VERSION ""

NS_ :

BS_:

BU_: AAF AAF_Tester ABS ACU ADRV AEMC AFLS AHLS APRK AVM BCM CAMERA CGW CLU CUBIS DATC DI_BOX Dummy ECS EMS EPB ESC EVP FATC FPCM FRONT_RADAR HUD IAP IBOX LCA LDWS_LKAS LPI LVR MDPS MTS ODS OPI PGS PSB REA SAS SCC SMK SNV SPAS TCU TMU TPMS _4WD

BS_:

BU_: XXX CAMERA FRONT_RADAR ADRV APRK

BS_:

BU_: IAP ODS _4WD BCM HUD DATC MDPS AAF_Tester AEMC SMK _4WD EPB CUBIS MTS TMU EVP CGW TPMS LPI DI_BOX SPAS EMS LCA TCU IBOX FATC AFLS FPCM SCC AHLS AVM ABS SNV OPI PGS SAS AAF Dummy LDWS_LKAS LVR ESC PSB CLU ECS ACU REA

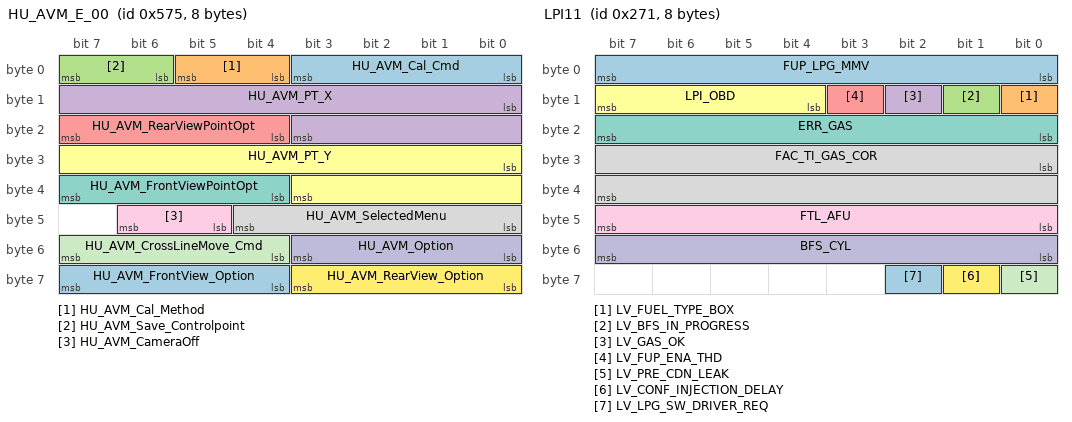
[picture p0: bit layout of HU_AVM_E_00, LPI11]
BO_ 1397 HU_AVM_E_00: 8 CLU
 SG_ HU_AVM_Cal_Cmd : 0|4@1+ (1.0,0.0) [0.0|15.0] ""  AVM,PGS
 SG_ HU_AVM_Cal_Method : 4|2@1+ (1.0,0.0) [0.0|3.0] ""  AVM,PGS
 SG_ HU_AVM_Save_Controlpoint : 6|2@1+ (1.0,0.0) [0.0|3.0] ""  AVM,PGS
 SG_ HU_AVM_PT_X : 8|12@1+ (1.0,0.0) [0.0|15.0] ""  AVM,PGS
 SG_ HU_AVM_RearViewPointOpt : 20|4@1+ (1.0,0.0) [0.0|15.0] ""  AVM,PGS
 SG_ HU_AVM_PT_Y : 24|12@1+ (1.0,0.0) [0.0|4095.0] ""  AVM,PGS
 SG_ HU_AVM_FrontViewPointOpt : 36|4@1+ (1.0,0.0) [0.0|15.0] ""  AVM,PGS
 SG_ HU_AVM_SelectedMenu : 40|5@1+ (1.0,0.0) [0.0|31.0] ""  AVM,PGS
 SG_ HU_AVM_CameraOff : 45|2@1+ (1.0,0.0) [0.0|3.0] ""  AVM,PGS
 SG_ HU_AVM_Option : 48|4@1+ (1.0,0.0) [0.0|15.0] ""  AVM,PGS
 SG_ HU_AVM_CrossLineMove_Cmd : 52|4@1+ (1.0,0.0) [0.0|15.0] ""  AVM,PGS
 SG_ HU_AVM_RearView_Option : 56|4@1+ (1.0,0.0) [0.0|15.0] ""  AVM,PGS
 SG_ HU_AVM_FrontView_Option : 60|4@1+ (1.0,0.0) [0.0|15.0] ""  AVM,PGS

BO_ 1395 HU_AVM_E_01: 8 CLU
 SG_ HU_PGSSelectedMenu : 0|4@1+ (1.0,0.0) [0.0|15.0] ""  AVM,PGS
 SG_ HU_PGSOption : 8|5@1+ (1.0,0.0) [0.0|31.0] ""  AVM,PGS
 SG_ HU_AVM_ParkingAssistMenu : 56|4@1+ (1.0,0.0) [0.0|15.0] ""  AVM,PGS
 SG_ HU_AVM_ParkingAssistSB : 60|4@1+ (1.0,0.0) [0.0|15.0] ""  AVM,PGS

BO_ 1393 OPI11: 5 OPI
 SG_ CR_Opi_Spd_Rpm : 0|8@1+ (20.0,0.0) [0.0|3500.0] "rpm"  TCU
 SG_ CF_Opi_Over_Temp : 8|1@1+ (1.0,0.0) [0.0|1.0] ""  TCU
 SG_ CF_Opi_Over_Cur : 9|1@1+ (1.0,0.0) [0.0|1.0] ""  EMS,TCU
 SG_ CF_Opi_Over_Vol : 10|1@1+ (1.0,0.0) [0.0|1.0] ""  TCU
 SG_ CF_Opi_Hall_Fail : 11|1@1+ (1.0,0.0) [0.0|1.0] ""  EMS,TCU
 SG_ CF_Opi_Flt : 12|1@1+ (1.0,0.0) [0.0|1.0] ""  EMS,TCU
 SG_ CF_Opi_Motor_Dir : 15|1@1+ (1.0,0.0) [0.0|1.0] ""  TCU
 SG_ CF_Opi_Romver : 16|8@1+ (1.0,0.0) [0.0|255.0] ""  TCU
 SG_ CF_Opi_PWM_Rate : 24|12@1+ (1.0,0.0) [0.0|100.0] "%"  TCU

BO_ 625 LPI11: 8 LPI
 SG_ FUP_LPG_MMV : 0|8@1+ (128.0,0.0) [0.0|32640.0] "hPa"  EMS
 SG_ LV_FUEL_TYPE_BOX : 8|1@1+ (1.0,0.0) [0.0|1.0] ""  EMS
 SG_ LV_BFS_IN_PROGRESS : 9|1@1+ (1.0,0.0) [0.0|1.0] ""  EMS
 SG_ LV_GAS_OK : 10|1@1+ (1.0,0.0) [0.0|1.0] ""  EMS
 SG_ LV_FUP_ENA_THD : 11|1@1+ (1.0,0.0) [0.0|1.0] ""  BCM,CLU,EMS,SMK
 SG_ LPI_OBD : 12|4@1+ (1.0,0.0) [0.0|15.0] ""  EMS
 SG_ ERR_GAS : 16|8@1+ (1.0,0.0) [0.0|255.0] ""  EMS
 SG_ FAC_TI_GAS_COR : 24|16@1+ (3.05E-5,0.0) [0.0|1.9988175] ""  EMS
 SG_ FTL_AFU : 40|8@1+ (0.392,0.0) [0.0|99.96] "%"  EMS
 SG_ BFS_CYL : 48|8@1+ (1.0,0.0) [0.0|6.0] "Cyl Nr."  EMS
 SG_ LV_PRE_CDN_LEAK : 56|1@1+ (1.0,0.0) [0.0|1.0] ""  EMS
 SG_ LV_CONF_INJECTION_DELAY : 57|1@1+ (1.0,0.0) [0.0|1.0] ""  EMS
 SG_ LV_LPG_SW_DRIVER_REQ : 58|1@1+ (1.0,0.0) [0.0|1.0] ""  EMS

BO_ 356 VSM11: 4 ESC
 SG_ CR_Esc_StrTqReq : 0|12@1+ (0.01,-20.48) [-20.48|20.47] "Nm"  MDPS
 SG_ CF_Esc_Act : 12|1@1+ (1.0,0.0) [0.0|1.0] ""  LDWS_LKAS,MDPS
 SG_ CF_Esc_CtrMode : 13|3@1+ (1.0,0.0) [0.0|7.0] ""  MDPS
 SG_ CF_Esc_Def : 16|1@1+ (1.0,0.0) [0.0|1.0] ""  MDPS
 SG_ CF_Esc_AliveCnt : 17|4@1+ (1.0,0.0) [0.0|15.0] ""  LDWS_LKAS,MDPS
 SG_ CF_Esc_Chksum : 24|8@1+ (1.0,0.0) [0.0|255.0] ""  LDWS_LKAS,MDPS

BO_ 1379 PGS_HU_PE_01: 8 PGS
 SG_ PGS_State : 0|4@1+ (1.0,0.0) [0.0|15.0] ""  CLU
 SG_ PGS_ParkGuideState : 8|5@1+ (1.0,0.0) [0.0|31.0] ""  CLU
 SG_ PGS_Option : 16|5@1+ (1.0,0.0) [0.0|31.0] ""  CLU
 SG_ PGS_Version : 32|16@1+ (1.0,0.0) [0.0|65535.0] ""  CLU

BO_ 1378 HUD11: 4 HUD
 SG_ CF_Hud_HeightStaus : 0|5@1+ (1.0,0.0) [0.0|31.0] ""  CLU
 SG_ CF_Hud_PBackStatus : 6|2@1+ (1.0,0.0) [0.0|0.0] ""  BCM,CLU
 SG_ CF_Hud_Brightness : 8|5@1+ (1.0,0.0) [0.0|31.0] ""  CLU

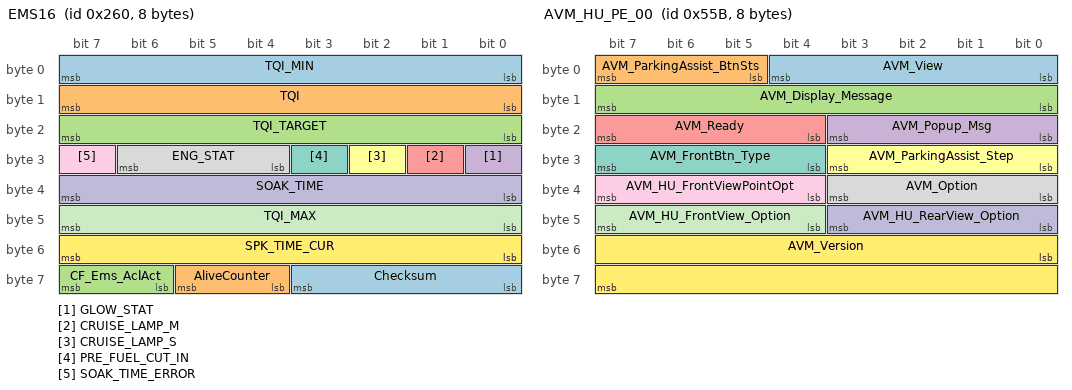
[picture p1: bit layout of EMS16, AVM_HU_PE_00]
BO_ 608 EMS16: 8 EMS
 SG_ TQI_MIN : 0|8@1+ (0.390625,0.0) [0.0|99.609375] "%"  ESC,IBOX,TCU
 SG_ TQI : 8|8@1+ (0.390625,0.0) [0.0|99.609375] "%"  ESC,IBOX,TCU
 SG_ TQI_TARGET : 16|8@1+ (0.390625,0.0) [0.0|99.609375] "%"  EPB,ESC,IBOX,TCU
 SG_ GLOW_STAT : 24|1@1+ (1.0,0.0) [0.0|1.0] ""  BCM,CLU,IBOX,SMK
 SG_ CRUISE_LAMP_M : 25|1@1+ (1.0,0.0) [0.0|1.0] ""  CLU,IBOX,TCU
 SG_ CRUISE_LAMP_S : 26|1@1+ (1.0,0.0) [0.0|1.0] ""  CLU,IBOX,TCU
 SG_ PRE_FUEL_CUT_IN : 27|1@1+ (1.0,0.0) [0.0|1.0] ""  IBOX,TCU
 SG_ ENG_STAT : 28|3@1+ (1.0,0.0) [0.0|7.0] ""  ABS,AHLS,AVM,BCM,CLU,EPB,ESC,EVP,FPCM,IBOX,LCA,LDWS_LKAS,MDPS,SCC,SMK,TCU
 SG_ SOAK_TIME_ERROR : 31|1@1+ (1.0,0.0) [0.0|1.0] ""  DATC,EPB,IBOX,TCU
 SG_ SOAK_TIME : 32|8@1+ (1.0,0.0) [0.0|255.0] "Min"  _4WD,DATC,EPB,IBOX,TCU
 SG_ TQI_MAX : 40|8@1+ (0.390625,0.0) [0.0|99.609375] "%"  ESC,IBOX,TCU
 SG_ SPK_TIME_CUR : 48|8@1+ (0.375,-35.625) [-35.625|60.0] ""  IBOX,TCU
 SG_ Checksum : 56|4@1+ (1.0,0.0) [0.0|15.0] ""  ECS,IBOX,LDWS_LKAS,MDPS,SCC
 SG_ AliveCounter : 60|2@1+ (1.0,0.0) [0.0|3.0] ""  IBOX,LDWS_LKAS,MDPS,SCC
 SG_ CF_Ems_AclAct : 62|2@1+ (1.0,0.0) [0.0|3.0] ""  IBOX,SCC

BO_ 1371 AVM_HU_PE_00: 8 AVM
 SG_ AVM_View : 0|5@1+ (1.0,0.0) [0.0|31.0] ""  CLU
 SG_ AVM_ParkingAssist_BtnSts : 5|3@1+ (1.0,0.0) [0.0|7.0] ""  CLU
 SG_ AVM_Display_Message : 8|8@1+ (1.0,0.0) [0.0|255.0] ""  CLU
 SG_ AVM_Popup_Msg : 16|4@1+ (1.0,0.0) [0.0|15.0] ""  CLU
 SG_ AVM_Ready : 20|4@1+ (1.0,0.0) [0.0|15.0] ""  CLU
 SG_ AVM_ParkingAssist_Step : 24|4@1+ (1.0,0.0) [0.0|15.0] ""  CLU
 SG_ AVM_FrontBtn_Type : 28|4@1+ (1.0,0.0) [0.0|15.0] ""  CLU
 SG_ AVM_Option : 32|4@1+ (1.0,0.0) [0.0|15.0] ""  CLU
 SG_ AVM_HU_FrontViewPointOpt : 36|4@1+ (1.0,0.0) [0.0|15.0] ""  CLU
 SG_ AVM_HU_RearView_Option : 40|4@1+ (1.0,0.0) [0.0|15.0] ""  CLU
 SG_ AVM_HU_FrontView_Option : 44|4@1+ (1.0,0.0) [0.0|15.0] ""  CLU
 SG_ AVM_Version : 48|16@1+ (1.0,0.0) [0.0|65535.0] ""  CLU

BO_ 1370 HU_AVM_PE_00: 8 CLU
 SG_ HU_AVM_Status : 0|2@1+ (1.0,0.0) [0.0|3.0] ""  AVM,PGS

BO_ 1369 CGW4: 8 BCM
 SG_ CF_Gway_MemoryP1Cmd : 0|1@1+ (1.0,0.0) [0.0|1.0] ""  CLU
 SG_ CF_Gway_MemoryP2Cmd : 1|1@1+ (1.0,0.0) [0.0|1.0] ""  CLU
 SG_ CF_Gway_PBackP1Cmd : 2|1@1+ (1.0,0.0) [0.0|1.0] ""  CLU
 SG_ CF_Gway_PBackP2Cmd : 3|1@1+ (1.0,0.0) [0.0|1.0] ""  CLU
 SG_ CF_Gway_StrgWhlHeatedState : 4|1@1+ (1.0,0.0) [0.0|1.0] ""  CLU
 SG_ CF_Gway_PBackStopCmd : 5|1@1+ (1.0,0.0) [0.0|1.0] ""  CLU,HUD
 SG_ CF_Gway_StaticBendLhAct : 6|1@1+ (1.0,0.0) [0.0|1.0] ""  CLU
 SG_ CF_Gway_StaticBendRhAct : 7|1@1+ (1.0,0.0) [0.0|1.0] ""  CLU
 SG_ CF_Gway_DrvWdwStat : 8|1@1+ (1.0,0.0) [0.0|1.0] ""  CLU
 SG_ CF_Gway_RLWdwState : 9|1@1+ (1.0,0.0) [0.0|1.0] ""  CLU
 SG_ CF_Gway_RRWdwState : 10|1@1+ (1.0,0.0) [0.0|1.0] ""  CLU
 SG_ CF_Gway_AstWdwStat : 11|1@1+ (1.0,0.0) [0.0|1.0] ""  CLU
 SG_ CF_Gway_MemoryEnable : 12|1@1+ (1.0,0.0) [0.0|1.0] ""  CLU
 SG_ CF_Gway_PBACKStopCmd : 13|1@1+ (1.0,0.0) [0.0|1.0] ""  CLU
 SG_ CF_Gway_PBACKStop : 14|1@1+ (1.0,0.0) [0.0|1.0] ""  CLU,HUD
 SG_ CF_Gway_IMSBuzzer : 15|1@1+ (1.0,0.0) [0.0|1.0] ""  CLU
 SG_ CF_Gway_DrvSeatBeltInd : 36|2@1+ (1.0,0.0) [0.0|3.0] ""  CLU,Dummy
 SG_ CF_Gway_AstSeatBeltInd : 38|2@1+ (1.0,0.0) [0.0|3.0] ""  CLU
 SG_ CF_Gway_RCSeatBeltInd : 40|2@1+ (1.0,0.0) [0.0|3.0] ""  CLU
 SG_ CF_Gway_RLSeatBeltInd : 42|2@1+ (1.0,0.0) [0.0|3.0] ""  CLU
 SG_ CF_Gway_RRSeatBeltInd : 44|2@1+ (1.0,0.0) [0.0|3.0] ""  CLU
 SG_ CF_Gway_RrWiperHighSw : 46|1@1+ (1.0,0.0) [0.0|1.0] ""  CLU
 SG_ CF_Gway_RrWiperLowSw : 47|1@1+ (1.0,0.0) [0.0|1.0] ""  CLU

BO_ 1367 EngFrzFrm12: 8 EMS
 SG_ PID_06h : 0|8@1+ (0.78125,-100.0) [-100.0|99.22] "%"  AAF,IBOX,TCU
 SG_ PID_07h : 8|8@1+ (0.78125,-100.0) [-100.0|99.22] "%"  AAF,IBOX,TCU
 SG_ PID_08h : 16|8@1+ (0.78125,-100.0) [-100.0|99.22] "%"  AAF,IBOX,TCU
 SG_ PID_09h : 24|8@1+ (0.78125,-100.0) [-100.0|99.22] "%"  AAF,IBOX,TCU
 SG_ PID_0Bh : 32|8@1+ (1.0,0.0) [0.0|255.0] "kPa"  AAF,IBOX,TCU
 SG_ PID_23h : 40|16@1+ (10.0,0.0) [0.0|655350.0] "kPa"  AAF,IBOX,TCU

BO_ 1366 EngFrzFrm11: 8 EMS
 SG_ PID_04h : 0|8@1+ (0.3921568627,0.0) [0.0|100.0] "%"  AAF,TCU
 SG_ PID_05h : 8|8@1+ (1.0,-40.0) [-40.0|215.0] "deg"  AAF,TCU
 SG_ PID_0Ch : 16|16@1+ (0.25,0.0) [0.0|16383.75] "rpm"  AAF,TCU
 SG_ PID_0Dh : 32|8@1+ (1.0,0.0) [0.0|255.0] "km/h"  AAF,TCU
 SG_ PID_11h : 40|8@1+ (0.3921568627,0.0) [0.0|100.0] "%"  AAF,TCU
 SG_ PID_03h : 48|16@1+ (1.0,0.0) [0.0|65535.0] ""  AAF,TCU

BO_ 1365 FPCM11: 8 FPCM
 SG_ CR_Fpcm_LPActPre : 0|8@1+ (3.137254902,0.0) [0.0|800.0] "kPa"  EMS
 SG_ CF_Fpcm_LPPumpOverCur : 8|1@1+ (1.0,0.0) [0.0|1.0] ""  EMS
 SG_ CF_Fpcm_PreSnrHi : 9|1@1+ (1.0,0.0) [0.0|1.0] ""  EMS
 SG_ CF_Fpcm_PreSnrDisc : 10|1@1+ (1.0,0.0) [0.0|1.0] ""  EMS
 SG_ CF_Fpcm_PreSnrShort : 11|1@1+ (1.0,0.0) [0.0|1.0] ""  EMS
 SG_ CF_Fpcm_LPPumpDiscShort : 12|1@1+ (1.0,0.0) [0.0|1.0] ""  EMS
 SG_ CF_Fpcm_LP_System_Error : 13|1@1+ (1.0,0.0) [0.0|1.0] ""  EMS
 SG_ CF_Fpcm_PreSnrSigErr : 14|1@1+ (1.0,0.0) [0.0|1.0] ""  EMS
 SG_ CF_Fpcm_LPCtrCirFlt : 15|1@1+ (1.0,0.0) [0.0|1.0] ""  EMS

BO_ 871 LVR12: 8 LVR
 SG_ CF_Lvr_CruiseSet : 0|8@1+ (1.0,0.0) [0.0|255.0] "" CLU,TCU
 SG_ CF_Lvr_IsgState : 8|2@1+ (1.0,0.0) [0.0|3.0] "" CLU,TCU
 SG_ CF_Lvr_Gear : 32|4@1+ (1.0,0.0) [0.0|15.0] ""  CLU,TCU

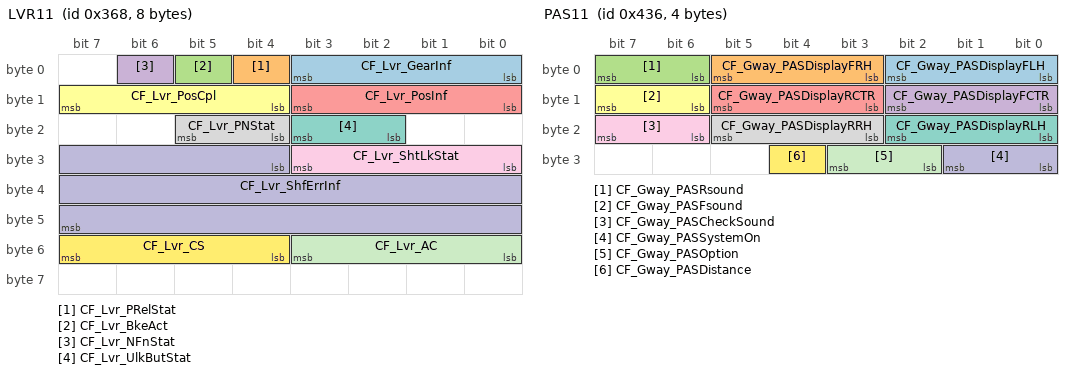
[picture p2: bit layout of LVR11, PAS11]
BO_ 872 LVR11: 8 LVR
 SG_ CF_Lvr_GearInf : 0|4@1+ (1.0,0.0) [0.0|15.0] ""  CLU,TCU
 SG_ CF_Lvr_PRelStat : 4|1@1+ (1.0,0.0) [0.0|1.0] ""  BCM,CLU,SMK,TCU
 SG_ CF_Lvr_BkeAct : 5|1@1+ (1.0,0.0) [0.0|1.0] ""  TCU
 SG_ CF_Lvr_NFnStat : 6|1@1+ (1.0,0.0) [0.0|1.0] ""  CLU
 SG_ CF_Lvr_PosInf : 8|4@1+ (1.0,0.0) [0.0|15.0] ""  TCU
 SG_ CF_Lvr_PosCpl : 12|4@1+ (1.0,0.0) [0.0|15.0] ""  TCU
 SG_ CF_Lvr_UlkButStat : 18|2@1+ (1.0,0.0) [0.0|3.0] ""  TCU
 SG_ CF_Lvr_PNStat : 20|2@1+ (1.0,0.0) [0.0|3.0] ""  CLU
 SG_ CF_Lvr_ShtLkStat : 24|4@1+ (1.0,0.0) [0.0|15.0] ""  TCU
 SG_ CF_Lvr_ShfErrInf : 28|20@1+ (1.0,0.0) [0.0|8191.0] ""  CLU,TCU
 SG_ CF_Lvr_AC : 48|4@1+ (1.0,0.0) [0.0|15.0] ""  TCU
 SG_ CF_Lvr_CS : 52|4@1+ (1.0,0.0) [0.0|15.0] ""  TCU

BO_ 1363 CGW2: 8 BCM
 SG_ CF_Gway_GwayDiagState : 0|1@1+ (1.0,0.0) [0.0|3.0] ""  CLU,Dummy
 SG_ CF_Gway_DDMDiagState : 1|1@1+ (1.0,0.0) [0.0|1.0] ""  CLU,Dummy
 SG_ CF_Gway_SCMDiagState : 2|1@1+ (1.0,0.0) [0.0|1.0] ""  CLU,Dummy
 SG_ CF_Gway_PSMDiagState : 3|1@1+ (1.0,0.0) [0.0|1.0] ""  CLU,Dummy
 SG_ CF_Gway_SJBDiagState : 4|1@1+ (1.0,0.0) [0.0|1.0] ""  CLU,Dummy
 SG_ CF_Gway_IPMDiagState : 5|1@1+ (1.0,0.0) [0.0|1.0] ""  CLU,Dummy
 SG_ CF_Gway_LDMFail : 6|2@1+ (1.0,0.0) [0.0|3.0] ""  CLU,LDWS_LKAS,LDWS_LKAS
 SG_ CF_Gway_CLUSwGuiCtrl : 10|3@1+ (1.0,0.0) [0.0|63.0] ""  CLU,Dummy
 SG_ CF_Gway_CLUSwGroup : 13|1@1+ (1.0,0.0) [0.0|1.0] ""  CLU,Dummy
 SG_ CF_Gway_CLUSwMode : 14|1@1+ (1.0,0.0) [0.0|1.0] ""  CLU,Dummy
 SG_ CF_Gway_CLUSwEnter : 15|1@1+ (1.0,0.0) [0.0|1.0] ""  CLU,Dummy
 SG_ CF_Gway_AutoLightValue : 16|1@1+ (1.0,0.0) [0.0|1.0] ""  LCA,LCA
 SG_ CF_Gway_BrakeFluidSw : 17|1@1+ (1.0,0.0) [0.0|1.0] ""  CLU,Dummy
 SG_ CF_Gway_DrvSeatBeltInd : 18|2@1+ (1.0,0.0) [0.0|3.0] ""  CLU
 SG_ CF_Gway_AvTail : 20|1@1+ (1.0,0.0) [0.0|3.0] ""  CLU,SNV,SNV
 SG_ CF_Gway_RearFogAct : 21|1@1+ (1.0,0.0) [0.0|1.0] ""  CLU,Dummy
 SG_ CF_Gway_ExtTailAct : 22|1@1+ (1.0,0.0) [0.0|1.0] ""  AVM,CLU,LCA,PGS,SPAS,AVM,LCA,PGS,SPAS
 SG_ CF_Gway_RRDrSw : 23|1@1+ (1.0,0.0) [0.0|1.0] ""  CLU,Dummy
 SG_ CF_Gway_RLDrSw : 24|1@1+ (1.0,0.0) [0.0|1.0] ""  CLU,Dummy
 SG_ CF_Gway_IntTailAct : 25|1@1+ (1.0,0.0) [0.0|1.0] ""  CLU,Dummy
 SG_ CF_Gway_CountryCfg : 26|3@1+ (1.0,0.0) [0.0|7.0] ""  AVM,CLU,PGS,Dummy
 SG_ CF_Gway_WiperParkPosition : 32|1@1+ (1.0,0.0) [0.0|1.0] ""  AFLS,EMS,LDWS_LKAS,AFLS,EMS,LDWS_LKAS
 SG_ CF_Gway_HLLowLHFail : 33|1@1+ (1.0,0.0) [0.0|1.0] ""  LDWS_LKAS,SNV,LDWS_LKAS,SNV
 SG_ CF_Gway_HLLowRHFail : 34|1@1+ (1.0,0.0) [0.0|1.0] ""  LDWS_LKAS,SNV,LDWS_LKAS,SNV
 SG_ CF_Gway_ESCLFailWarn : 35|1@1+ (1.0,0.0) [0.0|1.0] ""  CLU,Dummy
 SG_ CF_Gway_ESCLNotLockedWarn : 36|1@1+ (1.0,0.0) [0.0|1.0] ""  CLU,Dummy
 SG_ CF_Gway_ESCLNotUnlockWarn : 37|1@1+ (1.0,0.0) [0.0|1.0] ""  CLU,Dummy
 SG_ CF_Gway_IDoutWarn : 38|1@1+ (1.0,0.0) [0.0|1.0] ""  CLU,Dummy
 SG_ CF_Gway_ImmoLp : 40|1@1+ (1.0,0.0) [0.0|3.0] ""  CLU,Dummy
 SG_ CF_Gway_BCMRKEID : 41|3@1+ (1.0,0.0) [0.0|7.0] ""  CLU,Dummy
 SG_ CF_Gway_VehicleNotPWarn : 44|1@1+ (1.0,0.0) [0.0|1.0] ""  CLU,Dummy
 SG_ CF_Gway_DeactivationWarn : 45|1@1+ (1.0,0.0) [0.0|1.0] ""  CLU,Dummy
 SG_ CF_Gway_KeyBATDischargeWarn : 46|1@1+ (1.0,0.0) [0.0|1.0] ""  CLU,Dummy
 SG_ CF_Gway_SSBWarn : 47|1@1+ (1.0,0.0) [0.0|1.0] ""  CLU,Dummy
 SG_ CF_Gway_SMKFobID : 48|3@1+ (1.0,0.0) [0.0|7.0] ""  CLU,Dummy
 SG_ CF_Gway_SMKRKECmd : 51|3@1+ (1.0,0.0) [0.0|7.0] ""  CLU,Dummy
 SG_ CF_Gway_AutoLightOption : 54|1@1+ (1.0,0.0) [0.0|1.0] ""  CLU
 SG_ CF_Gway_SJBDeliveryMode : 55|1@1+ (1.0,0.0) [0.0|1.0] ""  CLU,Dummy
 SG_ CF_Gway_KeyoutLp : 56|1@1+ (1.0,0.0) [0.0|1.0] ""  CLU,Dummy
 SG_ CF_Gway_SMKDispWarn : 57|4@1+ (1.0,0.0) [0.0|15.0] ""  CLU,Dummy
 SG_ CF_Gway_WngBuz : 61|3@1+ (1.0,0.0) [0.0|7.0] ""  CLU,Dummy

BO_ 339 TCS11: 8 ESC
 SG_ TCS_REQ : 0|1@1+ (1.0,0.0) [0.0|1.0] ""  _4WD,EMS,EPB,TCU
 SG_ MSR_C_REQ : 1|1@1+ (1.0,0.0) [0.0|1.0] ""  EMS,EPB,SCC,TCU
 SG_ TCS_PAS : 2|1@1+ (1.0,0.0) [0.0|1.0] ""  _4WD,CLU,EMS,SCC,SPAS,TCU
 SG_ TCS_GSC : 3|1@1+ (1.0,0.0) [0.0|1.0] ""  _4WD,EMS,TCU
 SG_ CF_Esc_LimoInfo : 4|2@1+ (1.0,0.0) [0.0|3.0] ""  _4WD,SCC
 SG_ ABS_DIAG : 6|1@1+ (1.0,0.0) [0.0|1.0] ""  _4WD,CLU,EMS,EPB
 SG_ ABS_DEF : 7|1@1+ (1.0,0.0) [0.0|1.0] ""  _4WD,ACU,ECS,EMS,EPB,SCC,SPAS,TCU
 SG_ TCS_DEF : 8|1@1+ (1.0,0.0) [0.0|1.0] ""  _4WD,EMS,EPB,SCC,SPAS,TCU
 SG_ TCS_CTL : 9|1@1+ (1.0,0.0) [0.0|1.0] ""  _4WD,EMS,EPB,SCC,SPAS,TCU
 SG_ ABS_ACT : 10|1@1+ (1.0,0.0) [0.0|1.0] ""  _4WD,ACU,ECS,EMS,EPB,LDWS_LKAS,SCC,SPAS,TCU
 SG_ EBD_DEF : 11|1@1+ (1.0,0.0) [0.0|1.0] ""  _4WD,EMS,EPB,SPAS,TCU
 SG_ ESP_PAS : 12|1@1+ (1.0,0.0) [0.0|1.0] ""  _4WD,ACU,CLU,EMS,EPB,LDWS_LKAS,SCC,TCU
 SG_ ESP_DEF : 13|1@1+ (1.0,0.0) [0.0|1.0] ""  _4WD,ACU,ECS,EMS,EPB,LDWS_LKAS,SCC,TCU
 SG_ ESP_CTL : 14|1@1+ (1.0,0.0) [0.0|1.0] ""  _4WD,ACU,ECS,EMS,EPB,LDWS_LKAS,SCC,SPAS,TCU
 SG_ TCS_MFRN : 15|1@1+ (1.0,0.0) [0.0|1.0] ""  EMS,EPB,TCU
 SG_ DBC_CTL : 16|1@1+ (1.0,0.0) [0.0|1.0] ""  _4WD,EMS,EPB
 SG_ DBC_PAS : 17|1@1+ (1.0,0.0) [0.0|1.0] ""  _4WD,EMS,EPB
 SG_ DBC_DEF : 18|1@1+ (1.0,0.0) [0.0|1.0] ""  _4WD,EMS,EPB
 SG_ HAC_CTL : 19|1@1+ (1.0,0.0) [0.0|1.0] ""  _4WD,CLU,EMS,EPB,TCU
 SG_ HAC_PAS : 20|1@1+ (1.0,0.0) [0.0|1.0] ""  _4WD,CLU,EMS,EPB,TCU
 SG_ HAC_DEF : 21|1@1+ (1.0,0.0) [0.0|1.0] ""  _4WD,CLU,EMS,EPB,TCU
 SG_ ESS_STAT : 22|2@1+ (1.0,0.0) [0.0|3.0] ""  _4WD,BCM,CLU,EMS,EPB
 SG_ TQI_TCS : 24|8@1+ (0.390625,0.0) [0.0|99.609375] "%"  EMS,EPB,TCU
 SG_ TQI_MSR : 32|8@1+ (0.390625,0.0) [0.0|99.609375] "%"  EMS,EPB,TCU
 SG_ TQI_SLW_TCS : 40|8@1+ (0.390625,0.0) [0.0|99.609375] "%"  EMS,EPB,TCU
 SG_ CF_Esc_BrkCtl : 48|1@1+ (1.0,0.0) [0.0|1.0] ""  EMS
 SG_ BLA_CTL : 49|2@1+ (1.0,0.0) [0.0|3.0] ""  BCM,CGW,CLU
 SG_ AliveCounter_TCS1 : 52|4@1+ (1.0,0.0) [0.0|14.0] ""  EMS,EPB,LDWS_LKAS
 SG_ CheckSum_TCS1 : 56|8@1+ (1.0,0.0) [0.0|255.0] ""  EMS,EPB,LDWS_LKAS

BO_ 1362 SNV11: 4 SNV
 SG_ CF_SNV_DisplayControl : 0|2@1+ (1.0,0.0) [0.0|3.0] ""  CLU,HUD
 SG_ CF_Snv_BeepWarning : 2|2@1+ (1.0,0.0) [0.0|3.0] ""  CLU,HUD
 SG_ CF_Snv_WarningMessage : 4|3@1+ (1.0,0.0) [0.0|7.0] ""  CLU,HUD
 SG_ CF_Snv_DetectionEnable : 7|1@1+ (1.0,0.0) [0.0|1.0] ""  BCM,CLU,HUD
 SG_ CF_Snv_PedestrianDetect : 8|2@1+ (1.0,0.0) [0.0|3.0] ""  BCM,CLU,HUD
 SG_ CF_Snv_IRLampControl : 10|2@1+ (1.0,0.0) [0.0|3.0] ""  BCM,CLU,HUD

BO_ 1360 IAP11: 3 IAP
 SG_ CF_Iap_EcoPmodSwi : 0|1@1+ (1.0,0.0) [0.0|1.0] ""  CLU
 SG_ CF_Iap_EcoPmodAct : 1|1@1+ (1.0,0.0) [0.0|1.0] ""  CLU
 SG_ CF_Iap_ReqWarn : 2|2@1+ (1.0,0.0) [0.0|3.0] ""  CLU

BO_ 1356 TCU_DCT14: 8 TCU
 SG_ Vehicle_Stop_Time : 0|5@1+ (1.0,0.0) [0.0|0.0] ""  CLU
 SG_ HILL_HOLD_WARNING : 5|1@1+ (1.0,0.0) [0.0|0.0] ""  CLU

BO_ 1353 BAT11: 8 EMS
 SG_ BAT_SNSR_I : 0|16@1+ (0.01,-327.0) [-327.0|328.0] "A"  CGW,CUBIS,IBOX,TMU
 SG_ BAT_SOC : 16|8@1+ (1.0,0.0) [0.0|100.0] "%"  CGW,CUBIS,IBOX,TMU
 SG_ BAT_SNSR_V : 24|14@1+ (0.0010,6.0) [6.0|18.0] "V"  CGW,CUBIS,IBOX,TMU
 SG_ BAT_SNSR_Temp : 38|9@1- (0.5,-40.0) [-40.0|125.0] "deg"  CGW,CUBIS,IBOX,TMU
 SG_ BAT_SNSR_State : 47|1@1+ (1.0,0.0) [0.0|1.0] ""  CGW,CUBIS,IBOX,TMU
 SG_ BAT_SOH : 48|7@1+ (1.0,0.0) [0.0|100.0] "%"  CGW,CUBIS,IBOX,TMU
 SG_ BAT_SNSR_Invalid : 55|1@1+ (1.0,0.0) [0.0|1.0] ""  CGW,CUBIS,IBOX,TMU
 SG_ BAT_SOF : 56|7@1+ (0.1,0.0) [0.0|12.0] "V"  CGW,CUBIS,IBOX,TMU
 SG_ BAT_SNSR_Error : 63|1@1+ (1.0,0.0) [0.0|1.0] ""  CGW,CUBIS,IBOX,TMU

BO_ 1351 EMS15: 8 EMS
 SG_ ECGPOvrd : 0|1@1+ (1.0,0.0) [0.0|1.0] ""  ESC,IBOX,SCC
 SG_ QECACC : 1|1@1+ (1.0,0.0) [0.0|1.0] ""  ESC,IBOX
 SG_ ECFail : 2|1@1+ (1.0,0.0) [0.0|1.0] ""  ESC,IBOX
 SG_ SwitchOffCondExt : 3|1@1+ (1.0,0.0) [0.0|1.0] ""  ESC,IBOX
 SG_ BLECFail : 4|1@1+ (1.0,0.0) [0.0|1.0] ""  ESC,IBOX
 SG_ CF_Ems_IsaAct : 5|1@1+ (1.0,0.0) [0.0|1.0] ""  CLU
 SG_ FA_PV_CAN : 8|8@1+ (0.3906,0.0) [0.0|99.2] "%"  IBOX,LDWS_LKAS,TCU
 SG_ IntAirTemp : 16|8@1+ (0.75,-48.0) [-48.0|143.25] "deg"  _4WD,ECS,EPB,IBOX,TCU
 SG_ STATE_DC_OBD : 24|7@1+ (1.0,0.0) [0.0|127.0] ""  IBOX,TCU
 SG_ INH_DC_OBD : 31|1@1+ (1.0,0.0) [0.0|1.0] ""  IBOX,TCU
 SG_ CTR_IG_CYC_OBD : 32|16@1+ (1.0,0.0) [0.0|65535.0] ""  ACU,IBOX,TCU
 SG_ CTR_CDN_OBD : 48|16@1+ (1.0,0.0) [0.0|65535.0] ""  IBOX,TCU

BO_ 1350 DI_BOX12: 8 DI_BOX
 SG_ CF_DiBox_FrtInjVDiagReg0 : 0|8@1+ (1.0,0.0) [0.0|255.0] ""  EMS
 SG_ CF_DiBox_FrtInjVDiagReg1 : 8|8@1+ (1.0,0.0) [0.0|255.0] ""  EMS
 SG_ CF_DiBox_FrtInjVDiagReg2 : 16|8@1+ (1.0,0.0) [0.0|255.0] ""  EMS
 SG_ CF_DiBox_SedInjVDiagReg0 : 24|8@1+ (1.0,0.0) [0.0|255.0] ""  EMS
 SG_ CF_DiBox_SedInjVDiagReg1 : 32|8@1+ (1.0,0.0) [0.0|255.0] ""  EMS
 SG_ CF_DiBox_SedInjVDiagReg2 : 40|8@1+ (1.0,0.0) [0.0|255.0] ""  EMS
 SG_ CR_DiBox_BatVol : 48|8@1+ (0.1,0.0) [0.0|25.5] "V"  EMS
 SG_ CF_DiBox_SedInjVChg : 56|1@1+ (1.0,0.0) [0.0|1.0] ""  EMS
 SG_ CF_DiBox_FrtInjVChg : 57|1@1+ (1.0,0.0) [0.0|1.0] ""  EMS
 SG_ CF_DiBox_SedInjVErrSPI : 58|1@1+ (1.0,0.0) [0.0|1.0] ""  EMS
 SG_ CF_DiBox_FrtInjVErrSPI : 59|1@1+ (1.0,0.0) [0.0|1.0] ""  EMS

BO_ 1349 EMS14: 8 EMS
 SG_ IMMO_LAMP_STAT : 0|1@1+ (1.0,0.0) [0.0|1.0] ""  CLU,IBOX
 SG_ L_MIL : 1|1@1+ (1.0,0.0) [0.0|1.0] ""  CLU,CUBIS,IBOX
 SG_ IM_STAT : 2|1@1+ (1.0,0.0) [0.0|1.0] ""  CLU,IBOX
 SG_ AMP_CAN : 3|5@1+ (10.731613,458.98) [458.98|791.660003] "mmHg"  CLU,IBOX,TCU,TPMS
 SG_ BAT_Alt_FR_Duty : 8|8@1+ (0.4,0.0) [0.0|100.0] "%"  CGW,CUBIS,IBOX,TMU
 SG_ VB : 24|8@1+ (0.1015625,0.0) [0.0|25.8984375] "V"  CLU,CUBIS,DATC,EPB,FPCM,IBOX
 SG_ EMS_VS : 32|12@1+ (0.0625,0.0) [0.0|255.875] "km/h"  CLU
 SG_ TEMP_FUEL : 56|8@1+ (0.75,-48.0) [-48.0|143.25] "deg"  FPCM

BO_ 68 DATC11: 8 DATC
 SG_ CF_Datc_Type : 0|8@1+ (1.0,0.0) [0.0|255.0] ""  CLU
 SG_ CF_Datc_VerMaj : 8|8@1+ (1.0,0.0) [0.0|255.0] ""  CLU
 SG_ CF_Datc_VerMin : 16|8@1+ (1.0,0.0) [0.0|255.0] ""  CLU
 SG_ CR_Datc_OutTempC : 24|8@1+ (0.5,-41.0) [-41.0|86.5] "deg"  CLU,FPCM
 SG_ CR_Datc_OutTempF : 32|8@1+ (1.0,-42.0) [-42.0|213.0] "deg"  CLU
 SG_ CF_Datc_IncarTemp : 40|8@1+ (0.5,-40.0) [-40.0|60.0] "deg"  BCM,CLU

BO_ 67 DATC13: 8 DATC
 SG_ CF_Datc_TempDispUnit : 0|2@1+ (1.0,0.0) [0.0|3.0] ""  CLU,IBOX
 SG_ CF_Datc_ModDisp : 2|4@1+ (1.0,0.0) [0.0|15.0] ""  CLU
 SG_ CF_Datc_IonClean : 6|2@1+ (1.0,0.0) [0.0|3.0] ""  CLU
 SG_ CF_Datc_ChgReqDisp : 8|2@1+ (1.0,0.0) [0.0|3.0] ""  CLU
 SG_ CF_Datc_IntakeDisp : 10|2@1+ (1.0,0.0) [0.0|3.0] ""  CLU
 SG_ CF_Datc_AutoDisp : 12|2@1+ (1.0,0.0) [0.0|3.0] ""  CLU
 SG_ CF_Datc_FrDefLed : 14|2@1+ (1.0,0.0) [0.0|3.0] ""  CLU,IBOX
 SG_ CF_Datc_AutoDefogBlink : 16|2@1+ (1.0,0.0) [0.0|3.0] ""  CLU
 SG_ CF_Datc_ClmScanDisp : 18|2@1+ (1.0,0.0) [0.0|3.0] ""  CLU
 SG_ CF_Datc_AqsDisp : 20|2@1+ (1.0,0.0) [0.0|3.0] ""  CLU
 SG_ CF_Datc_AcDisp : 22|2@1+ (1.0,0.0) [0.0|3.0] ""  CLU
 SG_ CF_Datc_OpSts : 25|3@1+ (1.0,0.0) [0.0|7.0] ""  CLU
 SG_ CF_Mtc_MaxAcDisp : 28|2@1+ (1.0,0.0) [0.0|3.0] ""  CLU
 SG_ CF_Datc_DualDisp : 30|2@1+ (1.0,0.0) [0.0|3.0] ""  CLU
 SG_ CF_Datc_PwrInf : 32|4@1+ (1.0,0.0) [0.0|15.0] ""  CLU
 SG_ CF_Datc_RearManual : 38|2@1+ (1.0,0.0) [0.0|3.0] ""  CLU
 SG_ CF_Datc_RearAutoDisp : 40|2@1+ (1.0,0.0) [0.0|1.0] ""  CLU
 SG_ CF_Datc_RearOffDisp : 42|2@1+ (1.0,0.0) [0.0|3.0] ""  CLU
 SG_ CF_Datc_RearClimateScnDisp : 44|2@1+ (1.0,0.0) [0.0|3.0] ""  CLU
 SG_ CF_Datc_RearChgReqDisp : 46|2@1+ (1.0,0.0) [0.0|3.0] ""  CLU
 SG_ CF_Datc_RearModDisp : 48|4@1+ (1.0,0.0) [0.0|15.0] ""  CLU
 SG_ CF_Datc_RearBlwDisp : 52|4@1+ (1.0,0.0) [0.0|15.0] ""  CLU
 SG_ CF_Datc_PSModDisp : 56|4@1+ (1.0,0.0) [0.0|15.0] ""  CLU
 SG_ CF_Datc_FrontBlwDisp : 60|4@1+ (1.0,0.0) [0.0|15.0] ""  CLU,IBOX

BO_ 66 DATC12: 8 DATC
 SG_ CR_Datc_DrTempDispC : 0|8@1+ (0.5,14.0) [15.0|32.0] "deg"  CLU,IBOX
 SG_ CR_Datc_DrTempDispF : 8|8@1+ (1.0,56.0) [58.0|90.0] "deg"  CLU,IBOX
 SG_ CR_Datc_PsTempDispC : 16|8@1+ (0.5,14.0) [15.0|32.0] "deg"  CLU,IBOX
 SG_ CR_Datc_PsTempDispF : 24|8@1+ (1.0,56.0) [58.0|90.0] "deg"  CLU,IBOX
 SG_ CR_Datc_RearDrTempDispC : 40|8@1+ (0.5,14.0) [15.0|32.0] "deg"  CLU
 SG_ CR_Datc_RearDrTempDispF : 48|8@1+ (1.0,58.0) [58.0|90.0] "deg"  CLU
 SG_ CF_Datc_CO2_Warning : 56|8@1+ (1.0,0.0) [0.0|3.0] ""  CLU

BO_ 1345 CGW1: 8 BCM
 SG_ CF_Gway_IGNSw : 0|3@1+ (1.0,0.0) [0.0|7.0] ""  AVM,CLU,ECS,EMS,EPB,ESC,IBOX,LVR,MDPS,SAS,SCC,ECS,EMS,EPB,ESC,IBOX,LVR,MDPS,SAS,SCC
 SG_ CF_Gway_RKECmd : 3|3@1+ (1.0,0.0) [0.0|7.0] ""  CLU,ECS,EMS,IBOX,ECS,EMS,IBOX
 SG_ CF_Gway_DrvKeyLockSw : 6|1@1+ (1.0,0.0) [0.0|1.0] ""  ECS,EMS,IBOX,ECS,EMS,IBOX
 SG_ CF_Gway_DrvKeyUnlockSw : 7|1@1+ (1.0,0.0) [0.0|1.0] ""  ECS,EMS,IBOX,ECS,EMS,IBOX
 SG_ CF_Gway_DrvDrSw : 8|2@1+ (1.0,0.0) [0.0|3.0] ""  CLU,ECS,EMS,EPB,ESC,IBOX,SCC,TCU,ECS,EMS,EPB,ESC,IBOX,SCC,TCU
 SG_ CF_Gway_DrvSeatBeltSw : 10|2@1+ (1.0,0.0) [0.0|3.0] ""  EMS,EPB,ESC,IBOX,PSB,TCU,EMS,EPB,ESC,IBOX,PSB,TCU
 SG_ CF_Gway_TrunkTgSw : 12|2@1+ (1.0,0.0) [0.0|3.0] ""  CLU,ECS,EMS,EPB,ESC,IBOX,ECS,EMS,EPB,ESC,IBOX
 SG_ CF_Gway_AstSeatBeltSw : 14|2@1+ (1.0,0.0) [0.0|3.0] ""  IBOX,PSB,IBOX,PSB
 SG_ CF_Gway_SMKOption : 16|1@1+ (1.0,0.0) [0.0|1.0] ""  CLU,EMS,IBOX,EMS,IBOX,SMK
 SG_ CF_Gway_HoodSw : 17|2@1+ (1.0,0.0) [0.0|3.0] ""  CLU,EMS,EPB,ESC,IBOX,EMS,EPB,ESC,IBOX
 SG_ CF_Gway_TurnSigLh : 19|2@1+ (1.0,0.0) [0.0|3.0] ""  CLU,EMS,IBOX,LCA,LDWS_LKAS,SCC,EMS,IBOX,LCA,LDWS_LKAS,SCC
 SG_ CF_Gway_WiperIntT : 21|3@1+ (1.0,0.0) [0.0|7.0] ""  CLU,EMS,IBOX,LDWS_LKAS,EMS,ESC,IBOX,LDWS_LKAS
 SG_ CF_Gway_WiperIntSw : 24|1@1+ (1.0,0.0) [0.0|1.0] ""  CLU,EMS,IBOX,LDWS_LKAS,EMS,ESC,IBOX,LDWS_LKAS
 SG_ CF_Gway_WiperLowSw : 25|1@1+ (1.0,0.0) [0.0|1.0] ""  CLU,EMS,IBOX,LDWS_LKAS,EMS,ESC,IBOX,LDWS_LKAS
 SG_ CF_Gway_WiperHighSw : 26|1@1+ (1.0,0.0) [0.0|1.0] ""  CLU,EMS,IBOX,LDWS_LKAS,EMS,ESC,IBOX,LDWS_LKAS
 SG_ CF_Gway_WiperAutoSw : 27|1@1+ (1.0,0.0) [0.0|1.0] ""  CLU,EMS,IBOX,LDWS_LKAS,EMS,ESC,IBOX,LDWS_LKAS
 SG_ CF_Gway_RainSnsState : 28|3@1+ (1.0,0.0) [0.0|7.0] ""  AFLS,EMS,IBOX,LDWS_LKAS,AFLS,EMS,ESC,IBOX,LDWS_LKAS
 SG_ CF_Gway_HeadLampLow : 31|1@1+ (1.0,0.0) [0.0|1.0] ""  AFLS,CLU,EMS,IBOX,LDWS_LKAS,SNV,AFLS,EMS,IBOX,LDWS_LKAS,SNV
 SG_ CF_Gway_HeadLampHigh : 32|1@1+ (1.0,0.0) [0.0|1.0] ""  AFLS,CLU,EMS,IBOX,LDWS_LKAS,AFLS,EMS,IBOX,LDWS_LKAS
 SG_ CF_Gway_HazardSw : 33|2@1+ (1.0,0.0) [0.0|3.0] ""  ABS,EMS,ESC,IBOX,LCA,LDWS_LKAS,ABS,EMS,ESC,IBOX,LCA,LDWS_LKAS
 SG_ CF_Gway_AstDrSw : 35|1@1+ (1.0,0.0) [0.0|1.0] ""  CLU,IBOX,IBOX
 SG_ CF_Gway_DefoggerRly : 36|1@1+ (1.0,0.0) [0.0|1.0] ""  EMS,IBOX,EMS,IBOX
 SG_ CF_Gway_ALightStat : 37|1@1+ (1.0,0.0) [0.0|1.0] ""  AFLS,IBOX,LDWS_LKAS,AFLS,IBOX,LDWS_LKAS
 SG_ CF_Gway_LightSwState : 38|2@1+ (1.0,0.0) [0.0|3.0] ""  AFLS,IBOX,LDWS_LKAS,AFLS,IBOX,LDWS_LKAS
 SG_ CF_Gway_Frt_Fog_Act : 40|1@1+ (1.0,0.0) [0.0|1.0] ""  AFLS,CLU,IBOX,LDWS_LKAS,AFLS,IBOX,LDWS_LKAS
 SG_ CF_Gway_TSigRHSw : 41|1@1+ (1.0,0.0) [0.0|1.0] ""  IBOX,LDWS_LKAS,IBOX,LDWS_LKAS
 SG_ CF_Gway_TSigLHSw : 42|1@1+ (1.0,0.0) [0.0|1.0] ""  IBOX,LDWS_LKAS,IBOX,LDWS_LKAS
 SG_ CF_Gway_DriveTypeOption : 43|1@1+ (1.0,0.0) [0.0|1.0] ""  CLU,IBOX,LDWS_LKAS,IBOX,LDWS_LKAS
 SG_ CF_Gway_StarterRlyState : 44|1@1+ (1.0,0.0) [0.0|1.0] ""  EMS,IBOX,EMS,IBOX,SMK
 SG_ CF_Gway_PassiveAccessLock : 45|2@1+ (1.0,0.0) [0.0|7.0] ""  CLU,ECS,EMS,IBOX,ECS,EMS,IBOX,SMK
 SG_ CF_Gway_WiperMistSw : 47|1@1+ (1.0,0.0) [0.0|1.0] ""  CLU,EMS,IBOX,LDWS_LKAS
 SG_ CF_Gway_PassiveAccessUnlock : 48|2@1+ (1.0,0.0) [0.0|7.0] ""  CLU,ECS,EMS,IBOX,ECS,EMS,IBOX,SMK
 SG_ CF_Gway_RrSunRoofOpenState : 50|1@1+ (1.0,0.0) [0.0|1.0] ""  CLU,DATC,IBOX
 SG_ CF_Gway_PassingSW : 51|1@1+ (1.0,0.0) [0.0|1.0] ""  AFLS,IBOX,LDWS_LKAS,AFLS,IBOX,LDWS_LKAS
 SG_ CF_Gway_HBAControlMode : 52|1@1+ (1.0,0.0) [0.0|1.0] ""  IBOX,LDWS_LKAS,IBOX,LDWS_LKAS
 SG_ CF_Gway_HLpHighSw : 53|1@1+ (1.0,0.0) [0.0|1.0] ""  IBOX,LDWS_LKAS,IBOX,LDWS_LKAS
 SG_ CF_Gway_InhibitRMT : 54|2@1+ (1.0,0.0) [0.0|3.0] ""  EMS,EPB,ESC,IBOX,LCA,LDWS_LKAS,MDPS,PGS,SCC,SPAS,TPMS,EPB,ESC,IBOX,LCA,LDWS_LKAS,PGS,SCC,SPAS,TPMS
 SG_ CF_Gway_RainSnsOption : 56|1@1+ (1.0,0.0) [0.0|1.0] ""  CLU
 SG_ C_SunRoofOpenState : 57|1@1+ (1.0,0.0) [0.0|1.0] ""  CLU,DATC,IBOX,DATC,IBOX
 SG_ CF_Gway_Ign1 : 58|1@1+ (1.0,0.0) [0.0|1.0] ""  CLU
 SG_ CF_Gway_Ign2 : 59|1@1+ (1.0,0.0) [0.0|1.0] ""  CLU
 SG_ CF_Gway_ParkBrakeSw : 60|2@1+ (1.0,0.0) [0.0|3.0] ""  CLU,ESC,IBOX,SCC,ESC,IBOX,SCC
 SG_ CF_Gway_TurnSigRh : 62|2@1+ (1.0,0.0) [0.0|3.0] ""  CLU,EMS,IBOX,LCA,LDWS_LKAS,SCC,EMS,IBOX,LCA,LDWS_LKAS,SCC

BO_ 832 LKAS11: 8 LDWS_LKAS
 SG_ CF_Lkas_LdwsActivemode : 0|2@1+ (1,0) [0|3] "" CLU,IBOX,PSB
 SG_ CF_Lkas_LdwsSysState : 2|4@1+ (1.0,0.0) [0.0|15.0] ""  CLU,IBOX,PSB
 SG_ CF_Lkas_SysWarning : 6|4@1+ (1.0,0.0) [0.0|15.0] ""  BCM,CLU
 SG_ CF_Lkas_LdwsLHWarning : 10|2@1+ (1.0,0.0) [0.0|3.0] ""  BCM,CLU,PSB
 SG_ CF_Lkas_LdwsRHWarning : 12|2@1+ (1.0,0.0) [0.0|3.0] ""  BCM,CLU,PSB
 SG_ CF_Lkas_HbaLamp : 14|1@1+ (1.0,0.0) [0.0|1.0] ""  CLU
 SG_ CF_Lkas_FcwBasReq : 15|1@1+ (1.0,0.0) [0.0|1.0] ""  ABS,ESC
 SG_ CR_Lkas_StrToqReq : 16|11@1+ (1.0,-1024.0) [-1024.0|1024.0] ""  MDPS
 SG_ CF_Lkas_ActToi : 27|1@1+ (1.0,0.0) [0.0|1.0] ""  MDPS
 SG_ CF_Lkas_ToiFlt : 28|1@1+ (1.0,0.0) [0.0|1.0] ""  MDPS
 SG_ CF_Lkas_HbaSysState : 29|3@1+ (1.0,0.0) [0.0|7.0] ""  BCM,CLU
 SG_ CF_Lkas_FcwOpt : 32|2@1+ (1.0,0.0) [0.0|3.0] ""  CLU
 SG_ CF_Lkas_HbaOpt : 34|2@1+ (1.0,0.0) [0.0|1.0] ""  BCM,CGW
 SG_ CF_Lkas_MsgCount : 36|4@1+ (1.0,0.0) [0.0|15.0] ""  CLU,MDPS
 SG_ CF_Lkas_FcwSysState : 40|3@1+ (1.0,0.0) [0.0|7.0] ""  CLU
 SG_ CF_Lkas_FcwCollisionWarning : 43|2@1+ (1.0,0.0) [0.0|3.0] ""  CLU
 SG_ CF_Lkas_FusionState : 45|2@1+ (1.0,0.0) [0.0|3.0] ""  SCC
 SG_ CF_Lkas_Unknown1 : 47|1@1+ (1.0,0.0) [0.0|1.0] "" XXX
 SG_ CF_Lkas_Chksum : 48|8@1+ (1.0,0.0) [0.0|255.0] ""  MDPS
 SG_ CF_Lkas_FcwOpt_USM : 56|3@1+ (1.0,0.0) [0.0|7.0] ""  CLU
 SG_ CF_Lkas_LdwsOpt_USM : 59|3@1+ (1.0,0.0) [0.0|7.0] ""  CLU,MDPS
 SG_ CF_Lkas_Unknown2 : 62|2@1+ (1.0,0.0) [0.0|1.0] "" XXX

BO_ 1342 LKAS12: 6 LDWS_LKAS
 SG_ CF_Lkas_TsrSlifOpt : 10|2@1+ (1.0,0.0) [0.0|3.0] ""  CLU
 SG_ CF_LkasTsrStatus : 12|2@1+ (1.0,0.0) [0.0|3.0] ""  CLU
 SG_ CF_Lkas_TsrSpeed_Display_Clu : 16|8@1+ (1.0,0.0) [0.0|255.0] ""  CLU
 SG_ CF_LkasTsrSpeed_Display_Navi : 24|8@1+ (1.0,0.0) [0.0|255.0] ""  BCM,CLU
 SG_ CF_Lkas_TsrAddinfo_Display : 32|2@1+ (1.0,0.0) [0.0|3.0] ""  CLU
 SG_ CF_LkasDawStatus : 40|3@1+ (1,0) [0|7] "" CLU
 SG_ CF_Lkas_Daw_USM : 37|3@1+ (1,0) [0|7] "" CLU

BO_ 1338 TMU_GW_E_01: 8 CLU
 SG_ CF_Gway_TeleReqDrLock : 0|2@1+ (1.0,0.0) [0.0|3.0] ""  BCM
 SG_ CF_Gway_TeleReqDrUnlock : 2|2@1+ (1.0,0.0) [0.0|3.0] ""  BCM
 SG_ CF_Gway_TeleReqHazard : 4|2@1+ (1.0,0.0) [0.0|3.0] ""  BCM
 SG_ CF_Gway_TeleReqHorn : 6|2@1+ (1.0,0.0) [0.0|3.0] ""  BCM
 SG_ CF_Gway_TeleReqEngineOperate : 8|2@1+ (1.0,0.0) [0.0|3.0] ""  BCM

BO_ 1078 PAS11: 4 BCM
 SG_ CF_Gway_PASDisplayFLH : 0|3@1+ (1.0,0.0) [0.0|7.0] ""  AVM,CLU,AVM
 SG_ CF_Gway_PASDisplayFRH : 3|3@1+ (1.0,0.0) [0.0|7.0] ""  AVM,CLU,AVM
 SG_ CF_Gway_PASRsound : 6|2@1+ (1.0,0.0) [0.0|3.0] ""  CLU,Dummy
 SG_ CF_Gway_PASDisplayFCTR : 8|3@1+ (1.0,0.0) [0.0|7.0] ""  AVM,CLU,AVM
 SG_ CF_Gway_PASDisplayRCTR : 11|3@1+ (1.0,0.0) [0.0|7.0] ""  AVM,CLU,PGS,AVM
 SG_ CF_Gway_PASFsound : 14|2@1+ (1.0,0.0) [0.0|3.0] ""  CLU,Dummy
 SG_ CF_Gway_PASDisplayRLH : 16|3@1+ (1.0,0.0) [0.0|7.0] ""  AVM,CLU,PGS,AVM
 SG_ CF_Gway_PASDisplayRRH : 19|3@1+ (1.0,0.0) [0.0|7.0] ""  AVM,CLU,PGS,AVM
 SG_ CF_Gway_PASCheckSound : 22|2@1+ (1.0,0.0) [0.0|3.0] ""  CLU,Dummy
 SG_ CF_Gway_PASSystemOn : 24|2@1+ (1.0,0.0) [0.0|3.0] ""  CLU,Dummy
 SG_ CF_Gway_PASOption : 26|2@1+ (1.0,0.0) [0.0|3.0] ""  CLU
 SG_ CF_Gway_PASDistance : 28|1@1+ (1.0,0.0) [0.0|1.0] ""  CLU

BO_ 48 EMS18: 6 EMS
 SG_ CF_Ems_DC1NumPerMSV : 0|8@1+ (1.0,0.0) [0.0|255.0] ""  DI_BOX
 SG_ CF_Ems_DC2NumPerMSV : 8|16@1+ (1.0,0.0) [0.0|65535.0] ""  DI_BOX
 SG_ CR_Ems_DutyCyc1MSV : 24|8@1+ (0.1953,0.0) [0.0|49.8] "%"  DI_BOX
 SG_ CR_Ems_DutyCyc2MSV : 32|8@1+ (0.13725,0.0) [0.0|35.0] "%"  DI_BOX
 SG_ CR_Ems_DutyCyc3MSV : 40|8@1+ (0.392,0.0) [0.0|100.0] "%"  DI_BOX

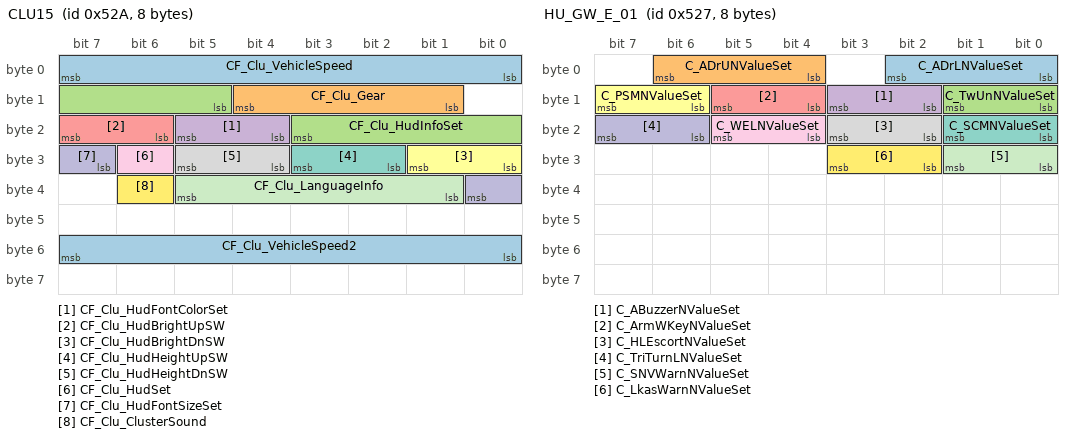
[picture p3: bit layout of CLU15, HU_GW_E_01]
BO_ 1322 CLU15: 8 CLU
 SG_ CF_Clu_VehicleSpeed : 0|8@1+ (1.0,0.0) [0.0|255.0] ""  BCM
 SG_ CF_Clu_Gear : 9|4@1+ (1,0) [0|15] "" BCM
 SG_ CF_Clu_HudInfoSet : 13|7@1+ (1.0,0.0) [0.0|127.0] ""  HUD
 SG_ CF_Clu_HudFontColorSet : 20|2@1+ (1.0,0.0) [0.0|3.0] ""  HUD
 SG_ CF_Clu_HudBrightUpSW : 22|2@1+ (1.0,0.0) [0.0|3.0] ""  HUD
 SG_ CF_Clu_HudBrightDnSW : 24|2@1+ (1.0,0.0) [0.0|3.0] ""  HUD
 SG_ CF_Clu_HudHeightUpSW : 26|2@1+ (1.0,0.0) [0.0|3.0] ""  HUD
 SG_ CF_Clu_HudHeightDnSW : 28|2@1+ (1.0,0.0) [0.0|3.0] ""  HUD
 SG_ CF_Clu_HudSet : 30|1@1+ (1.0,0.0) [0.0|1.0] ""  HUD
 SG_ CF_Clu_HudFontSizeSet : 31|2@1+ (1.0,0.0) [0.0|3.0] ""  HUD
 SG_ CF_Clu_LanguageInfo : 33|5@1+ (1.0,0.0) [0.0|31.0] ""  BCM,PGS
 SG_ CF_Clu_ClusterSound : 38|1@1- (1.0,0.0) [0.0|0.0] ""  BCM,CGW,FATC
 SG_ CF_Clu_VehicleSpeed2 : 48|8@1+ (1,0) [0|255] "" XXX

BO_ 1066 _4WD13: 6 _4WD
 SG_ _4WD_CURRENT : 0|8@1+ (0.390625,0.0) [-50.0|50.0] "A"  TCU
 SG_ _4WD_POSITION : 8|16@1+ (0.015625,0.0) [-180.0|180.0] "Deg"  TCU
 SG_ _4WD_CLU_THERM_STR : 24|8@1+ (1.0,0.0) [0.0|100.0] "%"  TCU
 SG_ _4WD_STATUS : 32|8@1+ (1.0,0.0) [0.0|15.0] ""  ESC,TCU

BO_ 1065 _4WD12: 8 _4WD
 SG_ Ster_Pos : 0|16@1+ (1.0,-600.0) [-600.0|600.0] "Deg"  ESC
 SG_ FRSS : 16|8@1+ (1.0,0.0) [0.0|254.0] "km/h"  ESC
 SG_ FLSS : 24|8@1+ (1.0,0.0) [0.0|254.0] "km/h"  ESC
 SG_ RRSS : 32|8@1+ (1.0,0.0) [0.0|254.0] "km/h"  ESC
 SG_ RLSS : 40|8@1+ (1.0,0.0) [0.0|254.0] "km/h"  ESC
 SG_ CLU_PRES : 48|16@1+ (0.0625,-50.0) [-50.0|50.0] "Bar"  ESC

BO_ 809 EMS12: 8 EMS
 SG_ CONF_TCU m1 : 0|6@1+ (1.0,0.0) [0.0|63.0] ""  _4WD,ACU,BCM,CLU,DATC,EPB,ESC,IBOX,LCA,SMK
 SG_ CAN_VERS m0 : 0|6@1+ (1.0,0.0) [0.0|7.7] ""  _4WD,ABS,ESC,IBOX
 SG_ TQ_STND m3 : 0|6@1+ (10.0,0.0) [0.0|630.0] "Nm"  _4WD,DATC,ECS,EPB,ESC,FATC,IBOX
 SG_ OBD_FRF_ACK m2 : 0|6@1+ (1.0,0.0) [0.0|63.0] ""  _4WD,ESC,IBOX
 SG_ MUL_CODE M : 6|2@1+ (1.0,0.0) [0.0|3.0] ""  _4WD,ABS,ACU,BCM,CLU,DATC,ECS,EPB,ESC,IBOX,LCA,SMK,TCU
 SG_ TEMP_ENG : 8|8@1+ (0.75,-48.0) [-48.0|143.25] "deg"  _4WD,BCM,CLU,DATC,EPB,ESC,IBOX,SMK,TCU
 SG_ MAF_FAC_ALTI_MMV : 16|8@1+ (0.00781,0.0) [0.0|1.99155] ""  IBOX,TCU
 SG_ VB_OFF_ACT : 24|1@1+ (1.0,0.0) [0.0|1.0] ""  IBOX,TCU
 SG_ ACK_ES : 25|1@1+ (1.0,0.0) [0.0|1.0] ""  _4WD,ACU,IBOX
 SG_ CONF_MIL_FMY : 26|3@1+ (1.0,0.0) [0.0|7.0] ""  ESC,IBOX,TCU
 SG_ OD_OFF_REQ : 29|1@1+ (1.0,0.0) [0.0|1.0] ""  IBOX,TCU
 SG_ ACC_ACT : 30|1@1+ (1.0,0.0) [0.0|1.0] ""  _4WD,ABS,CLU,ESC,IAP,IBOX,SCC,TCU
 SG_ CLU_ACK : 31|1@1+ (1.0,0.0) [0.0|1.0] ""  _4WD,EPB,ESC,IBOX
 SG_ BRAKE_ACT : 32|2@1+ (1.0,0.0) [0.0|3.0] ""  _4WD,ABS,ACU,AFLS,CLU,DATC,ECS,EPB,ESC,IBOX,LDWS_LKAS,TCU
 SG_ ENG_CHR : 34|4@1+ (1.0,0.0) [0.0|15.0] ""  _4WD,ABS,ACU,CLU,DATC,EPB,ESC,FATC,IBOX,SCC,SMK,TCU
 SG_ GP_CTL : 38|2@1+ (1.0,0.0) [0.0|3.0] ""  IBOX
 SG_ TPS : 40|8@1+ (0.4694836,-15.0234742) [-15.0234742|104.6948357] "%"  _4WD,ABS,ACU,CLU,DATC,ECS,EPB,ESC,IBOX,TCU
 SG_ PV_AV_CAN : 48|8@1+ (0.3906,0.0) [0.0|99.603] "%"  _4WD,AAF,ABS,ACU,AFLS,CLU,DATC,EPB,ESC,IAP,IBOX,LDWS_LKAS,SCC,TCU
 SG_ ENG_VOL : 56|8@1+ (0.1,0.0) [0.0|25.5] "liter"  _4WD,ABS,ACU,BCM,CLU,DATC,EPB,ESC,IBOX,LDWS_LKAS,SCC,SMK

BO_ 1064 _4WD11: 8 _4WD
 SG_ _4WD_TYPE : 0|2@1+ (1.0,0.0) [0.0|3.0] ""  ACU,ESC,TPMS
 SG_ _4WD_SUPPORT : 2|2@1+ (1.0,0.0) [0.0|3.0] ""  ABS,ESC,TPMS
 SG_ _4WD_ERR : 8|8@1+ (1.0,0.0) [0.0|255.0] ""  CLU,ESC
 SG_ CLU_DUTY : 16|8@1+ (1.0,0.0) [0.0|64.0] "%"  ABS,ESC
 SG_ R_TIRE : 24|8@1+ (1.0,200.0) [200.0|455.0] "mm"  ABS,ESC,TPMS
 SG_ _4WD_SW : 32|8@1+ (1.0,0.0) [0.0|9.9] ""  ESC
 SG_ _2H_ACT : 40|1@1+ (1.0,0.0) [0.0|1.0] ""  ABS,ESC
 SG_ _4H_ACT : 41|1@1+ (1.0,0.0) [0.0|1.0] ""  ABS,CLU,ESC,TPMS
 SG_ LOW_ACT : 42|1@1+ (1.0,0.0) [0.0|1.0] ""  ABS,ESC,TCU,TPMS
 SG_ AUTO_ACT : 43|1@1+ (1.0,0.0) [0.0|1.0] ""  ABS,ESC,TPMS
 SG_ LOCK_ACT : 44|1@1+ (1.0,0.0) [0.0|1.0] ""  ABS,CLU,ESC,TPMS
 SG_ _4WD_TQC_CUR : 48|16@1+ (1.0,0.0) [0.0|65535.0] "Nm"  ABS,ESC

BO_ 1319 HU_GW_E_01: 8 CLU
 SG_ C_ADrLNValueSet : 0|3@1+ (1.0,0.0) [0.0|7.0] ""  BCM
 SG_ C_ADrUNValueSet : 4|3@1+ (1.0,0.0) [0.0|7.0] ""  BCM
 SG_ C_TwUnNValueSet : 8|2@1+ (1.0,0.0) [0.0|3.0] ""  BCM
 SG_ C_ABuzzerNValueSet : 10|2@1+ (1.0,0.0) [0.0|3.0] ""  BCM
 SG_ C_ArmWKeyNValueSet : 12|2@1+ (1.0,0.0) [0.0|3.0] ""  BCM
 SG_ C_PSMNValueSet : 14|2@1+ (1.0,0.0) [0.0|3.0] ""  BCM
 SG_ C_SCMNValueSet : 16|2@1+ (1.0,0.0) [0.0|3.0] ""  BCM
 SG_ C_HLEscortNValueSet : 18|2@1+ (1.0,0.0) [0.0|3.0] ""  BCM
 SG_ C_WELNValueSet : 20|2@1+ (1.0,0.0) [0.0|3.0] ""  BCM
 SG_ C_TriTurnLNValueSet : 22|2@1+ (1.0,0.0) [0.0|3.0] ""  BCM
 SG_ C_SNVWarnNValueSet : 24|2@1+ (1.0,0.0) [0.0|3.0] ""  BCM
 SG_ C_LkasWarnNValueSet : 26|2@1+ (1.0,0.0) [0.0|3.0] ""  BCM

BO_ 48 EMS18: 6 EMS
 SG_ CF_Ems_DC1NumPerMSV : 0|8@1+ (1.0,0.0) [0.0|255.0] ""  DI_BOX
 SG_ CF_Ems_DC2NumPerMSV : 8|16@1+ (1.0,0.0) [0.0|65535.0] ""  DI_BOX
 SG_ CR_Ems_DutyCyc1MSV : 24|8@1+ (0.1953,0.0) [0.0|49.8] "%"  DI_BOX
 SG_ CR_Ems_DutyCyc2MSV : 32|8@1+ (0.13725,0.0) [0.0|35.0] "%"  DI_BOX
 SG_ CR_Ems_DutyCyc3MSV : 40|8@1+ (0.392,0.0) [0.0|100.0] "%"  DI_BOX

BO_ 66 DATC12: 8 DATC
 SG_ CR_Datc_DrTempDispC : 0|8@1+ (0.5,14.0) [15.0|32.0] "deg"  CLU,IBOX
 SG_ CR_Datc_DrTempDispF : 8|8@1+ (1.0,56.0) [58.0|90.0] "deg"  CLU,IBOX
 SG_ CR_Datc_PsTempDispC : 16|8@1+ (0.5,14.0) [15.0|32.0] "deg"  CLU,IBOX
 SG_ CR_Datc_PsTempDispF : 24|8@1+ (1.0,56.0) [58.0|90.0] "deg"  CLU,IBOX
 SG_ CR_Datc_RearDrTempDispC : 40|8@1+ (0.5,14.0) [15.0|32.0] "deg"  CLU
 SG_ CR_Datc_RearDrTempDispF : 48|8@1+ (1.0,58.0) [58.0|90.0] "deg"  CLU
 SG_ CF_Datc_CO2_Warning : 56|8@1+ (1.0,0.0) [0.0|3.0] ""  CLU

BO_ 67 DATC13: 8 DATC
 SG_ CF_Datc_TempDispUnit : 0|2@1+ (1.0,0.0) [0.0|3.0] ""  CLU,IBOX
 SG_ CF_Datc_ModDisp : 2|4@1+ (1.0,0.0) [0.0|15.0] ""  CLU
 SG_ CF_Datc_IonClean : 6|2@1+ (1.0,0.0) [0.0|3.0] ""  CLU
 SG_ CF_Datc_ChgReqDisp : 8|2@1+ (1.0,0.0) [0.0|3.0] ""  CLU
 SG_ CF_Datc_IntakeDisp : 10|2@1+ (1.0,0.0) [0.0|3.0] ""  CLU
 SG_ CF_Datc_AutoDisp : 12|2@1+ (1.0,0.0) [0.0|3.0] ""  CLU
 SG_ CF_Datc_FrDefLed : 14|2@1+ (1.0,0.0) [0.0|3.0] ""  CLU,IBOX
 SG_ CF_Datc_AutoDefogBlink : 16|2@1+ (1.0,0.0) [0.0|3.0] ""  CLU
 SG_ CF_Datc_ClmScanDisp : 18|2@1+ (1.0,0.0) [0.0|3.0] ""  CLU
 SG_ CF_Datc_AqsDisp : 20|2@1+ (1.0,0.0) [0.0|3.0] ""  CLU
 SG_ CF_Datc_AcDisp : 22|2@1+ (1.0,0.0) [0.0|3.0] ""  CLU
 SG_ CF_Datc_OpSts : 25|3@1+ (1.0,0.0) [0.0|7.0] ""  CLU
 SG_ CF_Mtc_MaxAcDisp : 28|2@1+ (1.0,0.0) [0.0|3.0] ""  CLU
 SG_ CF_Datc_DualDisp : 30|2@1+ (1.0,0.0) [0.0|3.0] ""  CLU
 SG_ CF_Datc_PwrInf : 32|4@1+ (1.0,0.0) [0.0|15.0] ""  CLU
 SG_ CF_Datc_RearManual : 38|2@1+ (1.0,0.0) [0.0|3.0] ""  CLU
 SG_ CF_Datc_RearAutoDisp : 40|2@1+ (1.0,0.0) [0.0|1.0] ""  CLU
 SG_ CF_Datc_RearOffDisp : 42|2@1+ (1.0,0.0) [0.0|3.0] ""  CLU
 SG_ CF_Datc_RearClimateScnDisp : 44|2@1+ (1.0,0.0) [0.0|3.0] ""  CLU
 SG_ CF_Datc_RearChgReqDisp : 46|2@1+ (1.0,0.0) [0.0|3.0] ""  CLU
 SG_ CF_Datc_RearModDisp : 48|4@1+ (1.0,0.0) [0.0|15.0] ""  CLU
 SG_ CF_Datc_RearBlwDisp : 52|4@1+ (1.0,0.0) [0.0|15.0] ""  CLU
 SG_ CF_Datc_PSModDisp : 56|4@1+ (1.0,0.0) [0.0|15.0] ""  CLU
 SG_ CF_Datc_FrontBlwDisp : 60|4@1+ (1.0,0.0) [0.0|15.0] ""  CLU,IBOX

BO_ 68 DATC11: 8 DATC
 SG_ CF_Datc_Type : 0|8@1+ (1.0,0.0) [0.0|255.0] ""  CLU
 SG_ CF_Datc_VerMaj : 8|8@1+ (1.0,0.0) [0.0|255.0] ""  CLU
 SG_ CF_Datc_VerMin : 16|8@1+ (1.0,0.0) [0.0|255.0] ""  CLU
 SG_ CR_Datc_OutTempC : 24|8@1+ (0.5,-41.0) [-41.0|86.5] "deg"  CLU,FPCM
 SG_ CR_Datc_OutTempF : 32|8@1+ (1.0,-42.0) [-42.0|213.0] "deg"  CLU
 SG_ CF_Datc_IncarTemp : 40|8@1+ (0.5,-40.0) [-40.0|60.0] "deg"  BCM,CLU

BO_ 339 TCS11: 8 ESC
 SG_ TCS_REQ : 0|1@1+ (1.0,0.0) [0.0|1.0] ""  _4WD,EMS,EPB,TCU
 SG_ MSR_C_REQ : 1|1@1+ (1.0,0.0) [0.0|1.0] ""  EMS,EPB,SCC,TCU
 SG_ TCS_PAS : 2|1@1+ (1.0,0.0) [0.0|1.0] ""  _4WD,CLU,EMS,SCC,SPAS,TCU
 SG_ TCS_GSC : 3|1@1+ (1.0,0.0) [0.0|1.0] ""  _4WD,EMS,TCU
 SG_ CF_Esc_LimoInfo : 4|2@1+ (1.0,0.0) [0.0|3.0] ""  _4WD,SCC
 SG_ ABS_DIAG : 6|1@1+ (1.0,0.0) [0.0|1.0] ""  _4WD,CLU,EMS,EPB
 SG_ ABS_DEF : 7|1@1+ (1.0,0.0) [0.0|1.0] ""  _4WD,ACU,ECS,EMS,EPB,SCC,SPAS,TCU
 SG_ TCS_DEF : 8|1@1+ (1.0,0.0) [0.0|1.0] ""  _4WD,EMS,EPB,SCC,SPAS,TCU
 SG_ TCS_CTL : 9|1@1+ (1.0,0.0) [0.0|1.0] ""  _4WD,EMS,EPB,SCC,SPAS,TCU
 SG_ ABS_ACT : 10|1@1+ (1.0,0.0) [0.0|1.0] ""  _4WD,ACU,ECS,EMS,EPB,LDWS_LKAS,SCC,SPAS,TCU
 SG_ EBD_DEF : 11|1@1+ (1.0,0.0) [0.0|1.0] ""  _4WD,EMS,EPB,SPAS,TCU
 SG_ ESP_PAS : 12|1@1+ (1.0,0.0) [0.0|1.0] ""  _4WD,ACU,CLU,EMS,EPB,LDWS_LKAS,SCC,TCU
 SG_ ESP_DEF : 13|1@1+ (1.0,0.0) [0.0|1.0] ""  _4WD,ACU,ECS,EMS,EPB,LDWS_LKAS,SCC,TCU
 SG_ ESP_CTL : 14|1@1+ (1.0,0.0) [0.0|1.0] ""  _4WD,ACU,ECS,EMS,EPB,LDWS_LKAS,SCC,SPAS,TCU
 SG_ TCS_MFRN : 15|1@1+ (1.0,0.0) [0.0|1.0] ""  EMS,EPB,TCU
 SG_ DBC_CTL : 16|1@1+ (1.0,0.0) [0.0|1.0] ""  _4WD,EMS,EPB
 SG_ DBC_PAS : 17|1@1+ (1.0,0.0) [0.0|1.0] ""  _4WD,EMS,EPB
 SG_ DBC_DEF : 18|1@1+ (1.0,0.0) [0.0|1.0] ""  _4WD,EMS,EPB
 SG_ HAC_CTL : 19|1@1+ (1.0,0.0) [0.0|1.0] ""  _4WD,CLU,EMS,EPB,TCU
 SG_ HAC_PAS : 20|1@1+ (1.0,0.0) [0.0|1.0] ""  _4WD,CLU,EMS,EPB,TCU
 SG_ HAC_DEF : 21|1@1+ (1.0,0.0) [0.0|1.0] ""  _4WD,CLU,EMS,EPB,TCU
 SG_ ESS_STAT : 22|2@1+ (1.0,0.0) [0.0|3.0] ""  _4WD,BCM,CLU,EMS,EPB
 SG_ TQI_TCS : 24|8@1+ (0.390625,0.0) [0.0|99.609375] "%"  EMS,EPB,TCU
 SG_ TQI_MSR : 32|8@1+ (0.390625,0.0) [0.0|99.609375] "%"  EMS,EPB,TCU
 SG_ TQI_SLW_TCS : 40|8@1+ (0.390625,0.0) [0.0|99.609375] "%"  EMS,EPB,TCU
 SG_ CF_Esc_BrkCtl : 48|1@1+ (1.0,0.0) [0.0|1.0] ""  EMS
 SG_ BLA_CTL : 49|2@1+ (1.0,0.0) [0.0|3.0] ""  BCM,CGW,CLU
 SG_ AliveCounter_TCS1 : 52|4@1+ (1.0,0.0) [0.0|14.0] ""  EMS,EPB,LDWS_LKAS
 SG_ CheckSum_TCS1 : 56|8@1+ (1.0,0.0) [0.0|255.0] ""  EMS,EPB,LDWS_LKAS

BO_ 356 VSM11: 4 ESC
 SG_ CR_Esc_StrTqReq : 0|12@1+ (0.01,-20.48) [-20.48|20.47] "Nm"  MDPS
 SG_ CF_Esc_Act : 12|1@1+ (1.0,0.0) [0.0|1.0] ""  LDWS_LKAS,MDPS
 SG_ CF_Esc_CtrMode : 13|3@1+ (1.0,0.0) [0.0|7.0] ""  MDPS
 SG_ CF_Esc_Def : 16|1@1+ (1.0,0.0) [0.0|1.0] ""  MDPS
 SG_ CF_Esc_AliveCnt : 17|4@1+ (1.0,0.0) [0.0|15.0] ""  LDWS_LKAS,MDPS
 SG_ CF_Esc_Chksum : 24|8@1+ (1.0,0.0) [0.0|255.0] ""  LDWS_LKAS,MDPS

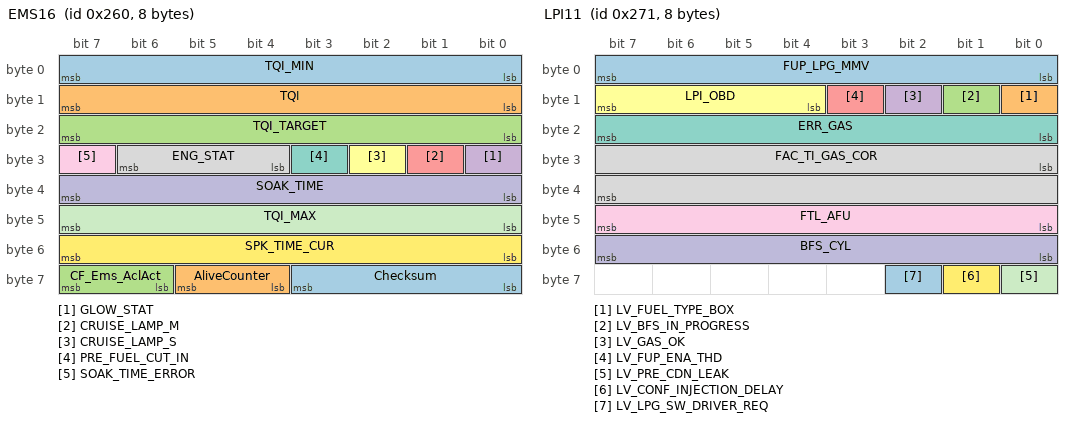
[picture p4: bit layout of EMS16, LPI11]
BO_ 608 EMS16: 8 EMS
 SG_ TQI_MIN : 0|8@1+ (0.390625,0.0) [0.0|99.609375] "%"  ESC,IBOX,TCU
 SG_ TQI : 8|8@1+ (0.390625,0.0) [0.0|99.609375] "%"  ESC,IBOX,TCU
 SG_ TQI_TARGET : 16|8@1+ (0.390625,0.0) [0.0|99.609375] "%"  EPB,ESC,IBOX,TCU
 SG_ GLOW_STAT : 24|1@1+ (1.0,0.0) [0.0|1.0] ""  BCM,CLU,IBOX,SMK
 SG_ CRUISE_LAMP_M : 25|1@1+ (1.0,0.0) [0.0|1.0] ""  CLU,IBOX,TCU
 SG_ CRUISE_LAMP_S : 26|1@1+ (1.0,0.0) [0.0|1.0] ""  CLU,IBOX,TCU
 SG_ PRE_FUEL_CUT_IN : 27|1@1+ (1.0,0.0) [0.0|1.0] ""  IBOX,TCU
 SG_ ENG_STAT : 28|3@1+ (1.0,0.0) [0.0|7.0] ""  ABS,AHLS,AVM,BCM,CLU,EPB,ESC,EVP,FPCM,IBOX,LCA,LDWS_LKAS,MDPS,SCC,SMK,TCU
 SG_ SOAK_TIME_ERROR : 31|1@1+ (1.0,0.0) [0.0|1.0] ""  DATC,EPB,IBOX,TCU
 SG_ SOAK_TIME : 32|8@1+ (1.0,0.0) [0.0|255.0] "Min"  _4WD,DATC,EPB,IBOX,TCU
 SG_ TQI_MAX : 40|8@1+ (0.390625,0.0) [0.0|99.609375] "%"  ESC,IBOX,TCU
 SG_ SPK_TIME_CUR : 48|8@1+ (0.375,-35.625) [-35.625|60.0] ""  IBOX,TCU
 SG_ Checksum : 56|4@1+ (1.0,0.0) [0.0|15.0] ""  ECS,IBOX,LDWS_LKAS,MDPS,SCC
 SG_ AliveCounter : 60|2@1+ (1.0,0.0) [0.0|3.0] ""  IBOX,LDWS_LKAS,MDPS,SCC
 SG_ CF_Ems_AclAct : 62|2@1+ (1.0,0.0) [0.0|3.0] ""  IBOX,SCC

BO_ 625 LPI11: 8 LPI
 SG_ FUP_LPG_MMV : 0|8@1+ (128.0,0.0) [0.0|32640.0] "hPa"  EMS
 SG_ LV_FUEL_TYPE_BOX : 8|1@1+ (1.0,0.0) [0.0|1.0] ""  EMS
 SG_ LV_BFS_IN_PROGRESS : 9|1@1+ (1.0,0.0) [0.0|1.0] ""  EMS
 SG_ LV_GAS_OK : 10|1@1+ (1.0,0.0) [0.0|1.0] ""  EMS
 SG_ LV_FUP_ENA_THD : 11|1@1+ (1.0,0.0) [0.0|1.0] ""  BCM,CLU,EMS,SMK
 SG_ LPI_OBD : 12|4@1+ (1.0,0.0) [0.0|15.0] ""  EMS
 SG_ ERR_GAS : 16|8@1+ (1.0,0.0) [0.0|255.0] ""  EMS
 SG_ FAC_TI_GAS_COR : 24|16@1+ (3.05E-5,0.0) [0.0|1.9988175] ""  EMS
 SG_ FTL_AFU : 40|8@1+ (0.392,0.0) [0.0|99.96] "%"  EMS
 SG_ BFS_CYL : 48|8@1+ (1.0,0.0) [0.0|6.0] "Cyl Nr."  EMS
 SG_ LV_PRE_CDN_LEAK : 56|1@1+ (1.0,0.0) [0.0|1.0] ""  EMS
 SG_ LV_CONF_INJECTION_DELAY : 57|1@1+ (1.0,0.0) [0.0|1.0] ""  EMS
 SG_ LV_LPG_SW_DRIVER_REQ : 58|1@1+ (1.0,0.0) [0.0|1.0] ""  EMS

BO_ 809 EMS12: 8 EMS
 SG_ CONF_TCU m1 : 0|6@1+ (1.0,0.0) [0.0|63.0] ""  _4WD,ACU,BCM,CLU,DATC,EPB,ESC,IBOX,LCA,SMK
 SG_ CAN_VERS m0 : 0|6@1+ (1.0,0.0) [0.0|7.7] ""  _4WD,ABS,ESC,IBOX
 SG_ TQ_STND m3 : 0|6@1+ (10.0,0.0) [0.0|630.0] "Nm"  _4WD,DATC,ECS,EPB,ESC,FATC,IBOX
 SG_ OBD_FRF_ACK m2 : 0|6@1+ (1.0,0.0) [0.0|63.0] ""  _4WD,ESC,IBOX
 SG_ MUL_CODE M : 6|2@1+ (1.0,0.0) [0.0|3.0] ""  _4WD,ABS,ACU,BCM,CLU,DATC,ECS,EPB,ESC,IBOX,LCA,SMK,TCU
 SG_ TEMP_ENG : 8|8@1+ (0.75,-48.0) [-48.0|143.25] "deg"  _4WD,BCM,CLU,DATC,EPB,ESC,IBOX,SMK,TCU
 SG_ MAF_FAC_ALTI_MMV : 16|8@1+ (0.00781,0.0) [0.0|1.99155] ""  IBOX,TCU
 SG_ VB_OFF_ACT : 24|1@1+ (1.0,0.0) [0.0|1.0] ""  IBOX,TCU
 SG_ ACK_ES : 25|1@1+ (1.0,0.0) [0.0|1.0] ""  _4WD,ACU,IBOX
 SG_ CONF_MIL_FMY : 26|3@1+ (1.0,0.0) [0.0|7.0] ""  ESC,IBOX,TCU
 SG_ OD_OFF_REQ : 29|1@1+ (1.0,0.0) [0.0|1.0] ""  IBOX,TCU
 SG_ ACC_ACT : 30|1@1+ (1.0,0.0) [0.0|1.0] ""  _4WD,ABS,CLU,ESC,IAP,IBOX,SCC,TCU
 SG_ CLU_ACK : 31|1@1+ (1.0,0.0) [0.0|1.0] ""  _4WD,EPB,ESC,IBOX
 SG_ BRAKE_ACT : 32|2@1+ (1.0,0.0) [0.0|3.0] ""  _4WD,ABS,ACU,AFLS,CLU,DATC,ECS,EPB,ESC,IBOX,LDWS_LKAS,TCU
 SG_ ENG_CHR : 34|4@1+ (1.0,0.0) [0.0|15.0] ""  _4WD,ABS,ACU,CLU,DATC,EPB,ESC,FATC,IBOX,SCC,SMK,TCU
 SG_ GP_CTL : 38|2@1+ (1.0,0.0) [0.0|3.0] ""  IBOX
 SG_ TPS : 40|8@1+ (0.4694836,-15.0234742) [-15.0234742|104.6948357] "%"  _4WD,ABS,ACU,CLU,DATC,ECS,EPB,ESC,IBOX,TCU
 SG_ PV_AV_CAN : 48|8@1+ (0.3906,0.0) [0.0|99.603] "%"  _4WD,AAF,ABS,ACU,AFLS,CLU,DATC,EPB,ESC,IAP,IBOX,LDWS_LKAS,SCC,TCU
 SG_ ENG_VOL : 56|8@1+ (0.1,0.0) [0.0|25.5] "liter"  _4WD,ABS,ACU,BCM,CLU,DATC,EPB,ESC,IBOX,LDWS_LKAS,SCC,SMK

BO_ 832 LKAS11: 8 LDWS_LKAS
 SG_ CF_Lkas_LdwsActivemode : 0|2@1+ (1,0) [0|3] "" CLU,IBOX,PSB
 SG_ CF_Lkas_LdwsSysState : 2|4@1+ (1.0,0.0) [0.0|15.0] ""  CLU,IBOX,PSB
 SG_ CF_Lkas_SysWarning : 6|4@1+ (1.0,0.0) [0.0|15.0] ""  BCM,CLU
 SG_ CF_Lkas_LdwsLHWarning : 10|2@1+ (1.0,0.0) [0.0|3.0] ""  BCM,CLU,PSB
 SG_ CF_Lkas_LdwsRHWarning : 12|2@1+ (1.0,0.0) [0.0|3.0] ""  BCM,CLU,PSB
 SG_ CF_Lkas_HbaLamp : 14|1@1+ (1.0,0.0) [0.0|1.0] ""  CLU
 SG_ CF_Lkas_FcwBasReq : 15|1@1+ (1.0,0.0) [0.0|1.0] ""  ABS,ESC
 SG_ CR_Lkas_StrToqReq : 16|11@1+ (1.0,-1024.0) [-1024.0|1024.0] ""  MDPS
 SG_ CF_Lkas_ActToi : 27|1@1+ (1.0,0.0) [0.0|1.0] ""  MDPS
 SG_ CF_Lkas_ToiFlt : 28|1@1+ (1.0,0.0) [0.0|1.0] ""  MDPS
 SG_ CF_Lkas_HbaSysState : 29|3@1+ (1.0,0.0) [0.0|7.0] ""  BCM,CLU
 SG_ CF_Lkas_FcwOpt : 32|2@1+ (1.0,0.0) [0.0|3.0] ""  CLU
 SG_ CF_Lkas_HbaOpt : 34|2@1+ (1.0,0.0) [0.0|1.0] ""  BCM,CGW
 SG_ CF_Lkas_MsgCount : 36|4@1+ (1.0,0.0) [0.0|15.0] ""  CLU,MDPS
 SG_ CF_Lkas_FcwSysState : 40|3@1+ (1.0,0.0) [0.0|7.0] ""  CLU
 SG_ CF_Lkas_FcwCollisionWarning : 43|2@1+ (1.0,0.0) [0.0|3.0] ""  CLU
 SG_ CF_Lkas_FusionState : 45|2@1+ (1.0,0.0) [0.0|3.0] ""  SCC
 SG_ CF_Lkas_Unknown1 : 47|1@1+ (1.0,0.0) [0.0|1.0] "" XXX
 SG_ CF_Lkas_Chksum : 48|8@1+ (1.0,0.0) [0.0|255.0] ""  MDPS
 SG_ CF_Lkas_FcwOpt_USM : 56|3@1+ (1.0,0.0) [0.0|7.0] ""  CLU
 SG_ CF_Lkas_LdwsOpt_USM : 59|3@1+ (1.0,0.0) [0.0|7.0] ""  CLU,MDPS
 SG_ CF_Lkas_Unknown2 : 62|2@1+ (1.0,0.0) [0.0|1.0] "" XXX

BO_ 871 LVR12: 8 LVR
 SG_ CF_Lvr_CruiseSet : 0|8@1+ (1.0,0.0) [0.0|255.0] "" CLU,TCU
 SG_ CF_Lvr_IsgState : 8|2@1+ (1.0,0.0) [0.0|3.0] "" CLU,TCU
 SG_ CF_Lvr_Gear : 32|4@1+ (1.0,0.0) [0.0|15.0] ""  CLU,TCU

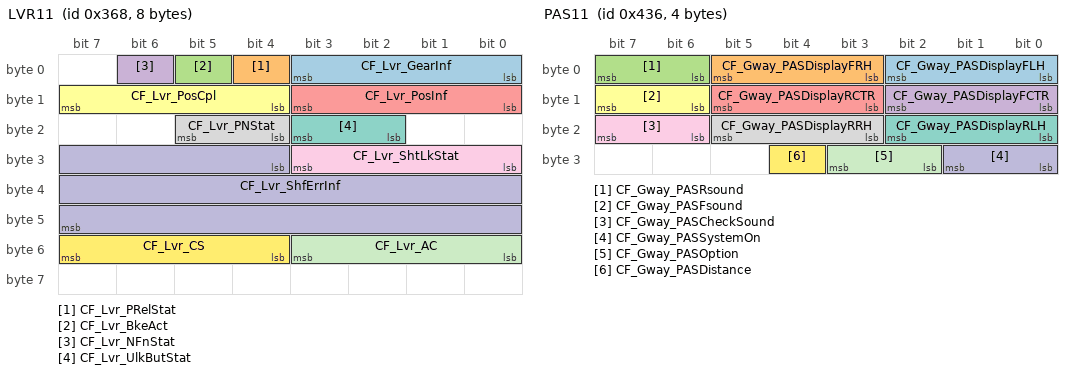
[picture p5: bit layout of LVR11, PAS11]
BO_ 872 LVR11: 8 LVR
 SG_ CF_Lvr_GearInf : 0|4@1+ (1.0,0.0) [0.0|15.0] ""  CLU,TCU
 SG_ CF_Lvr_PRelStat : 4|1@1+ (1.0,0.0) [0.0|1.0] ""  BCM,CLU,SMK,TCU
 SG_ CF_Lvr_BkeAct : 5|1@1+ (1.0,0.0) [0.0|1.0] ""  TCU
 SG_ CF_Lvr_NFnStat : 6|1@1+ (1.0,0.0) [0.0|1.0] ""  CLU
 SG_ CF_Lvr_PosInf : 8|4@1+ (1.0,0.0) [0.0|15.0] ""  TCU
 SG_ CF_Lvr_PosCpl : 12|4@1+ (1.0,0.0) [0.0|15.0] ""  TCU
 SG_ CF_Lvr_UlkButStat : 18|2@1+ (1.0,0.0) [0.0|3.0] ""  TCU
 SG_ CF_Lvr_PNStat : 20|2@1+ (1.0,0.0) [0.0|3.0] ""  CLU
 SG_ CF_Lvr_ShtLkStat : 24|4@1+ (1.0,0.0) [0.0|15.0] ""  TCU
 SG_ CF_Lvr_ShfErrInf : 28|20@1+ (1.0,0.0) [0.0|8191.0] ""  CLU,TCU
 SG_ CF_Lvr_AC : 48|4@1+ (1.0,0.0) [0.0|15.0] ""  TCU
 SG_ CF_Lvr_CS : 52|4@1+ (1.0,0.0) [0.0|15.0] ""  TCU

BO_ 1064 _4WD11: 8 _4WD
 SG_ _4WD_TYPE : 0|2@1+ (1.0,0.0) [0.0|3.0] ""  ACU,ESC,TPMS
 SG_ _4WD_SUPPORT : 2|2@1+ (1.0,0.0) [0.0|3.0] ""  ABS,ESC,TPMS
 SG_ _4WD_ERR : 8|8@1+ (1.0,0.0) [0.0|255.0] ""  CLU,ESC
 SG_ CLU_DUTY : 16|8@1+ (1.0,0.0) [0.0|64.0] "%"  ABS,ESC
 SG_ R_TIRE : 24|8@1+ (1.0,200.0) [200.0|455.0] "mm"  ABS,ESC,TPMS
 SG_ _4WD_SW : 32|8@1+ (1.0,0.0) [0.0|9.9] ""  ESC
 SG_ _2H_ACT : 40|1@1+ (1.0,0.0) [0.0|1.0] ""  ABS,ESC
 SG_ _4H_ACT : 41|1@1+ (1.0,0.0) [0.0|1.0] ""  ABS,CLU,ESC,TPMS
 SG_ LOW_ACT : 42|1@1+ (1.0,0.0) [0.0|1.0] ""  ABS,ESC,TCU,TPMS
 SG_ AUTO_ACT : 43|1@1+ (1.0,0.0) [0.0|1.0] ""  ABS,ESC,TPMS
 SG_ LOCK_ACT : 44|1@1+ (1.0,0.0) [0.0|1.0] ""  ABS,CLU,ESC,TPMS
 SG_ _4WD_TQC_CUR : 48|16@1+ (1.0,0.0) [0.0|65535.0] "Nm"  ABS,ESC

BO_ 1065 _4WD12: 8 _4WD
 SG_ Ster_Pos : 0|16@1+ (1.0,-600.0) [-600.0|600.0] "Deg"  ESC
 SG_ FRSS : 16|8@1+ (1.0,0.0) [0.0|254.0] "km/h"  ESC
 SG_ FLSS : 24|8@1+ (1.0,0.0) [0.0|254.0] "km/h"  ESC
 SG_ RRSS : 32|8@1+ (1.0,0.0) [0.0|254.0] "km/h"  ESC
 SG_ RLSS : 40|8@1+ (1.0,0.0) [0.0|254.0] "km/h"  ESC
 SG_ CLU_PRES : 48|16@1+ (0.0625,-50.0) [-50.0|50.0] "Bar"  ESC

BO_ 1066 _4WD13: 6 _4WD
 SG_ _4WD_CURRENT : 0|8@1+ (0.390625,0.0) [-50.0|50.0] "A"  TCU
 SG_ _4WD_POSITION : 8|16@1+ (0.015625,0.0) [-180.0|180.0] "Deg"  TCU
 SG_ _4WD_CLU_THERM_STR : 24|8@1+ (1.0,0.0) [0.0|100.0] "%"  TCU
 SG_ _4WD_STATUS : 32|8@1+ (1.0,0.0) [0.0|15.0] ""  ESC,TCU

BO_ 1078 PAS11: 4 BCM
 SG_ CF_Gway_PASDisplayFLH : 0|3@1+ (1.0,0.0) [0.0|7.0] ""  AVM,CLU,AVM
 SG_ CF_Gway_PASDisplayFRH : 3|3@1+ (1.0,0.0) [0.0|7.0] ""  AVM,CLU,AVM
 SG_ CF_Gway_PASRsound : 6|2@1+ (1.0,0.0) [0.0|3.0] ""  CLU,Dummy
 SG_ CF_Gway_PASDisplayFCTR : 8|3@1+ (1.0,0.0) [0.0|7.0] ""  AVM,CLU,AVM
 SG_ CF_Gway_PASDisplayRCTR : 11|3@1+ (1.0,0.0) [0.0|7.0] ""  AVM,CLU,PGS,AVM
 SG_ CF_Gway_PASFsound : 14|2@1+ (1.0,0.0) [0.0|3.0] ""  CLU,Dummy
 SG_ CF_Gway_PASDisplayRLH : 16|3@1+ (1.0,0.0) [0.0|7.0] ""  AVM,CLU,PGS,AVM
 SG_ CF_Gway_PASDisplayRRH : 19|3@1+ (1.0,0.0) [0.0|7.0] ""  AVM,CLU,PGS,AVM
 SG_ CF_Gway_PASCheckSound : 22|2@1+ (1.0,0.0) [0.0|3.0] ""  CLU,Dummy
 SG_ CF_Gway_PASSystemOn : 24|2@1+ (1.0,0.0) [0.0|3.0] ""  CLU,Dummy
 SG_ CF_Gway_PASOption : 26|2@1+ (1.0,0.0) [0.0|3.0] ""  CLU
 SG_ CF_Gway_PASDistance : 28|1@1+ (1.0,0.0) [0.0|1.0] ""  CLU

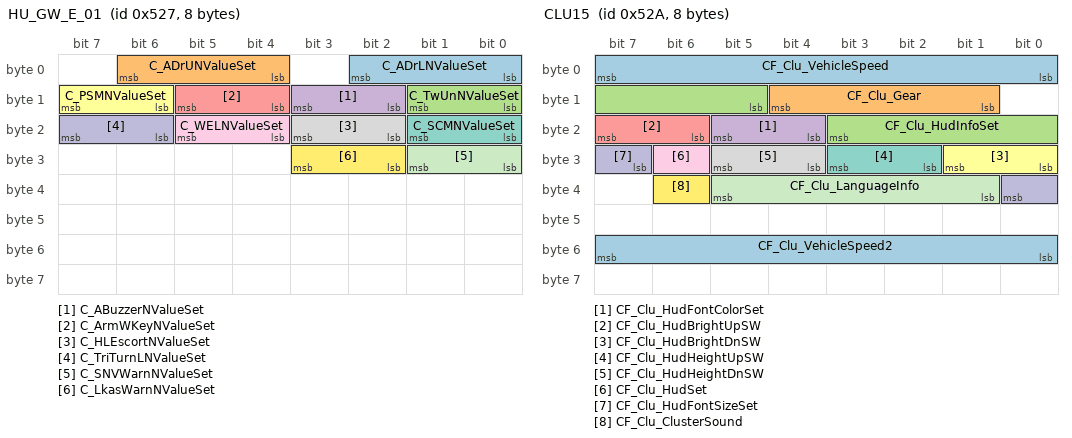
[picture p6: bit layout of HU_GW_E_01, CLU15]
BO_ 1319 HU_GW_E_01: 8 CLU
 SG_ C_ADrLNValueSet : 0|3@1+ (1.0,0.0) [0.0|7.0] ""  BCM
 SG_ C_ADrUNValueSet : 4|3@1+ (1.0,0.0) [0.0|7.0] ""  BCM
 SG_ C_TwUnNValueSet : 8|2@1+ (1.0,0.0) [0.0|3.0] ""  BCM
 SG_ C_ABuzzerNValueSet : 10|2@1+ (1.0,0.0) [0.0|3.0] ""  BCM
 SG_ C_ArmWKeyNValueSet : 12|2@1+ (1.0,0.0) [0.0|3.0] ""  BCM
 SG_ C_PSMNValueSet : 14|2@1+ (1.0,0.0) [0.0|3.0] ""  BCM
 SG_ C_SCMNValueSet : 16|2@1+ (1.0,0.0) [0.0|3.0] ""  BCM
 SG_ C_HLEscortNValueSet : 18|2@1+ (1.0,0.0) [0.0|3.0] ""  BCM
 SG_ C_WELNValueSet : 20|2@1+ (1.0,0.0) [0.0|3.0] ""  BCM
 SG_ C_TriTurnLNValueSet : 22|2@1+ (1.0,0.0) [0.0|3.0] ""  BCM
 SG_ C_SNVWarnNValueSet : 24|2@1+ (1.0,0.0) [0.0|3.0] ""  BCM
 SG_ C_LkasWarnNValueSet : 26|2@1+ (1.0,0.0) [0.0|3.0] ""  BCM

BO_ 1322 CLU15: 8 CLU
 SG_ CF_Clu_VehicleSpeed : 0|8@1+ (1.0,0.0) [0.0|255.0] ""  BCM
 SG_ CF_Clu_Gear : 9|4@1+ (1,0) [0|15] "" BCM
 SG_ CF_Clu_HudInfoSet : 13|7@1+ (1.0,0.0) [0.0|127.0] ""  HUD
 SG_ CF_Clu_HudFontColorSet : 20|2@1+ (1.0,0.0) [0.0|3.0] ""  HUD
 SG_ CF_Clu_HudBrightUpSW : 22|2@1+ (1.0,0.0) [0.0|3.0] ""  HUD
 SG_ CF_Clu_HudBrightDnSW : 24|2@1+ (1.0,0.0) [0.0|3.0] ""  HUD
 SG_ CF_Clu_HudHeightUpSW : 26|2@1+ (1.0,0.0) [0.0|3.0] ""  HUD
 SG_ CF_Clu_HudHeightDnSW : 28|2@1+ (1.0,0.0) [0.0|3.0] ""  HUD
 SG_ CF_Clu_HudSet : 30|1@1+ (1.0,0.0) [0.0|1.0] ""  HUD
 SG_ CF_Clu_HudFontSizeSet : 31|2@1+ (1.0,0.0) [0.0|3.0] ""  HUD
 SG_ CF_Clu_LanguageInfo : 33|5@1+ (1.0,0.0) [0.0|31.0] ""  BCM,PGS
 SG_ CF_Clu_ClusterSound : 38|1@1- (1.0,0.0) [0.0|0.0] ""  BCM,CGW,FATC
 SG_ CF_Clu_VehicleSpeed2 : 48|8@1+ (1,0) [0|255] "" XXX

BO_ 1338 TMU_GW_E_01: 8 CLU
 SG_ CF_Gway_TeleReqDrLock : 0|2@1+ (1.0,0.0) [0.0|3.0] ""  BCM
 SG_ CF_Gway_TeleReqDrUnlock : 2|2@1+ (1.0,0.0) [0.0|3.0] ""  BCM
 SG_ CF_Gway_TeleReqHazard : 4|2@1+ (1.0,0.0) [0.0|3.0] ""  BCM
 SG_ CF_Gway_TeleReqHorn : 6|2@1+ (1.0,0.0) [0.0|3.0] ""  BCM
 SG_ CF_Gway_TeleReqEngineOperate : 8|2@1+ (1.0,0.0) [0.0|3.0] ""  BCM

BO_ 1342 LKAS12: 6 LDWS_LKAS
 SG_ CF_Lkas_TsrSlifOpt : 10|2@1+ (1.0,0.0) [0.0|3.0] ""  CLU
 SG_ CF_LkasTsrStatus : 12|2@1+ (1.0,0.0) [0.0|3.0] ""  CLU
 SG_ CF_Lkas_TsrSpeed_Display_Clu : 16|8@1+ (1.0,0.0) [0.0|255.0] ""  CLU
 SG_ CF_LkasTsrSpeed_Display_Navi : 24|8@1+ (1.0,0.0) [0.0|255.0] ""  BCM,CLU
 SG_ CF_Lkas_TsrAddinfo_Display : 32|2@1+ (1.0,0.0) [0.0|3.0] ""  CLU
 SG_ CF_LkasDawStatus : 40|3@1+ (1,0) [0|7] "" CLU
 SG_ CF_Lkas_Daw_USM : 37|3@1+ (1,0) [0|7] "" CLU

BO_ 1345 CGW1: 8 BCM
 SG_ CF_Gway_IGNSw : 0|3@1+ (1.0,0.0) [0.0|7.0] ""  AVM,CLU,ECS,EMS,EPB,ESC,IBOX,LVR,MDPS,SAS,SCC,ECS,EMS,EPB,ESC,IBOX,LVR,MDPS,SAS,SCC
 SG_ CF_Gway_RKECmd : 3|3@1+ (1.0,0.0) [0.0|7.0] ""  CLU,ECS,EMS,IBOX,ECS,EMS,IBOX
 SG_ CF_Gway_DrvKeyLockSw : 6|1@1+ (1.0,0.0) [0.0|1.0] ""  ECS,EMS,IBOX,ECS,EMS,IBOX
 SG_ CF_Gway_DrvKeyUnlockSw : 7|1@1+ (1.0,0.0) [0.0|1.0] ""  ECS,EMS,IBOX,ECS,EMS,IBOX
 SG_ CF_Gway_DrvDrSw : 8|2@1+ (1.0,0.0) [0.0|3.0] ""  CLU,ECS,EMS,EPB,ESC,IBOX,SCC,TCU,ECS,EMS,EPB,ESC,IBOX,SCC,TCU
 SG_ CF_Gway_DrvSeatBeltSw : 10|2@1+ (1.0,0.0) [0.0|3.0] ""  EMS,EPB,ESC,IBOX,PSB,TCU,EMS,EPB,ESC,IBOX,PSB,TCU
 SG_ CF_Gway_TrunkTgSw : 12|2@1+ (1.0,0.0) [0.0|3.0] ""  CLU,ECS,EMS,EPB,ESC,IBOX,ECS,EMS,EPB,ESC,IBOX
 SG_ CF_Gway_AstSeatBeltSw : 14|2@1+ (1.0,0.0) [0.0|3.0] ""  IBOX,PSB,IBOX,PSB
 SG_ CF_Gway_SMKOption : 16|1@1+ (1.0,0.0) [0.0|1.0] ""  CLU,EMS,IBOX,EMS,IBOX,SMK
 SG_ CF_Gway_HoodSw : 17|2@1+ (1.0,0.0) [0.0|3.0] ""  CLU,EMS,EPB,ESC,IBOX,EMS,EPB,ESC,IBOX
 SG_ CF_Gway_TurnSigLh : 19|2@1+ (1.0,0.0) [0.0|3.0] ""  CLU,EMS,IBOX,LCA,LDWS_LKAS,SCC,EMS,IBOX,LCA,LDWS_LKAS,SCC
 SG_ CF_Gway_WiperIntT : 21|3@1+ (1.0,0.0) [0.0|7.0] ""  CLU,EMS,IBOX,LDWS_LKAS,EMS,ESC,IBOX,LDWS_LKAS
 SG_ CF_Gway_WiperIntSw : 24|1@1+ (1.0,0.0) [0.0|1.0] ""  CLU,EMS,IBOX,LDWS_LKAS,EMS,ESC,IBOX,LDWS_LKAS
 SG_ CF_Gway_WiperLowSw : 25|1@1+ (1.0,0.0) [0.0|1.0] ""  CLU,EMS,IBOX,LDWS_LKAS,EMS,ESC,IBOX,LDWS_LKAS
 SG_ CF_Gway_WiperHighSw : 26|1@1+ (1.0,0.0) [0.0|1.0] ""  CLU,EMS,IBOX,LDWS_LKAS,EMS,ESC,IBOX,LDWS_LKAS
 SG_ CF_Gway_WiperAutoSw : 27|1@1+ (1.0,0.0) [0.0|1.0] ""  CLU,EMS,IBOX,LDWS_LKAS,EMS,ESC,IBOX,LDWS_LKAS
 SG_ CF_Gway_RainSnsState : 28|3@1+ (1.0,0.0) [0.0|7.0] ""  AFLS,EMS,IBOX,LDWS_LKAS,AFLS,EMS,ESC,IBOX,LDWS_LKAS
 SG_ CF_Gway_HeadLampLow : 31|1@1+ (1.0,0.0) [0.0|1.0] ""  AFLS,CLU,EMS,IBOX,LDWS_LKAS,SNV,AFLS,EMS,IBOX,LDWS_LKAS,SNV
 SG_ CF_Gway_HeadLampHigh : 32|1@1+ (1.0,0.0) [0.0|1.0] ""  AFLS,CLU,EMS,IBOX,LDWS_LKAS,AFLS,EMS,IBOX,LDWS_LKAS
 SG_ CF_Gway_HazardSw : 33|2@1+ (1.0,0.0) [0.0|3.0] ""  ABS,EMS,ESC,IBOX,LCA,LDWS_LKAS,ABS,EMS,ESC,IBOX,LCA,LDWS_LKAS
 SG_ CF_Gway_AstDrSw : 35|1@1+ (1.0,0.0) [0.0|1.0] ""  CLU,IBOX,IBOX
 SG_ CF_Gway_DefoggerRly : 36|1@1+ (1.0,0.0) [0.0|1.0] ""  EMS,IBOX,EMS,IBOX
 SG_ CF_Gway_ALightStat : 37|1@1+ (1.0,0.0) [0.0|1.0] ""  AFLS,IBOX,LDWS_LKAS,AFLS,IBOX,LDWS_LKAS
 SG_ CF_Gway_LightSwState : 38|2@1+ (1.0,0.0) [0.0|3.0] ""  AFLS,IBOX,LDWS_LKAS,AFLS,IBOX,LDWS_LKAS
 SG_ CF_Gway_Frt_Fog_Act : 40|1@1+ (1.0,0.0) [0.0|1.0] ""  AFLS,CLU,IBOX,LDWS_LKAS,AFLS,IBOX,LDWS_LKAS
 SG_ CF_Gway_TSigRHSw : 41|1@1+ (1.0,0.0) [0.0|1.0] ""  IBOX,LDWS_LKAS,IBOX,LDWS_LKAS
 SG_ CF_Gway_TSigLHSw : 42|1@1+ (1.0,0.0) [0.0|1.0] ""  IBOX,LDWS_LKAS,IBOX,LDWS_LKAS
 SG_ CF_Gway_DriveTypeOption : 43|1@1+ (1.0,0.0) [0.0|1.0] ""  CLU,IBOX,LDWS_LKAS,IBOX,LDWS_LKAS
 SG_ CF_Gway_StarterRlyState : 44|1@1+ (1.0,0.0) [0.0|1.0] ""  EMS,IBOX,EMS,IBOX,SMK
 SG_ CF_Gway_PassiveAccessLock : 45|2@1+ (1.0,0.0) [0.0|7.0] ""  CLU,ECS,EMS,IBOX,ECS,EMS,IBOX,SMK
 SG_ CF_Gway_WiperMistSw : 47|1@1+ (1.0,0.0) [0.0|1.0] ""  CLU,EMS,IBOX,LDWS_LKAS
 SG_ CF_Gway_PassiveAccessUnlock : 48|2@1+ (1.0,0.0) [0.0|7.0] ""  CLU,ECS,EMS,IBOX,ECS,EMS,IBOX,SMK
 SG_ CF_Gway_RrSunRoofOpenState : 50|1@1+ (1.0,0.0) [0.0|1.0] ""  CLU,DATC,IBOX
 SG_ CF_Gway_PassingSW : 51|1@1+ (1.0,0.0) [0.0|1.0] ""  AFLS,IBOX,LDWS_LKAS,AFLS,IBOX,LDWS_LKAS
 SG_ CF_Gway_HBAControlMode : 52|1@1+ (1.0,0.0) [0.0|1.0] ""  IBOX,LDWS_LKAS,IBOX,LDWS_LKAS
 SG_ CF_Gway_HLpHighSw : 53|1@1+ (1.0,0.0) [0.0|1.0] ""  IBOX,LDWS_LKAS,IBOX,LDWS_LKAS
 SG_ CF_Gway_InhibitRMT : 54|2@1+ (1.0,0.0) [0.0|3.0] ""  EMS,EPB,ESC,IBOX,LCA,LDWS_LKAS,MDPS,PGS,SCC,SPAS,TPMS,EPB,ESC,IBOX,LCA,LDWS_LKAS,PGS,SCC,SPAS,TPMS
 SG_ CF_Gway_RainSnsOption : 56|1@1+ (1.0,0.0) [0.0|1.0] ""  CLU
 SG_ C_SunRoofOpenState : 57|1@1+ (1.0,0.0) [0.0|1.0] ""  CLU,DATC,IBOX,DATC,IBOX
 SG_ CF_Gway_Ign1 : 58|1@1+ (1.0,0.0) [0.0|1.0] ""  CLU
 SG_ CF_Gway_Ign2 : 59|1@1+ (1.0,0.0) [0.0|1.0] ""  CLU
 SG_ CF_Gway_ParkBrakeSw : 60|2@1+ (1.0,0.0) [0.0|3.0] ""  CLU,ESC,IBOX,SCC,ESC,IBOX,SCC
 SG_ CF_Gway_TurnSigRh : 62|2@1+ (1.0,0.0) [0.0|3.0] ""  CLU,EMS,IBOX,LCA,LDWS_LKAS,SCC,EMS,IBOX,LCA,LDWS_LKAS,SCC

BO_ 1349 EMS14: 8 EMS
 SG_ IMMO_LAMP_STAT : 0|1@1+ (1.0,0.0) [0.0|1.0] ""  CLU,IBOX
 SG_ L_MIL : 1|1@1+ (1.0,0.0) [0.0|1.0] ""  CLU,CUBIS,IBOX
 SG_ IM_STAT : 2|1@1+ (1.0,0.0) [0.0|1.0] ""  CLU,IBOX
 SG_ AMP_CAN : 3|5@1+ (10.731613,458.98) [458.98|791.660003] "mmHg"  CLU,IBOX,TCU,TPMS
 SG_ BAT_Alt_FR_Duty : 8|8@1+ (0.4,0.0) [0.0|100.0] "%"  CGW,CUBIS,IBOX,TMU
 SG_ VB : 24|8@1+ (0.1015625,0.0) [0.0|25.8984375] "V"  CLU,CUBIS,DATC,EPB,FPCM,IBOX
 SG_ EMS_VS : 32|12@1+ (0.0625,0.0) [0.0|255.875] "km/h"  CLU
 SG_ TEMP_FUEL : 56|8@1+ (0.75,-48.0) [-48.0|143.25] "deg"  FPCM

BO_ 1350 DI_BOX12: 8 DI_BOX
 SG_ CF_DiBox_FrtInjVDiagReg0 : 0|8@1+ (1.0,0.0) [0.0|255.0] ""  EMS
 SG_ CF_DiBox_FrtInjVDiagReg1 : 8|8@1+ (1.0,0.0) [0.0|255.0] ""  EMS
 SG_ CF_DiBox_FrtInjVDiagReg2 : 16|8@1+ (1.0,0.0) [0.0|255.0] ""  EMS
 SG_ CF_DiBox_SedInjVDiagReg0 : 24|8@1+ (1.0,0.0) [0.0|255.0] ""  EMS
 SG_ CF_DiBox_SedInjVDiagReg1 : 32|8@1+ (1.0,0.0) [0.0|255.0] ""  EMS
 SG_ CF_DiBox_SedInjVDiagReg2 : 40|8@1+ (1.0,0.0) [0.0|255.0] ""  EMS
 SG_ CR_DiBox_BatVol : 48|8@1+ (0.1,0.0) [0.0|25.5] "V"  EMS
 SG_ CF_DiBox_SedInjVChg : 56|1@1+ (1.0,0.0) [0.0|1.0] ""  EMS
 SG_ CF_DiBox_FrtInjVChg : 57|1@1+ (1.0,0.0) [0.0|1.0] ""  EMS
 SG_ CF_DiBox_SedInjVErrSPI : 58|1@1+ (1.0,0.0) [0.0|1.0] ""  EMS
 SG_ CF_DiBox_FrtInjVErrSPI : 59|1@1+ (1.0,0.0) [0.0|1.0] ""  EMS

BO_ 1351 EMS15: 8 EMS
 SG_ ECGPOvrd : 0|1@1+ (1.0,0.0) [0.0|1.0] ""  ESC,IBOX,SCC
 SG_ QECACC : 1|1@1+ (1.0,0.0) [0.0|1.0] ""  ESC,IBOX
 SG_ ECFail : 2|1@1+ (1.0,0.0) [0.0|1.0] ""  ESC,IBOX
 SG_ SwitchOffCondExt : 3|1@1+ (1.0,0.0) [0.0|1.0] ""  ESC,IBOX
 SG_ BLECFail : 4|1@1+ (1.0,0.0) [0.0|1.0] ""  ESC,IBOX
 SG_ CF_Ems_IsaAct : 5|1@1+ (1.0,0.0) [0.0|1.0] ""  CLU
 SG_ FA_PV_CAN : 8|8@1+ (0.3906,0.0) [0.0|99.2] "%"  IBOX,LDWS_LKAS,TCU
 SG_ IntAirTemp : 16|8@1+ (0.75,-48.0) [-48.0|143.25] "deg"  _4WD,ECS,EPB,IBOX,TCU
 SG_ STATE_DC_OBD : 24|7@1+ (1.0,0.0) [0.0|127.0] ""  IBOX,TCU
 SG_ INH_DC_OBD : 31|1@1+ (1.0,0.0) [0.0|1.0] ""  IBOX,TCU
 SG_ CTR_IG_CYC_OBD : 32|16@1+ (1.0,0.0) [0.0|65535.0] ""  ACU,IBOX,TCU
 SG_ CTR_CDN_OBD : 48|16@1+ (1.0,0.0) [0.0|65535.0] ""  IBOX,TCU

BO_ 1353 BAT11: 8 EMS
 SG_ BAT_SNSR_I : 0|16@1+ (0.01,-327.0) [-327.0|328.0] "A"  CGW,CUBIS,IBOX,TMU
 SG_ BAT_SOC : 16|8@1+ (1.0,0.0) [0.0|100.0] "%"  CGW,CUBIS,IBOX,TMU
 SG_ BAT_SNSR_V : 24|14@1+ (0.0010,6.0) [6.0|18.0] "V"  CGW,CUBIS,IBOX,TMU
 SG_ BAT_SNSR_Temp : 38|9@1- (0.5,-40.0) [-40.0|125.0] "deg"  CGW,CUBIS,IBOX,TMU
 SG_ BAT_SNSR_State : 47|1@1+ (1.0,0.0) [0.0|1.0] ""  CGW,CUBIS,IBOX,TMU
 SG_ BAT_SOH : 48|7@1+ (1.0,0.0) [0.0|100.0] "%"  CGW,CUBIS,IBOX,TMU
 SG_ BAT_SNSR_Invalid : 55|1@1+ (1.0,0.0) [0.0|1.0] ""  CGW,CUBIS,IBOX,TMU
 SG_ BAT_SOF : 56|7@1+ (0.1,0.0) [0.0|12.0] "V"  CGW,CUBIS,IBOX,TMU
 SG_ BAT_SNSR_Error : 63|1@1+ (1.0,0.0) [0.0|1.0] ""  CGW,CUBIS,IBOX,TMU

BO_ 1356 TCU_DCT14: 8 TCU
 SG_ Vehicle_Stop_Time : 0|5@1+ (1.0,0.0) [0.0|0.0] ""  CLU
 SG_ HILL_HOLD_WARNING : 5|1@1+ (1.0,0.0) [0.0|0.0] ""  CLU

BO_ 1360 IAP11: 3 IAP
 SG_ CF_Iap_EcoPmodSwi : 0|1@1+ (1.0,0.0) [0.0|1.0] ""  CLU
 SG_ CF_Iap_EcoPmodAct : 1|1@1+ (1.0,0.0) [0.0|1.0] ""  CLU
 SG_ CF_Iap_ReqWarn : 2|2@1+ (1.0,0.0) [0.0|3.0] ""  CLU

BO_ 1362 SNV11: 4 SNV
 SG_ CF_SNV_DisplayControl : 0|2@1+ (1.0,0.0) [0.0|3.0] ""  CLU,HUD
 SG_ CF_Snv_BeepWarning : 2|2@1+ (1.0,0.0) [0.0|3.0] ""  CLU,HUD
 SG_ CF_Snv_WarningMessage : 4|3@1+ (1.0,0.0) [0.0|7.0] ""  CLU,HUD
 SG_ CF_Snv_DetectionEnable : 7|1@1+ (1.0,0.0) [0.0|1.0] ""  BCM,CLU,HUD
 SG_ CF_Snv_PedestrianDetect : 8|2@1+ (1.0,0.0) [0.0|3.0] ""  BCM,CLU,HUD
 SG_ CF_Snv_IRLampControl : 10|2@1+ (1.0,0.0) [0.0|3.0] ""  BCM,CLU,HUD

BO_ 1363 CGW2: 8 BCM
 SG_ CF_Gway_GwayDiagState : 0|1@1+ (1.0,0.0) [0.0|3.0] ""  CLU,Dummy
 SG_ CF_Gway_DDMDiagState : 1|1@1+ (1.0,0.0) [0.0|1.0] ""  CLU,Dummy
 SG_ CF_Gway_SCMDiagState : 2|1@1+ (1.0,0.0) [0.0|1.0] ""  CLU,Dummy
 SG_ CF_Gway_PSMDiagState : 3|1@1+ (1.0,0.0) [0.0|1.0] ""  CLU,Dummy
 SG_ CF_Gway_SJBDiagState : 4|1@1+ (1.0,0.0) [0.0|1.0] ""  CLU,Dummy
 SG_ CF_Gway_IPMDiagState : 5|1@1+ (1.0,0.0) [0.0|1.0] ""  CLU,Dummy
 SG_ CF_Gway_LDMFail : 6|2@1+ (1.0,0.0) [0.0|3.0] ""  CLU,LDWS_LKAS,LDWS_LKAS
 SG_ CF_Gway_CLUSwGuiCtrl : 10|3@1+ (1.0,0.0) [0.0|63.0] ""  CLU,Dummy
 SG_ CF_Gway_CLUSwGroup : 13|1@1+ (1.0,0.0) [0.0|1.0] ""  CLU,Dummy
 SG_ CF_Gway_CLUSwMode : 14|1@1+ (1.0,0.0) [0.0|1.0] ""  CLU,Dummy
 SG_ CF_Gway_CLUSwEnter : 15|1@1+ (1.0,0.0) [0.0|1.0] ""  CLU,Dummy
 SG_ CF_Gway_AutoLightValue : 16|1@1+ (1.0,0.0) [0.0|1.0] ""  LCA,LCA
 SG_ CF_Gway_BrakeFluidSw : 17|1@1+ (1.0,0.0) [0.0|1.0] ""  CLU,Dummy
 SG_ CF_Gway_DrvSeatBeltInd : 18|2@1+ (1.0,0.0) [0.0|3.0] ""  CLU
 SG_ CF_Gway_AvTail : 20|1@1+ (1.0,0.0) [0.0|3.0] ""  CLU,SNV,SNV
 SG_ CF_Gway_RearFogAct : 21|1@1+ (1.0,0.0) [0.0|1.0] ""  CLU,Dummy
 SG_ CF_Gway_ExtTailAct : 22|1@1+ (1.0,0.0) [0.0|1.0] ""  AVM,CLU,LCA,PGS,SPAS,AVM,LCA,PGS,SPAS
 SG_ CF_Gway_RRDrSw : 23|1@1+ (1.0,0.0) [0.0|1.0] ""  CLU,Dummy
 SG_ CF_Gway_RLDrSw : 24|1@1+ (1.0,0.0) [0.0|1.0] ""  CLU,Dummy
 SG_ CF_Gway_IntTailAct : 25|1@1+ (1.0,0.0) [0.0|1.0] ""  CLU,Dummy
 SG_ CF_Gway_CountryCfg : 26|3@1+ (1.0,0.0) [0.0|7.0] ""  AVM,CLU,PGS,Dummy
 SG_ CF_Gway_WiperParkPosition : 32|1@1+ (1.0,0.0) [0.0|1.0] ""  AFLS,EMS,LDWS_LKAS,AFLS,EMS,LDWS_LKAS
 SG_ CF_Gway_HLLowLHFail : 33|1@1+ (1.0,0.0) [0.0|1.0] ""  LDWS_LKAS,SNV,LDWS_LKAS,SNV
 SG_ CF_Gway_HLLowRHFail : 34|1@1+ (1.0,0.0) [0.0|1.0] ""  LDWS_LKAS,SNV,LDWS_LKAS,SNV
 SG_ CF_Gway_ESCLFailWarn : 35|1@1+ (1.0,0.0) [0.0|1.0] ""  CLU,Dummy
 SG_ CF_Gway_ESCLNotLockedWarn : 36|1@1+ (1.0,0.0) [0.0|1.0] ""  CLU,Dummy
 SG_ CF_Gway_ESCLNotUnlockWarn : 37|1@1+ (1.0,0.0) [0.0|1.0] ""  CLU,Dummy
 SG_ CF_Gway_IDoutWarn : 38|1@1+ (1.0,0.0) [0.0|1.0] ""  CLU,Dummy
 SG_ CF_Gway_ImmoLp : 40|1@1+ (1.0,0.0) [0.0|3.0] ""  CLU,Dummy
 SG_ CF_Gway_BCMRKEID : 41|3@1+ (1.0,0.0) [0.0|7.0] ""  CLU,Dummy
 SG_ CF_Gway_VehicleNotPWarn : 44|1@1+ (1.0,0.0) [0.0|1.0] ""  CLU,Dummy
 SG_ CF_Gway_DeactivationWarn : 45|1@1+ (1.0,0.0) [0.0|1.0] ""  CLU,Dummy
 SG_ CF_Gway_KeyBATDischargeWarn : 46|1@1+ (1.0,0.0) [0.0|1.0] ""  CLU,Dummy
 SG_ CF_Gway_SSBWarn : 47|1@1+ (1.0,0.0) [0.0|1.0] ""  CLU,Dummy
 SG_ CF_Gway_SMKFobID : 48|3@1+ (1.0,0.0) [0.0|7.0] ""  CLU,Dummy
 SG_ CF_Gway_SMKRKECmd : 51|3@1+ (1.0,0.0) [0.0|7.0] ""  CLU,Dummy
 SG_ CF_Gway_AutoLightOption : 54|1@1+ (1.0,0.0) [0.0|1.0] ""  CLU
 SG_ CF_Gway_SJBDeliveryMode : 55|1@1+ (1.0,0.0) [0.0|1.0] ""  CLU,Dummy
 SG_ CF_Gway_KeyoutLp : 56|1@1+ (1.0,0.0) [0.0|1.0] ""  CLU,Dummy
 SG_ CF_Gway_SMKDispWarn : 57|4@1+ (1.0,0.0) [0.0|15.0] ""  CLU,Dummy
 SG_ CF_Gway_WngBuz : 61|3@1+ (1.0,0.0) [0.0|7.0] ""  CLU,Dummy

BO_ 1365 FPCM11: 8 FPCM
 SG_ CR_Fpcm_LPActPre : 0|8@1+ (3.137254902,0.0) [0.0|800.0] "kPa"  EMS
 SG_ CF_Fpcm_LPPumpOverCur : 8|1@1+ (1.0,0.0) [0.0|1.0] ""  EMS
 SG_ CF_Fpcm_PreSnrHi : 9|1@1+ (1.0,0.0) [0.0|1.0] ""  EMS
 SG_ CF_Fpcm_PreSnrDisc : 10|1@1+ (1.0,0.0) [0.0|1.0] ""  EMS
 SG_ CF_Fpcm_PreSnrShort : 11|1@1+ (1.0,0.0) [0.0|1.0] ""  EMS
 SG_ CF_Fpcm_LPPumpDiscShort : 12|1@1+ (1.0,0.0) [0.0|1.0] ""  EMS
 SG_ CF_Fpcm_LP_System_Error : 13|1@1+ (1.0,0.0) [0.0|1.0] ""  EMS
 SG_ CF_Fpcm_PreSnrSigErr : 14|1@1+ (1.0,0.0) [0.0|1.0] ""  EMS
 SG_ CF_Fpcm_LPCtrCirFlt : 15|1@1+ (1.0,0.0) [0.0|1.0] ""  EMS

BO_ 1366 EngFrzFrm11: 8 EMS
 SG_ PID_04h : 0|8@1+ (0.3921568627,0.0) [0.0|100.0] "%"  AAF,TCU
 SG_ PID_05h : 8|8@1+ (1.0,-40.0) [-40.0|215.0] "deg"  AAF,TCU
 SG_ PID_0Ch : 16|16@1+ (0.25,0.0) [0.0|16383.75] "rpm"  AAF,TCU
 SG_ PID_0Dh : 32|8@1+ (1.0,0.0) [0.0|255.0] "km/h"  AAF,TCU
 SG_ PID_11h : 40|8@1+ (0.3921568627,0.0) [0.0|100.0] "%"  AAF,TCU
 SG_ PID_03h : 48|16@1+ (1.0,0.0) [0.0|65535.0] ""  AAF,TCU

BO_ 1367 EngFrzFrm12: 8 EMS
 SG_ PID_06h : 0|8@1+ (0.78125,-100.0) [-100.0|99.22] "%"  AAF,IBOX,TCU
 SG_ PID_07h : 8|8@1+ (0.78125,-100.0) [-100.0|99.22] "%"  AAF,IBOX,TCU
 SG_ PID_08h : 16|8@1+ (0.78125,-100.0) [-100.0|99.22] "%"  AAF,IBOX,TCU
 SG_ PID_09h : 24|8@1+ (0.78125,-100.0) [-100.0|99.22] "%"  AAF,IBOX,TCU
 SG_ PID_0Bh : 32|8@1+ (1.0,0.0) [0.0|255.0] "kPa"  AAF,IBOX,TCU
 SG_ PID_23h : 40|16@1+ (10.0,0.0) [0.0|655350.0] "kPa"  AAF,IBOX,TCU

BO_ 1369 CGW4: 8 BCM
 SG_ CF_Gway_MemoryP1Cmd : 0|1@1+ (1.0,0.0) [0.0|1.0] ""  CLU
 SG_ CF_Gway_MemoryP2Cmd : 1|1@1+ (1.0,0.0) [0.0|1.0] ""  CLU
 SG_ CF_Gway_PBackP1Cmd : 2|1@1+ (1.0,0.0) [0.0|1.0] ""  CLU
 SG_ CF_Gway_PBackP2Cmd : 3|1@1+ (1.0,0.0) [0.0|1.0] ""  CLU
 SG_ CF_Gway_StrgWhlHeatedState : 4|1@1+ (1.0,0.0) [0.0|1.0] ""  CLU
 SG_ CF_Gway_PBackStopCmd : 5|1@1+ (1.0,0.0) [0.0|1.0] ""  CLU,HUD
 SG_ CF_Gway_StaticBendLhAct : 6|1@1+ (1.0,0.0) [0.0|1.0] ""  CLU
 SG_ CF_Gway_StaticBendRhAct : 7|1@1+ (1.0,0.0) [0.0|1.0] ""  CLU
 SG_ CF_Gway_DrvWdwStat : 8|1@1+ (1.0,0.0) [0.0|1.0] ""  CLU
 SG_ CF_Gway_RLWdwState : 9|1@1+ (1.0,0.0) [0.0|1.0] ""  CLU
 SG_ CF_Gway_RRWdwState : 10|1@1+ (1.0,0.0) [0.0|1.0] ""  CLU
 SG_ CF_Gway_AstWdwStat : 11|1@1+ (1.0,0.0) [0.0|1.0] ""  CLU
 SG_ CF_Gway_MemoryEnable : 12|1@1+ (1.0,0.0) [0.0|1.0] ""  CLU
 SG_ CF_Gway_PBACKStopCmd : 13|1@1+ (1.0,0.0) [0.0|1.0] ""  CLU
 SG_ CF_Gway_PBACKStop : 14|1@1+ (1.0,0.0) [0.0|1.0] ""  CLU,HUD
 SG_ CF_Gway_IMSBuzzer : 15|1@1+ (1.0,0.0) [0.0|1.0] ""  CLU
 SG_ CF_Gway_DrvSeatBeltInd : 36|2@1+ (1.0,0.0) [0.0|3.0] ""  CLU,Dummy
 SG_ CF_Gway_AstSeatBeltInd : 38|2@1+ (1.0,0.0) [0.0|3.0] ""  CLU
 SG_ CF_Gway_RCSeatBeltInd : 40|2@1+ (1.0,0.0) [0.0|3.0] ""  CLU
 SG_ CF_Gway_RLSeatBeltInd : 42|2@1+ (1.0,0.0) [0.0|3.0] ""  CLU
 SG_ CF_Gway_RRSeatBeltInd : 44|2@1+ (1.0,0.0) [0.0|3.0] ""  CLU
 SG_ CF_Gway_RrWiperHighSw : 46|1@1+ (1.0,0.0) [0.0|1.0] ""  CLU
 SG_ CF_Gway_RrWiperLowSw : 47|1@1+ (1.0,0.0) [0.0|1.0] ""  CLU

BO_ 1370 HU_AVM_PE_00: 8 CLU
 SG_ HU_AVM_Status : 0|2@1+ (1.0,0.0) [0.0|3.0] ""  AVM,PGS

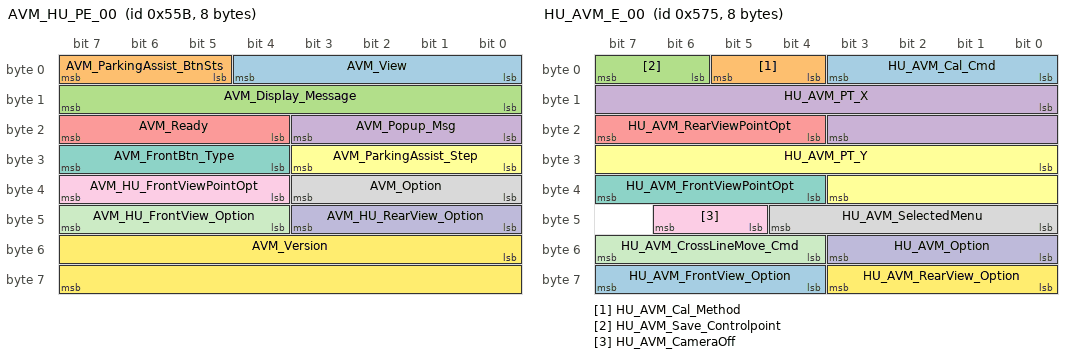
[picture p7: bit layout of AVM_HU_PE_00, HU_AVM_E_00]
BO_ 1371 AVM_HU_PE_00: 8 AVM
 SG_ AVM_View : 0|5@1+ (1.0,0.0) [0.0|31.0] ""  CLU
 SG_ AVM_ParkingAssist_BtnSts : 5|3@1+ (1.0,0.0) [0.0|7.0] ""  CLU
 SG_ AVM_Display_Message : 8|8@1+ (1.0,0.0) [0.0|255.0] ""  CLU
 SG_ AVM_Popup_Msg : 16|4@1+ (1.0,0.0) [0.0|15.0] ""  CLU
 SG_ AVM_Ready : 20|4@1+ (1.0,0.0) [0.0|15.0] ""  CLU
 SG_ AVM_ParkingAssist_Step : 24|4@1+ (1.0,0.0) [0.0|15.0] ""  CLU
 SG_ AVM_FrontBtn_Type : 28|4@1+ (1.0,0.0) [0.0|15.0] ""  CLU
 SG_ AVM_Option : 32|4@1+ (1.0,0.0) [0.0|15.0] ""  CLU
 SG_ AVM_HU_FrontViewPointOpt : 36|4@1+ (1.0,0.0) [0.0|15.0] ""  CLU
 SG_ AVM_HU_RearView_Option : 40|4@1+ (1.0,0.0) [0.0|15.0] ""  CLU
 SG_ AVM_HU_FrontView_Option : 44|4@1+ (1.0,0.0) [0.0|15.0] ""  CLU
 SG_ AVM_Version : 48|16@1+ (1.0,0.0) [0.0|65535.0] ""  CLU

BO_ 1378 HUD11: 4 HUD
 SG_ CF_Hud_HeightStaus : 0|5@1+ (1.0,0.0) [0.0|31.0] ""  CLU
 SG_ CF_Hud_PBackStatus : 6|2@1+ (1.0,0.0) [0.0|0.0] ""  BCM,CLU
 SG_ CF_Hud_Brightness : 8|5@1+ (1.0,0.0) [0.0|31.0] ""  CLU

BO_ 1379 PGS_HU_PE_01: 8 PGS
 SG_ PGS_State : 0|4@1+ (1.0,0.0) [0.0|15.0] ""  CLU
 SG_ PGS_ParkGuideState : 8|5@1+ (1.0,0.0) [0.0|31.0] ""  CLU
 SG_ PGS_Option : 16|5@1+ (1.0,0.0) [0.0|31.0] ""  CLU
 SG_ PGS_Version : 32|16@1+ (1.0,0.0) [0.0|65535.0] ""  CLU

BO_ 1393 OPI11: 5 OPI
 SG_ CR_Opi_Spd_Rpm : 0|8@1+ (20.0,0.0) [0.0|3500.0] "rpm"  TCU
 SG_ CF_Opi_Over_Temp : 8|1@1+ (1.0,0.0) [0.0|1.0] ""  TCU
 SG_ CF_Opi_Over_Cur : 9|1@1+ (1.0,0.0) [0.0|1.0] ""  EMS,TCU
 SG_ CF_Opi_Over_Vol : 10|1@1+ (1.0,0.0) [0.0|1.0] ""  TCU
 SG_ CF_Opi_Hall_Fail : 11|1@1+ (1.0,0.0) [0.0|1.0] ""  EMS,TCU
 SG_ CF_Opi_Flt : 12|1@1+ (1.0,0.0) [0.0|1.0] ""  EMS,TCU
 SG_ CF_Opi_Motor_Dir : 15|1@1+ (1.0,0.0) [0.0|1.0] ""  TCU
 SG_ CF_Opi_Romver : 16|8@1+ (1.0,0.0) [0.0|255.0] ""  TCU
 SG_ CF_Opi_PWM_Rate : 24|12@1+ (1.0,0.0) [0.0|100.0] "%"  TCU

BO_ 1395 HU_AVM_E_01: 8 CLU
 SG_ HU_PGSSelectedMenu : 0|4@1+ (1.0,0.0) [0.0|15.0] ""  AVM,PGS
 SG_ HU_PGSOption : 8|5@1+ (1.0,0.0) [0.0|31.0] ""  AVM,PGS
 SG_ HU_AVM_ParkingAssistMenu : 56|4@1+ (1.0,0.0) [0.0|15.0] ""  AVM,PGS
 SG_ HU_AVM_ParkingAssistSB : 60|4@1+ (1.0,0.0) [0.0|15.0] ""  AVM,PGS

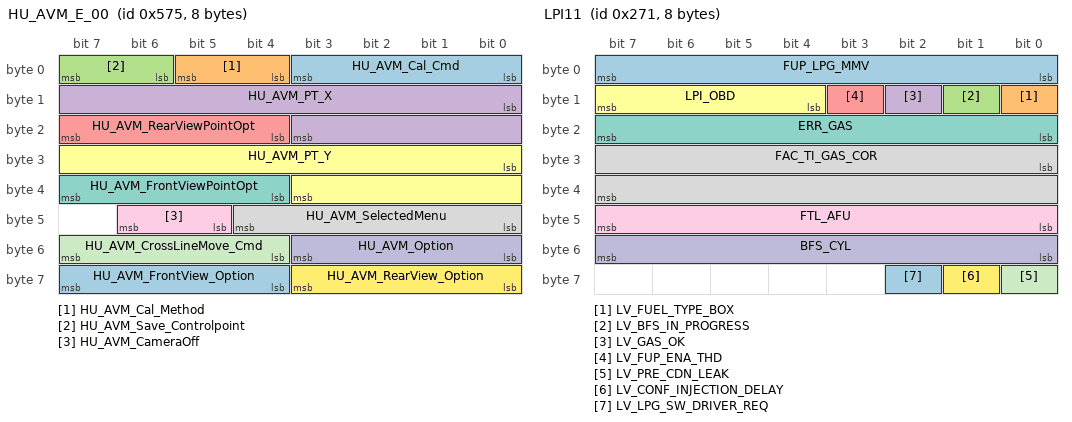
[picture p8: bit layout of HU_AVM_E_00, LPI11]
BO_ 1397 HU_AVM_E_00: 8 CLU
 SG_ HU_AVM_Cal_Cmd : 0|4@1+ (1.0,0.0) [0.0|15.0] ""  AVM,PGS
 SG_ HU_AVM_Cal_Method : 4|2@1+ (1.0,0.0) [0.0|3.0] ""  AVM,PGS
 SG_ HU_AVM_Save_Controlpoint : 6|2@1+ (1.0,0.0) [0.0|3.0] ""  AVM,PGS
 SG_ HU_AVM_PT_X : 8|12@1+ (1.0,0.0) [0.0|15.0] ""  AVM,PGS
 SG_ HU_AVM_RearViewPointOpt : 20|4@1+ (1.0,0.0) [0.0|15.0] ""  AVM,PGS
 SG_ HU_AVM_PT_Y : 24|12@1+ (1.0,0.0) [0.0|4095.0] ""  AVM,PGS
 SG_ HU_AVM_FrontViewPointOpt : 36|4@1+ (1.0,0.0) [0.0|15.0] ""  AVM,PGS
 SG_ HU_AVM_SelectedMenu : 40|5@1+ (1.0,0.0) [0.0|31.0] ""  AVM,PGS
 SG_ HU_AVM_CameraOff : 45|2@1+ (1.0,0.0) [0.0|3.0] ""  AVM,PGS
 SG_ HU_AVM_Option : 48|4@1+ (1.0,0.0) [0.0|15.0] ""  AVM,PGS
 SG_ HU_AVM_CrossLineMove_Cmd : 52|4@1+ (1.0,0.0) [0.0|15.0] ""  AVM,PGS
 SG_ HU_AVM_RearView_Option : 56|4@1+ (1.0,0.0) [0.0|15.0] ""  AVM,PGS
 SG_ HU_AVM_FrontView_Option : 60|4@1+ (1.0,0.0) [0.0|15.0] ""  AVM,PGS

VAL_ 1322 CF_Clu_Gear 1 "P" 2 "R" 4 "N" 8 "D";
VAL_ 871 CF_Lvr_Gear 12 "T" 5 "D" 8 "S" 6 "N" 7 "R" 4 "S" 0 "P";
VAL_ 871 CF_Lvr_IsgState 0 "enabled" 1 "activated" 2 "unknown" 3 "disabled";

BS_:

BU_: XXX CAMERA FRONT_RADAR ADRV APRK

BS_:

BU_: IAP ODS _4WD BCM HUD DATC MDPS AAF_Tester AEMC SMK _4WD EPB CUBIS MTS TMU EVP CGW TPMS LPI DI_BOX SPAS EMS LCA TCU IBOX FATC AFLS FPCM SCC AHLS AVM ABS SNV OPI PGS SAS AAF Dummy LDWS_LKAS LVR ESC PSB CLU ECS ACU REA

BO_ 1397 HU_AVM_E_00: 8 CLU
 SG_ HU_AVM_Cal_Cmd : 0|4@1+ (1.0,0.0) [0.0|15.0] ""  AVM,PGS
 SG_ HU_AVM_Cal_Method : 4|2@1+ (1.0,0.0) [0.0|3.0] ""  AVM,PGS
 SG_ HU_AVM_Save_Controlpoint : 6|2@1+ (1.0,0.0) [0.0|3.0] ""  AVM,PGS
 SG_ HU_AVM_PT_X : 8|12@1+ (1.0,0.0) [0.0|15.0] ""  AVM,PGS
 SG_ HU_AVM_RearViewPointOpt : 20|4@1+ (1.0,0.0) [0.0|15.0] ""  AVM,PGS
 SG_ HU_AVM_PT_Y : 24|12@1+ (1.0,0.0) [0.0|4095.0] ""  AVM,PGS
 SG_ HU_AVM_FrontViewPointOpt : 36|4@1+ (1.0,0.0) [0.0|15.0] ""  AVM,PGS
 SG_ HU_AVM_SelectedMenu : 40|5@1+ (1.0,0.0) [0.0|31.0] ""  AVM,PGS
 SG_ HU_AVM_CameraOff : 45|2@1+ (1.0,0.0) [0.0|3.0] ""  AVM,PGS
 SG_ HU_AVM_Option : 48|4@1+ (1.0,0.0) [0.0|15.0] ""  AVM,PGS
 SG_ HU_AVM_CrossLineMove_Cmd : 52|4@1+ (1.0,0.0) [0.0|15.0] ""  AVM,PGS
 SG_ HU_AVM_RearView_Option : 56|4@1+ (1.0,0.0) [0.0|15.0] ""  AVM,PGS
 SG_ HU_AVM_FrontView_Option : 60|4@1+ (1.0,0.0) [0.0|15.0] ""  AVM,PGS

BO_ 1395 HU_AVM_E_01: 8 CLU
 SG_ HU_PGSSelectedMenu : 0|4@1+ (1.0,0.0) [0.0|15.0] ""  AVM,PGS
 SG_ HU_PGSOption : 8|5@1+ (1.0,0.0) [0.0|31.0] ""  AVM,PGS
 SG_ HU_AVM_ParkingAssistMenu : 56|4@1+ (1.0,0.0) [0.0|15.0] ""  AVM,PGS
 SG_ HU_AVM_ParkingAssistSB : 60|4@1+ (1.0,0.0) [0.0|15.0] ""  AVM,PGS

BO_ 1393 OPI11: 5 OPI
 SG_ CR_Opi_Spd_Rpm : 0|8@1+ (20.0,0.0) [0.0|3500.0] "rpm"  TCU
 SG_ CF_Opi_Over_Temp : 8|1@1+ (1.0,0.0) [0.0|1.0] ""  TCU
 SG_ CF_Opi_Over_Cur : 9|1@1+ (1.0,0.0) [0.0|1.0] ""  EMS,TCU
 SG_ CF_Opi_Over_Vol : 10|1@1+ (1.0,0.0) [0.0|1.0] ""  TCU
 SG_ CF_Opi_Hall_Fail : 11|1@1+ (1.0,0.0) [0.0|1.0] ""  EMS,TCU
 SG_ CF_Opi_Flt : 12|1@1+ (1.0,0.0) [0.0|1.0] ""  EMS,TCU
 SG_ CF_Opi_Motor_Dir : 15|1@1+ (1.0,0.0) [0.0|1.0] ""  TCU
 SG_ CF_Opi_Romver : 16|8@1+ (1.0,0.0) [0.0|255.0] ""  TCU
 SG_ CF_Opi_PWM_Rate : 24|12@1+ (1.0,0.0) [0.0|100.0] "%"  TCU

BO_ 625 LPI11: 8 LPI
 SG_ FUP_LPG_MMV : 0|8@1+ (128.0,0.0) [0.0|32640.0] "hPa"  EMS
 SG_ LV_FUEL_TYPE_BOX : 8|1@1+ (1.0,0.0) [0.0|1.0] ""  EMS
 SG_ LV_BFS_IN_PROGRESS : 9|1@1+ (1.0,0.0) [0.0|1.0] ""  EMS
 SG_ LV_GAS_OK : 10|1@1+ (1.0,0.0) [0.0|1.0] ""  EMS
 SG_ LV_FUP_ENA_THD : 11|1@1+ (1.0,0.0) [0.0|1.0] ""  BCM,CLU,EMS,SMK
 SG_ LPI_OBD : 12|4@1+ (1.0,0.0) [0.0|15.0] ""  EMS
 SG_ ERR_GAS : 16|8@1+ (1.0,0.0) [0.0|255.0] ""  EMS
 SG_ FAC_TI_GAS_COR : 24|16@1+ (3.05E-5,0.0) [0.0|1.9988175] ""  EMS
 SG_ FTL_AFU : 40|8@1+ (0.392,0.0) [0.0|99.96] "%"  EMS
 SG_ BFS_CYL : 48|8@1+ (1.0,0.0) [0.0|6.0] "Cyl Nr."  EMS
 SG_ LV_PRE_CDN_LEAK : 56|1@1+ (1.0,0.0) [0.0|1.0] ""  EMS
 SG_ LV_CONF_INJECTION_DELAY : 57|1@1+ (1.0,0.0) [0.0|1.0] ""  EMS
 SG_ LV_LPG_SW_DRIVER_REQ : 58|1@1+ (1.0,0.0) [0.0|1.0] ""  EMS

BO_ 356 VSM11: 4 ESC
 SG_ CR_Esc_StrTqReq : 0|12@1+ (0.01,-20.48) [-20.48|20.47] "Nm"  MDPS
 SG_ CF_Esc_Act : 12|1@1+ (1.0,0.0) [0.0|1.0] ""  LDWS_LKAS,MDPS
 SG_ CF_Esc_CtrMode : 13|3@1+ (1.0,0.0) [0.0|7.0] ""  MDPS
 SG_ CF_Esc_Def : 16|1@1+ (1.0,0.0) [0.0|1.0] ""  MDPS
 SG_ CF_Esc_AliveCnt : 17|4@1+ (1.0,0.0) [0.0|15.0] ""  LDWS_LKAS,MDPS
 SG_ CF_Esc_Chksum : 24|8@1+ (1.0,0.0) [0.0|255.0] ""  LDWS_LKAS,MDPS

BO_ 1379 PGS_HU_PE_01: 8 PGS
 SG_ PGS_State : 0|4@1+ (1.0,0.0) [0.0|15.0] ""  CLU
 SG_ PGS_ParkGuideState : 8|5@1+ (1.0,0.0) [0.0|31.0] ""  CLU
 SG_ PGS_Option : 16|5@1+ (1.0,0.0) [0.0|31.0] ""  CLU
 SG_ PGS_Version : 32|16@1+ (1.0,0.0) [0.0|65535.0] ""  CLU

BO_ 1378 HUD11: 4 HUD
 SG_ CF_Hud_HeightStaus : 0|5@1+ (1.0,0.0) [0.0|31.0] ""  CLU
 SG_ CF_Hud_PBackStatus : 6|2@1+ (1.0,0.0) [0.0|0.0] ""  BCM,CLU
 SG_ CF_Hud_Brightness : 8|5@1+ (1.0,0.0) [0.0|31.0] ""  CLU

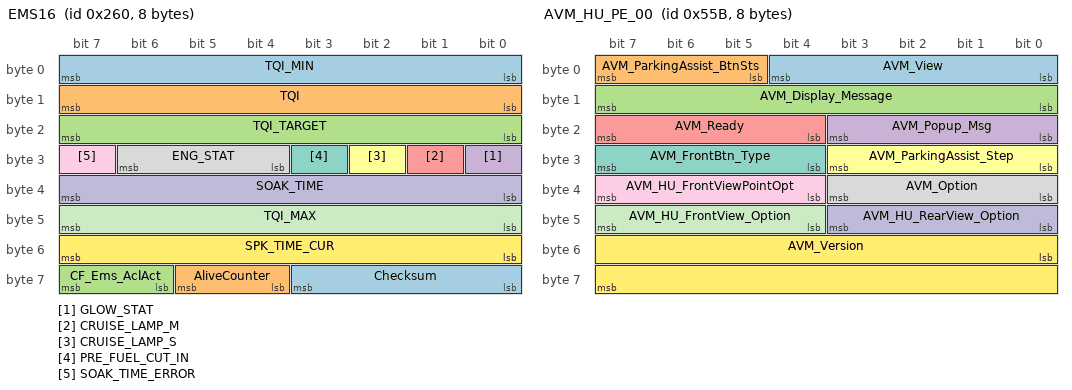
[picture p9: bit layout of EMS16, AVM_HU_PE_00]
BO_ 608 EMS16: 8 EMS
 SG_ TQI_MIN : 0|8@1+ (0.390625,0.0) [0.0|99.609375] "%"  ESC,IBOX,TCU
 SG_ TQI : 8|8@1+ (0.390625,0.0) [0.0|99.609375] "%"  ESC,IBOX,TCU
 SG_ TQI_TARGET : 16|8@1+ (0.390625,0.0) [0.0|99.609375] "%"  EPB,ESC,IBOX,TCU
 SG_ GLOW_STAT : 24|1@1+ (1.0,0.0) [0.0|1.0] ""  BCM,CLU,IBOX,SMK
 SG_ CRUISE_LAMP_M : 25|1@1+ (1.0,0.0) [0.0|1.0] ""  CLU,IBOX,TCU
 SG_ CRUISE_LAMP_S : 26|1@1+ (1.0,0.0) [0.0|1.0] ""  CLU,IBOX,TCU
 SG_ PRE_FUEL_CUT_IN : 27|1@1+ (1.0,0.0) [0.0|1.0] ""  IBOX,TCU
 SG_ ENG_STAT : 28|3@1+ (1.0,0.0) [0.0|7.0] ""  ABS,AHLS,AVM,BCM,CLU,EPB,ESC,EVP,FPCM,IBOX,LCA,LDWS_LKAS,MDPS,SCC,SMK,TCU
 SG_ SOAK_TIME_ERROR : 31|1@1+ (1.0,0.0) [0.0|1.0] ""  DATC,EPB,IBOX,TCU
 SG_ SOAK_TIME : 32|8@1+ (1.0,0.0) [0.0|255.0] "Min"  _4WD,DATC,EPB,IBOX,TCU
 SG_ TQI_MAX : 40|8@1+ (0.390625,0.0) [0.0|99.609375] "%"  ESC,IBOX,TCU
 SG_ SPK_TIME_CUR : 48|8@1+ (0.375,-35.625) [-35.625|60.0] ""  IBOX,TCU
 SG_ Checksum : 56|4@1+ (1.0,0.0) [0.0|15.0] ""  ECS,IBOX,LDWS_LKAS,MDPS,SCC
 SG_ AliveCounter : 60|2@1+ (1.0,0.0) [0.0|3.0] ""  IBOX,LDWS_LKAS,MDPS,SCC
 SG_ CF_Ems_AclAct : 62|2@1+ (1.0,0.0) [0.0|3.0] ""  IBOX,SCC

BO_ 1371 AVM_HU_PE_00: 8 AVM
 SG_ AVM_View : 0|5@1+ (1.0,0.0) [0.0|31.0] ""  CLU
 SG_ AVM_ParkingAssist_BtnSts : 5|3@1+ (1.0,0.0) [0.0|7.0] ""  CLU
 SG_ AVM_Display_Message : 8|8@1+ (1.0,0.0) [0.0|255.0] ""  CLU
 SG_ AVM_Popup_Msg : 16|4@1+ (1.0,0.0) [0.0|15.0] ""  CLU
 SG_ AVM_Ready : 20|4@1+ (1.0,0.0) [0.0|15.0] ""  CLU
 SG_ AVM_ParkingAssist_Step : 24|4@1+ (1.0,0.0) [0.0|15.0] ""  CLU
 SG_ AVM_FrontBtn_Type : 28|4@1+ (1.0,0.0) [0.0|15.0] ""  CLU
 SG_ AVM_Option : 32|4@1+ (1.0,0.0) [0.0|15.0] ""  CLU
 SG_ AVM_HU_FrontViewPointOpt : 36|4@1+ (1.0,0.0) [0.0|15.0] ""  CLU
 SG_ AVM_HU_RearView_Option : 40|4@1+ (1.0,0.0) [0.0|15.0] ""  CLU
 SG_ AVM_HU_FrontView_Option : 44|4@1+ (1.0,0.0) [0.0|15.0] ""  CLU
 SG_ AVM_Version : 48|16@1+ (1.0,0.0) [0.0|65535.0] ""  CLU

BO_ 1370 HU_AVM_PE_00: 8 CLU
 SG_ HU_AVM_Status : 0|2@1+ (1.0,0.0) [0.0|3.0] ""  AVM,PGS

BO_ 1369 CGW4: 8 BCM
 SG_ CF_Gway_MemoryP1Cmd : 0|1@1+ (1.0,0.0) [0.0|1.0] ""  CLU
 SG_ CF_Gway_MemoryP2Cmd : 1|1@1+ (1.0,0.0) [0.0|1.0] ""  CLU
 SG_ CF_Gway_PBackP1Cmd : 2|1@1+ (1.0,0.0) [0.0|1.0] ""  CLU
 SG_ CF_Gway_PBackP2Cmd : 3|1@1+ (1.0,0.0) [0.0|1.0] ""  CLU
 SG_ CF_Gway_StrgWhlHeatedState : 4|1@1+ (1.0,0.0) [0.0|1.0] ""  CLU
 SG_ CF_Gway_PBackStopCmd : 5|1@1+ (1.0,0.0) [0.0|1.0] ""  CLU,HUD
 SG_ CF_Gway_StaticBendLhAct : 6|1@1+ (1.0,0.0) [0.0|1.0] ""  CLU
 SG_ CF_Gway_StaticBendRhAct : 7|1@1+ (1.0,0.0) [0.0|1.0] ""  CLU
 SG_ CF_Gway_DrvWdwStat : 8|1@1+ (1.0,0.0) [0.0|1.0] ""  CLU
 SG_ CF_Gway_RLWdwState : 9|1@1+ (1.0,0.0) [0.0|1.0] ""  CLU
 SG_ CF_Gway_RRWdwState : 10|1@1+ (1.0,0.0) [0.0|1.0] ""  CLU
 SG_ CF_Gway_AstWdwStat : 11|1@1+ (1.0,0.0) [0.0|1.0] ""  CLU
 SG_ CF_Gway_MemoryEnable : 12|1@1+ (1.0,0.0) [0.0|1.0] ""  CLU
 SG_ CF_Gway_PBACKStopCmd : 13|1@1+ (1.0,0.0) [0.0|1.0] ""  CLU
 SG_ CF_Gway_PBACKStop : 14|1@1+ (1.0,0.0) [0.0|1.0] ""  CLU,HUD
 SG_ CF_Gway_IMSBuzzer : 15|1@1+ (1.0,0.0) [0.0|1.0] ""  CLU
 SG_ CF_Gway_DrvSeatBeltInd : 36|2@1+ (1.0,0.0) [0.0|3.0] ""  CLU,Dummy
 SG_ CF_Gway_AstSeatBeltInd : 38|2@1+ (1.0,0.0) [0.0|3.0] ""  CLU
 SG_ CF_Gway_RCSeatBeltInd : 40|2@1+ (1.0,0.0) [0.0|3.0] ""  CLU
 SG_ CF_Gway_RLSeatBeltInd : 42|2@1+ (1.0,0.0) [0.0|3.0] ""  CLU
 SG_ CF_Gway_RRSeatBeltInd : 44|2@1+ (1.0,0.0) [0.0|3.0] ""  CLU
 SG_ CF_Gway_RrWiperHighSw : 46|1@1+ (1.0,0.0) [0.0|1.0] ""  CLU
 SG_ CF_Gway_RrWiperLowSw : 47|1@1+ (1.0,0.0) [0.0|1.0] ""  CLU

BO_ 1367 EngFrzFrm12: 8 EMS
 SG_ PID_06h : 0|8@1+ (0.78125,-100.0) [-100.0|99.22] "%"  AAF,IBOX,TCU
 SG_ PID_07h : 8|8@1+ (0.78125,-100.0) [-100.0|99.22] "%"  AAF,IBOX,TCU
 SG_ PID_08h : 16|8@1+ (0.78125,-100.0) [-100.0|99.22] "%"  AAF,IBOX,TCU
 SG_ PID_09h : 24|8@1+ (0.78125,-100.0) [-100.0|99.22] "%"  AAF,IBOX,TCU
 SG_ PID_0Bh : 32|8@1+ (1.0,0.0) [0.0|255.0] "kPa"  AAF,IBOX,TCU
 SG_ PID_23h : 40|16@1+ (10.0,0.0) [0.0|655350.0] "kPa"  AAF,IBOX,TCU

BO_ 1366 EngFrzFrm11: 8 EMS
 SG_ PID_04h : 0|8@1+ (0.3921568627,0.0) [0.0|100.0] "%"  AAF,TCU
 SG_ PID_05h : 8|8@1+ (1.0,-40.0) [-40.0|215.0] "deg"  AAF,TCU
 SG_ PID_0Ch : 16|16@1+ (0.25,0.0) [0.0|16383.75] "rpm"  AAF,TCU
 SG_ PID_0Dh : 32|8@1+ (1.0,0.0) [0.0|255.0] "km/h"  AAF,TCU
 SG_ PID_11h : 40|8@1+ (0.3921568627,0.0) [0.0|100.0] "%"  AAF,TCU
 SG_ PID_03h : 48|16@1+ (1.0,0.0) [0.0|65535.0] ""  AAF,TCU

BO_ 1365 FPCM11: 8 FPCM
 SG_ CR_Fpcm_LPActPre : 0|8@1+ (3.137254902,0.0) [0.0|800.0] "kPa"  EMS
 SG_ CF_Fpcm_LPPumpOverCur : 8|1@1+ (1.0,0.0) [0.0|1.0] ""  EMS
 SG_ CF_Fpcm_PreSnrHi : 9|1@1+ (1.0,0.0) [0.0|1.0] ""  EMS
 SG_ CF_Fpcm_PreSnrDisc : 10|1@1+ (1.0,0.0) [0.0|1.0] ""  EMS
 SG_ CF_Fpcm_PreSnrShort : 11|1@1+ (1.0,0.0) [0.0|1.0] ""  EMS
 SG_ CF_Fpcm_LPPumpDiscShort : 12|1@1+ (1.0,0.0) [0.0|1.0] ""  EMS
 SG_ CF_Fpcm_LP_System_Error : 13|1@1+ (1.0,0.0) [0.0|1.0] ""  EMS
 SG_ CF_Fpcm_PreSnrSigErr : 14|1@1+ (1.0,0.0) [0.0|1.0] ""  EMS
 SG_ CF_Fpcm_LPCtrCirFlt : 15|1@1+ (1.0,0.0) [0.0|1.0] ""  EMS

BO_ 871 LVR12: 8 LVR
 SG_ CF_Lvr_CruiseSet : 0|8@1+ (1.0,0.0) [0.0|255.0] "" CLU,TCU
 SG_ CF_Lvr_IsgState : 8|2@1+ (1.0,0.0) [0.0|3.0] "" CLU,TCU
 SG_ CF_Lvr_Gear : 32|4@1+ (1.0,0.0) [0.0|15.0] ""  CLU,TCU

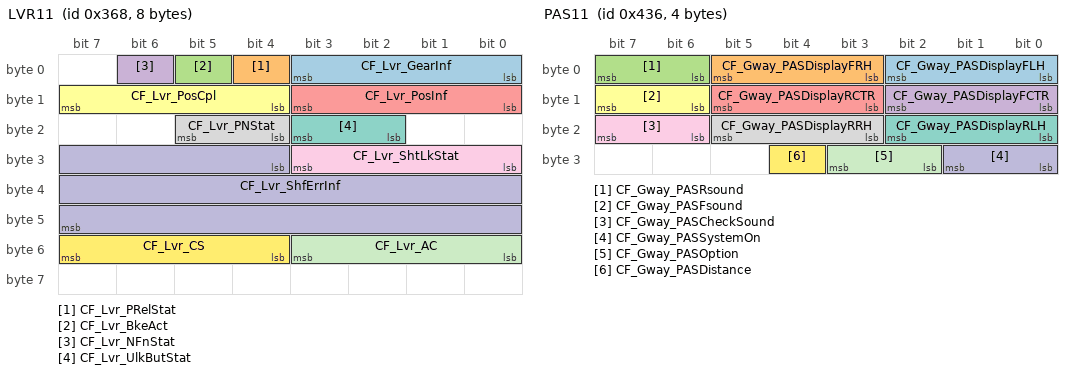
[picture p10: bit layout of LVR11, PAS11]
BO_ 872 LVR11: 8 LVR
 SG_ CF_Lvr_GearInf : 0|4@1+ (1.0,0.0) [0.0|15.0] ""  CLU,TCU
 SG_ CF_Lvr_PRelStat : 4|1@1+ (1.0,0.0) [0.0|1.0] ""  BCM,CLU,SMK,TCU
 SG_ CF_Lvr_BkeAct : 5|1@1+ (1.0,0.0) [0.0|1.0] ""  TCU
 SG_ CF_Lvr_NFnStat : 6|1@1+ (1.0,0.0) [0.0|1.0] ""  CLU
 SG_ CF_Lvr_PosInf : 8|4@1+ (1.0,0.0) [0.0|15.0] ""  TCU
 SG_ CF_Lvr_PosCpl : 12|4@1+ (1.0,0.0) [0.0|15.0] ""  TCU
 SG_ CF_Lvr_UlkButStat : 18|2@1+ (1.0,0.0) [0.0|3.0] ""  TCU
 SG_ CF_Lvr_PNStat : 20|2@1+ (1.0,0.0) [0.0|3.0] ""  CLU
 SG_ CF_Lvr_ShtLkStat : 24|4@1+ (1.0,0.0) [0.0|15.0] ""  TCU
 SG_ CF_Lvr_ShfErrInf : 28|20@1+ (1.0,0.0) [0.0|8191.0] ""  CLU,TCU
 SG_ CF_Lvr_AC : 48|4@1+ (1.0,0.0) [0.0|15.0] ""  TCU
 SG_ CF_Lvr_CS : 52|4@1+ (1.0,0.0) [0.0|15.0] ""  TCU

BO_ 1363 CGW2: 8 BCM
 SG_ CF_Gway_GwayDiagState : 0|1@1+ (1.0,0.0) [0.0|3.0] ""  CLU,Dummy
 SG_ CF_Gway_DDMDiagState : 1|1@1+ (1.0,0.0) [0.0|1.0] ""  CLU,Dummy
 SG_ CF_Gway_SCMDiagState : 2|1@1+ (1.0,0.0) [0.0|1.0] ""  CLU,Dummy
 SG_ CF_Gway_PSMDiagState : 3|1@1+ (1.0,0.0) [0.0|1.0] ""  CLU,Dummy
 SG_ CF_Gway_SJBDiagState : 4|1@1+ (1.0,0.0) [0.0|1.0] ""  CLU,Dummy
 SG_ CF_Gway_IPMDiagState : 5|1@1+ (1.0,0.0) [0.0|1.0] ""  CLU,Dummy
 SG_ CF_Gway_LDMFail : 6|2@1+ (1.0,0.0) [0.0|3.0] ""  CLU,LDWS_LKAS,LDWS_LKAS
 SG_ CF_Gway_CLUSwGuiCtrl : 10|3@1+ (1.0,0.0) [0.0|63.0] ""  CLU,Dummy
 SG_ CF_Gway_CLUSwGroup : 13|1@1+ (1.0,0.0) [0.0|1.0] ""  CLU,Dummy
 SG_ CF_Gway_CLUSwMode : 14|1@1+ (1.0,0.0) [0.0|1.0] ""  CLU,Dummy
 SG_ CF_Gway_CLUSwEnter : 15|1@1+ (1.0,0.0) [0.0|1.0] ""  CLU,Dummy
 SG_ CF_Gway_AutoLightValue : 16|1@1+ (1.0,0.0) [0.0|1.0] ""  LCA,LCA
 SG_ CF_Gway_BrakeFluidSw : 17|1@1+ (1.0,0.0) [0.0|1.0] ""  CLU,Dummy
 SG_ CF_Gway_DrvSeatBeltInd : 18|2@1+ (1.0,0.0) [0.0|3.0] ""  CLU
 SG_ CF_Gway_AvTail : 20|1@1+ (1.0,0.0) [0.0|3.0] ""  CLU,SNV,SNV
 SG_ CF_Gway_RearFogAct : 21|1@1+ (1.0,0.0) [0.0|1.0] ""  CLU,Dummy
 SG_ CF_Gway_ExtTailAct : 22|1@1+ (1.0,0.0) [0.0|1.0] ""  AVM,CLU,LCA,PGS,SPAS,AVM,LCA,PGS,SPAS
 SG_ CF_Gway_RRDrSw : 23|1@1+ (1.0,0.0) [0.0|1.0] ""  CLU,Dummy
 SG_ CF_Gway_RLDrSw : 24|1@1+ (1.0,0.0) [0.0|1.0] ""  CLU,Dummy
 SG_ CF_Gway_IntTailAct : 25|1@1+ (1.0,0.0) [0.0|1.0] ""  CLU,Dummy
 SG_ CF_Gway_CountryCfg : 26|3@1+ (1.0,0.0) [0.0|7.0] ""  AVM,CLU,PGS,Dummy
 SG_ CF_Gway_WiperParkPosition : 32|1@1+ (1.0,0.0) [0.0|1.0] ""  AFLS,EMS,LDWS_LKAS,AFLS,EMS,LDWS_LKAS
 SG_ CF_Gway_HLLowLHFail : 33|1@1+ (1.0,0.0) [0.0|1.0] ""  LDWS_LKAS,SNV,LDWS_LKAS,SNV
 SG_ CF_Gway_HLLowRHFail : 34|1@1+ (1.0,0.0) [0.0|1.0] ""  LDWS_LKAS,SNV,LDWS_LKAS,SNV
 SG_ CF_Gway_ESCLFailWarn : 35|1@1+ (1.0,0.0) [0.0|1.0] ""  CLU,Dummy
 SG_ CF_Gway_ESCLNotLockedWarn : 36|1@1+ (1.0,0.0) [0.0|1.0] ""  CLU,Dummy
 SG_ CF_Gway_ESCLNotUnlockWarn : 37|1@1+ (1.0,0.0) [0.0|1.0] ""  CLU,Dummy
 SG_ CF_Gway_IDoutWarn : 38|1@1+ (1.0,0.0) [0.0|1.0] ""  CLU,Dummy
 SG_ CF_Gway_ImmoLp : 40|1@1+ (1.0,0.0) [0.0|3.0] ""  CLU,Dummy
 SG_ CF_Gway_BCMRKEID : 41|3@1+ (1.0,0.0) [0.0|7.0] ""  CLU,Dummy
 SG_ CF_Gway_VehicleNotPWarn : 44|1@1+ (1.0,0.0) [0.0|1.0] ""  CLU,Dummy
 SG_ CF_Gway_DeactivationWarn : 45|1@1+ (1.0,0.0) [0.0|1.0] ""  CLU,Dummy
 SG_ CF_Gway_KeyBATDischargeWarn : 46|1@1+ (1.0,0.0) [0.0|1.0] ""  CLU,Dummy
 SG_ CF_Gway_SSBWarn : 47|1@1+ (1.0,0.0) [0.0|1.0] ""  CLU,Dummy
 SG_ CF_Gway_SMKFobID : 48|3@1+ (1.0,0.0) [0.0|7.0] ""  CLU,Dummy
 SG_ CF_Gway_SMKRKECmd : 51|3@1+ (1.0,0.0) [0.0|7.0] ""  CLU,Dummy
 SG_ CF_Gway_AutoLightOption : 54|1@1+ (1.0,0.0) [0.0|1.0] ""  CLU
 SG_ CF_Gway_SJBDeliveryMode : 55|1@1+ (1.0,0.0) [0.0|1.0] ""  CLU,Dummy
 SG_ CF_Gway_KeyoutLp : 56|1@1+ (1.0,0.0) [0.0|1.0] ""  CLU,Dummy
 SG_ CF_Gway_SMKDispWarn : 57|4@1+ (1.0,0.0) [0.0|15.0] ""  CLU,Dummy
 SG_ CF_Gway_WngBuz : 61|3@1+ (1.0,0.0) [0.0|7.0] ""  CLU,Dummy

BO_ 339 TCS11: 8 ESC
 SG_ TCS_REQ : 0|1@1+ (1.0,0.0) [0.0|1.0] ""  _4WD,EMS,EPB,TCU
 SG_ MSR_C_REQ : 1|1@1+ (1.0,0.0) [0.0|1.0] ""  EMS,EPB,SCC,TCU
 SG_ TCS_PAS : 2|1@1+ (1.0,0.0) [0.0|1.0] ""  _4WD,CLU,EMS,SCC,SPAS,TCU
 SG_ TCS_GSC : 3|1@1+ (1.0,0.0) [0.0|1.0] ""  _4WD,EMS,TCU
 SG_ CF_Esc_LimoInfo : 4|2@1+ (1.0,0.0) [0.0|3.0] ""  _4WD,SCC
 SG_ ABS_DIAG : 6|1@1+ (1.0,0.0) [0.0|1.0] ""  _4WD,CLU,EMS,EPB
 SG_ ABS_DEF : 7|1@1+ (1.0,0.0) [0.0|1.0] ""  _4WD,ACU,ECS,EMS,EPB,SCC,SPAS,TCU
 SG_ TCS_DEF : 8|1@1+ (1.0,0.0) [0.0|1.0] ""  _4WD,EMS,EPB,SCC,SPAS,TCU
 SG_ TCS_CTL : 9|1@1+ (1.0,0.0) [0.0|1.0] ""  _4WD,EMS,EPB,SCC,SPAS,TCU
 SG_ ABS_ACT : 10|1@1+ (1.0,0.0) [0.0|1.0] ""  _4WD,ACU,ECS,EMS,EPB,LDWS_LKAS,SCC,SPAS,TCU
 SG_ EBD_DEF : 11|1@1+ (1.0,0.0) [0.0|1.0] ""  _4WD,EMS,EPB,SPAS,TCU
 SG_ ESP_PAS : 12|1@1+ (1.0,0.0) [0.0|1.0] ""  _4WD,ACU,CLU,EMS,EPB,LDWS_LKAS,SCC,TCU
 SG_ ESP_DEF : 13|1@1+ (1.0,0.0) [0.0|1.0] ""  _4WD,ACU,ECS,EMS,EPB,LDWS_LKAS,SCC,TCU
 SG_ ESP_CTL : 14|1@1+ (1.0,0.0) [0.0|1.0] ""  _4WD,ACU,ECS,EMS,EPB,LDWS_LKAS,SCC,SPAS,TCU
 SG_ TCS_MFRN : 15|1@1+ (1.0,0.0) [0.0|1.0] ""  EMS,EPB,TCU
 SG_ DBC_CTL : 16|1@1+ (1.0,0.0) [0.0|1.0] ""  _4WD,EMS,EPB
 SG_ DBC_PAS : 17|1@1+ (1.0,0.0) [0.0|1.0] ""  _4WD,EMS,EPB
 SG_ DBC_DEF : 18|1@1+ (1.0,0.0) [0.0|1.0] ""  _4WD,EMS,EPB
 SG_ HAC_CTL : 19|1@1+ (1.0,0.0) [0.0|1.0] ""  _4WD,CLU,EMS,EPB,TCU
 SG_ HAC_PAS : 20|1@1+ (1.0,0.0) [0.0|1.0] ""  _4WD,CLU,EMS,EPB,TCU
 SG_ HAC_DEF : 21|1@1+ (1.0,0.0) [0.0|1.0] ""  _4WD,CLU,EMS,EPB,TCU
 SG_ ESS_STAT : 22|2@1+ (1.0,0.0) [0.0|3.0] ""  _4WD,BCM,CLU,EMS,EPB
 SG_ TQI_TCS : 24|8@1+ (0.390625,0.0) [0.0|99.609375] "%"  EMS,EPB,TCU
 SG_ TQI_MSR : 32|8@1+ (0.390625,0.0) [0.0|99.609375] "%"  EMS,EPB,TCU
 SG_ TQI_SLW_TCS : 40|8@1+ (0.390625,0.0) [0.0|99.609375] "%"  EMS,EPB,TCU
 SG_ CF_Esc_BrkCtl : 48|1@1+ (1.0,0.0) [0.0|1.0] ""  EMS
 SG_ BLA_CTL : 49|2@1+ (1.0,0.0) [0.0|3.0] ""  BCM,CGW,CLU
 SG_ AliveCounter_TCS1 : 52|4@1+ (1.0,0.0) [0.0|14.0] ""  EMS,EPB,LDWS_LKAS
 SG_ CheckSum_TCS1 : 56|8@1+ (1.0,0.0) [0.0|255.0] ""  EMS,EPB,LDWS_LKAS

BO_ 1362 SNV11: 4 SNV
 SG_ CF_SNV_DisplayControl : 0|2@1+ (1.0,0.0) [0.0|3.0] ""  CLU,HUD
 SG_ CF_Snv_BeepWarning : 2|2@1+ (1.0,0.0) [0.0|3.0] ""  CLU,HUD
 SG_ CF_Snv_WarningMessage : 4|3@1+ (1.0,0.0) [0.0|7.0] ""  CLU,HUD
 SG_ CF_Snv_DetectionEnable : 7|1@1+ (1.0,0.0) [0.0|1.0] ""  BCM,CLU,HUD
 SG_ CF_Snv_PedestrianDetect : 8|2@1+ (1.0,0.0) [0.0|3.0] ""  BCM,CLU,HUD
 SG_ CF_Snv_IRLampControl : 10|2@1+ (1.0,0.0) [0.0|3.0] ""  BCM,CLU,HUD

BO_ 1360 IAP11: 3 IAP
 SG_ CF_Iap_EcoPmodSwi : 0|1@1+ (1.0,0.0) [0.0|1.0] ""  CLU
 SG_ CF_Iap_EcoPmodAct : 1|1@1+ (1.0,0.0) [0.0|1.0] ""  CLU
 SG_ CF_Iap_ReqWarn : 2|2@1+ (1.0,0.0) [0.0|3.0] ""  CLU

BO_ 1356 TCU_DCT14: 8 TCU
 SG_ Vehicle_Stop_Time : 0|5@1+ (1.0,0.0) [0.0|0.0] ""  CLU
 SG_ HILL_HOLD_WARNING : 5|1@1+ (1.0,0.0) [0.0|0.0] ""  CLU

BO_ 1353 BAT11: 8 EMS
 SG_ BAT_SNSR_I : 0|16@1+ (0.01,-327.0) [-327.0|328.0] "A"  CGW,CUBIS,IBOX,TMU
 SG_ BAT_SOC : 16|8@1+ (1.0,0.0) [0.0|100.0] "%"  CGW,CUBIS,IBOX,TMU
 SG_ BAT_SNSR_V : 24|14@1+ (0.0010,6.0) [6.0|18.0] "V"  CGW,CUBIS,IBOX,TMU
 SG_ BAT_SNSR_Temp : 38|9@1- (0.5,-40.0) [-40.0|125.0] "deg"  CGW,CUBIS,IBOX,TMU
 SG_ BAT_SNSR_State : 47|1@1+ (1.0,0.0) [0.0|1.0] ""  CGW,CUBIS,IBOX,TMU
 SG_ BAT_SOH : 48|7@1+ (1.0,0.0) [0.0|100.0] "%"  CGW,CUBIS,IBOX,TMU
 SG_ BAT_SNSR_Invalid : 55|1@1+ (1.0,0.0) [0.0|1.0] ""  CGW,CUBIS,IBOX,TMU
 SG_ BAT_SOF : 56|7@1+ (0.1,0.0) [0.0|12.0] "V"  CGW,CUBIS,IBOX,TMU
 SG_ BAT_SNSR_Error : 63|1@1+ (1.0,0.0) [0.0|1.0] ""  CGW,CUBIS,IBOX,TMU

BO_ 1351 EMS15: 8 EMS
 SG_ ECGPOvrd : 0|1@1+ (1.0,0.0) [0.0|1.0] ""  ESC,IBOX,SCC
 SG_ QECACC : 1|1@1+ (1.0,0.0) [0.0|1.0] ""  ESC,IBOX
 SG_ ECFail : 2|1@1+ (1.0,0.0) [0.0|1.0] ""  ESC,IBOX
 SG_ SwitchOffCondExt : 3|1@1+ (1.0,0.0) [0.0|1.0] ""  ESC,IBOX
 SG_ BLECFail : 4|1@1+ (1.0,0.0) [0.0|1.0] ""  ESC,IBOX
 SG_ CF_Ems_IsaAct : 5|1@1+ (1.0,0.0) [0.0|1.0] ""  CLU
 SG_ FA_PV_CAN : 8|8@1+ (0.3906,0.0) [0.0|99.2] "%"  IBOX,LDWS_LKAS,TCU
 SG_ IntAirTemp : 16|8@1+ (0.75,-48.0) [-48.0|143.25] "deg"  _4WD,ECS,EPB,IBOX,TCU
 SG_ STATE_DC_OBD : 24|7@1+ (1.0,0.0) [0.0|127.0] ""  IBOX,TCU
 SG_ INH_DC_OBD : 31|1@1+ (1.0,0.0) [0.0|1.0] ""  IBOX,TCU
 SG_ CTR_IG_CYC_OBD : 32|16@1+ (1.0,0.0) [0.0|65535.0] ""  ACU,IBOX,TCU
 SG_ CTR_CDN_OBD : 48|16@1+ (1.0,0.0) [0.0|65535.0] ""  IBOX,TCU

BO_ 1350 DI_BOX12: 8 DI_BOX
 SG_ CF_DiBox_FrtInjVDiagReg0 : 0|8@1+ (1.0,0.0) [0.0|255.0] ""  EMS
 SG_ CF_DiBox_FrtInjVDiagReg1 : 8|8@1+ (1.0,0.0) [0.0|255.0] ""  EMS
 SG_ CF_DiBox_FrtInjVDiagReg2 : 16|8@1+ (1.0,0.0) [0.0|255.0] ""  EMS
 SG_ CF_DiBox_SedInjVDiagReg0 : 24|8@1+ (1.0,0.0) [0.0|255.0] ""  EMS
 SG_ CF_DiBox_SedInjVDiagReg1 : 32|8@1+ (1.0,0.0) [0.0|255.0] ""  EMS
 SG_ CF_DiBox_SedInjVDiagReg2 : 40|8@1+ (1.0,0.0) [0.0|255.0] ""  EMS
 SG_ CR_DiBox_BatVol : 48|8@1+ (0.1,0.0) [0.0|25.5] "V"  EMS
 SG_ CF_DiBox_SedInjVChg : 56|1@1+ (1.0,0.0) [0.0|1.0] ""  EMS
 SG_ CF_DiBox_FrtInjVChg : 57|1@1+ (1.0,0.0) [0.0|1.0] ""  EMS
 SG_ CF_DiBox_SedInjVErrSPI : 58|1@1+ (1.0,0.0) [0.0|1.0] ""  EMS
 SG_ CF_DiBox_FrtInjVErrSPI : 59|1@1+ (1.0,0.0) [0.0|1.0] ""  EMS

BO_ 1349 EMS14: 8 EMS
 SG_ IMMO_LAMP_STAT : 0|1@1+ (1.0,0.0) [0.0|1.0] ""  CLU,IBOX
 SG_ L_MIL : 1|1@1+ (1.0,0.0) [0.0|1.0] ""  CLU,CUBIS,IBOX
 SG_ IM_STAT : 2|1@1+ (1.0,0.0) [0.0|1.0] ""  CLU,IBOX
 SG_ AMP_CAN : 3|5@1+ (10.731613,458.98) [458.98|791.660003] "mmHg"  CLU,IBOX,TCU,TPMS
 SG_ BAT_Alt_FR_Duty : 8|8@1+ (0.4,0.0) [0.0|100.0] "%"  CGW,CUBIS,IBOX,TMU
 SG_ VB : 24|8@1+ (0.1015625,0.0) [0.0|25.8984375] "V"  CLU,CUBIS,DATC,EPB,FPCM,IBOX
 SG_ EMS_VS : 32|12@1+ (0.0625,0.0) [0.0|255.875] "km/h"  CLU
 SG_ TEMP_FUEL : 56|8@1+ (0.75,-48.0) [-48.0|143.25] "deg"  FPCM

BO_ 68 DATC11: 8 DATC
 SG_ CF_Datc_Type : 0|8@1+ (1.0,0.0) [0.0|255.0] ""  CLU
 SG_ CF_Datc_VerMaj : 8|8@1+ (1.0,0.0) [0.0|255.0] ""  CLU
 SG_ CF_Datc_VerMin : 16|8@1+ (1.0,0.0) [0.0|255.0] ""  CLU
 SG_ CR_Datc_OutTempC : 24|8@1+ (0.5,-41.0) [-41.0|86.5] "deg"  CLU,FPCM
 SG_ CR_Datc_OutTempF : 32|8@1+ (1.0,-42.0) [-42.0|213.0] "deg"  CLU
 SG_ CF_Datc_IncarTemp : 40|8@1+ (0.5,-40.0) [-40.0|60.0] "deg"  BCM,CLU

BO_ 67 DATC13: 8 DATC
 SG_ CF_Datc_TempDispUnit : 0|2@1+ (1.0,0.0) [0.0|3.0] ""  CLU,IBOX
 SG_ CF_Datc_ModDisp : 2|4@1+ (1.0,0.0) [0.0|15.0] ""  CLU
 SG_ CF_Datc_IonClean : 6|2@1+ (1.0,0.0) [0.0|3.0] ""  CLU
 SG_ CF_Datc_ChgReqDisp : 8|2@1+ (1.0,0.0) [0.0|3.0] ""  CLU
 SG_ CF_Datc_IntakeDisp : 10|2@1+ (1.0,0.0) [0.0|3.0] ""  CLU
 SG_ CF_Datc_AutoDisp : 12|2@1+ (1.0,0.0) [0.0|3.0] ""  CLU
 SG_ CF_Datc_FrDefLed : 14|2@1+ (1.0,0.0) [0.0|3.0] ""  CLU,IBOX
 SG_ CF_Datc_AutoDefogBlink : 16|2@1+ (1.0,0.0) [0.0|3.0] ""  CLU
 SG_ CF_Datc_ClmScanDisp : 18|2@1+ (1.0,0.0) [0.0|3.0] ""  CLU
 SG_ CF_Datc_AqsDisp : 20|2@1+ (1.0,0.0) [0.0|3.0] ""  CLU
 SG_ CF_Datc_AcDisp : 22|2@1+ (1.0,0.0) [0.0|3.0] ""  CLU
 SG_ CF_Datc_OpSts : 25|3@1+ (1.0,0.0) [0.0|7.0] ""  CLU
 SG_ CF_Mtc_MaxAcDisp : 28|2@1+ (1.0,0.0) [0.0|3.0] ""  CLU
 SG_ CF_Datc_DualDisp : 30|2@1+ (1.0,0.0) [0.0|3.0] ""  CLU
 SG_ CF_Datc_PwrInf : 32|4@1+ (1.0,0.0) [0.0|15.0] ""  CLU
 SG_ CF_Datc_RearManual : 38|2@1+ (1.0,0.0) [0.0|3.0] ""  CLU
 SG_ CF_Datc_RearAutoDisp : 40|2@1+ (1.0,0.0) [0.0|1.0] ""  CLU
 SG_ CF_Datc_RearOffDisp : 42|2@1+ (1.0,0.0) [0.0|3.0] ""  CLU
 SG_ CF_Datc_RearClimateScnDisp : 44|2@1+ (1.0,0.0) [0.0|3.0] ""  CLU
 SG_ CF_Datc_RearChgReqDisp : 46|2@1+ (1.0,0.0) [0.0|3.0] ""  CLU
 SG_ CF_Datc_RearModDisp : 48|4@1+ (1.0,0.0) [0.0|15.0] ""  CLU
 SG_ CF_Datc_RearBlwDisp : 52|4@1+ (1.0,0.0) [0.0|15.0] ""  CLU
 SG_ CF_Datc_PSModDisp : 56|4@1+ (1.0,0.0) [0.0|15.0] ""  CLU
 SG_ CF_Datc_FrontBlwDisp : 60|4@1+ (1.0,0.0) [0.0|15.0] ""  CLU,IBOX

BO_ 66 DATC12: 8 DATC
 SG_ CR_Datc_DrTempDispC : 0|8@1+ (0.5,14.0) [15.0|32.0] "deg"  CLU,IBOX
 SG_ CR_Datc_DrTempDispF : 8|8@1+ (1.0,56.0) [58.0|90.0] "deg"  CLU,IBOX
 SG_ CR_Datc_PsTempDispC : 16|8@1+ (0.5,14.0) [15.0|32.0] "deg"  CLU,IBOX
 SG_ CR_Datc_PsTempDispF : 24|8@1+ (1.0,56.0) [58.0|90.0] "deg"  CLU,IBOX
 SG_ CR_Datc_RearDrTempDispC : 40|8@1+ (0.5,14.0) [15.0|32.0] "deg"  CLU
 SG_ CR_Datc_RearDrTempDispF : 48|8@1+ (1.0,58.0) [58.0|90.0] "deg"  CLU
 SG_ CF_Datc_CO2_Warning : 56|8@1+ (1.0,0.0) [0.0|3.0] ""  CLU

BO_ 1345 CGW1: 8 BCM
 SG_ CF_Gway_IGNSw : 0|3@1+ (1.0,0.0) [0.0|7.0] ""  AVM,CLU,ECS,EMS,EPB,ESC,IBOX,LVR,MDPS,SAS,SCC,ECS,EMS,EPB,ESC,IBOX,LVR,MDPS,SAS,SCC
 SG_ CF_Gway_RKECmd : 3|3@1+ (1.0,0.0) [0.0|7.0] ""  CLU,ECS,EMS,IBOX,ECS,EMS,IBOX
 SG_ CF_Gway_DrvKeyLockSw : 6|1@1+ (1.0,0.0) [0.0|1.0] ""  ECS,EMS,IBOX,ECS,EMS,IBOX
 SG_ CF_Gway_DrvKeyUnlockSw : 7|1@1+ (1.0,0.0) [0.0|1.0] ""  ECS,EMS,IBOX,ECS,EMS,IBOX
 SG_ CF_Gway_DrvDrSw : 8|2@1+ (1.0,0.0) [0.0|3.0] ""  CLU,ECS,EMS,EPB,ESC,IBOX,SCC,TCU,ECS,EMS,EPB,ESC,IBOX,SCC,TCU
 SG_ CF_Gway_DrvSeatBeltSw : 10|2@1+ (1.0,0.0) [0.0|3.0] ""  EMS,EPB,ESC,IBOX,PSB,TCU,EMS,EPB,ESC,IBOX,PSB,TCU
 SG_ CF_Gway_TrunkTgSw : 12|2@1+ (1.0,0.0) [0.0|3.0] ""  CLU,ECS,EMS,EPB,ESC,IBOX,ECS,EMS,EPB,ESC,IBOX
 SG_ CF_Gway_AstSeatBeltSw : 14|2@1+ (1.0,0.0) [0.0|3.0] ""  IBOX,PSB,IBOX,PSB
 SG_ CF_Gway_SMKOption : 16|1@1+ (1.0,0.0) [0.0|1.0] ""  CLU,EMS,IBOX,EMS,IBOX,SMK
 SG_ CF_Gway_HoodSw : 17|2@1+ (1.0,0.0) [0.0|3.0] ""  CLU,EMS,EPB,ESC,IBOX,EMS,EPB,ESC,IBOX
 SG_ CF_Gway_TurnSigLh : 19|2@1+ (1.0,0.0) [0.0|3.0] ""  CLU,EMS,IBOX,LCA,LDWS_LKAS,SCC,EMS,IBOX,LCA,LDWS_LKAS,SCC
 SG_ CF_Gway_WiperIntT : 21|3@1+ (1.0,0.0) [0.0|7.0] ""  CLU,EMS,IBOX,LDWS_LKAS,EMS,ESC,IBOX,LDWS_LKAS
 SG_ CF_Gway_WiperIntSw : 24|1@1+ (1.0,0.0) [0.0|1.0] ""  CLU,EMS,IBOX,LDWS_LKAS,EMS,ESC,IBOX,LDWS_LKAS
 SG_ CF_Gway_WiperLowSw : 25|1@1+ (1.0,0.0) [0.0|1.0] ""  CLU,EMS,IBOX,LDWS_LKAS,EMS,ESC,IBOX,LDWS_LKAS
 SG_ CF_Gway_WiperHighSw : 26|1@1+ (1.0,0.0) [0.0|1.0] ""  CLU,EMS,IBOX,LDWS_LKAS,EMS,ESC,IBOX,LDWS_LKAS
 SG_ CF_Gway_WiperAutoSw : 27|1@1+ (1.0,0.0) [0.0|1.0] ""  CLU,EMS,IBOX,LDWS_LKAS,EMS,ESC,IBOX,LDWS_LKAS
 SG_ CF_Gway_RainSnsState : 28|3@1+ (1.0,0.0) [0.0|7.0] ""  AFLS,EMS,IBOX,LDWS_LKAS,AFLS,EMS,ESC,IBOX,LDWS_LKAS
 SG_ CF_Gway_HeadLampLow : 31|1@1+ (1.0,0.0) [0.0|1.0] ""  AFLS,CLU,EMS,IBOX,LDWS_LKAS,SNV,AFLS,EMS,IBOX,LDWS_LKAS,SNV
 SG_ CF_Gway_HeadLampHigh : 32|1@1+ (1.0,0.0) [0.0|1.0] ""  AFLS,CLU,EMS,IBOX,LDWS_LKAS,AFLS,EMS,IBOX,LDWS_LKAS
 SG_ CF_Gway_HazardSw : 33|2@1+ (1.0,0.0) [0.0|3.0] ""  ABS,EMS,ESC,IBOX,LCA,LDWS_LKAS,ABS,EMS,ESC,IBOX,LCA,LDWS_LKAS
 SG_ CF_Gway_AstDrSw : 35|1@1+ (1.0,0.0) [0.0|1.0] ""  CLU,IBOX,IBOX
 SG_ CF_Gway_DefoggerRly : 36|1@1+ (1.0,0.0) [0.0|1.0] ""  EMS,IBOX,EMS,IBOX
 SG_ CF_Gway_ALightStat : 37|1@1+ (1.0,0.0) [0.0|1.0] ""  AFLS,IBOX,LDWS_LKAS,AFLS,IBOX,LDWS_LKAS
 SG_ CF_Gway_LightSwState : 38|2@1+ (1.0,0.0) [0.0|3.0] ""  AFLS,IBOX,LDWS_LKAS,AFLS,IBOX,LDWS_LKAS
 SG_ CF_Gway_Frt_Fog_Act : 40|1@1+ (1.0,0.0) [0.0|1.0] ""  AFLS,CLU,IBOX,LDWS_LKAS,AFLS,IBOX,LDWS_LKAS
 SG_ CF_Gway_TSigRHSw : 41|1@1+ (1.0,0.0) [0.0|1.0] ""  IBOX,LDWS_LKAS,IBOX,LDWS_LKAS
 SG_ CF_Gway_TSigLHSw : 42|1@1+ (1.0,0.0) [0.0|1.0] ""  IBOX,LDWS_LKAS,IBOX,LDWS_LKAS
 SG_ CF_Gway_DriveTypeOption : 43|1@1+ (1.0,0.0) [0.0|1.0] ""  CLU,IBOX,LDWS_LKAS,IBOX,LDWS_LKAS
 SG_ CF_Gway_StarterRlyState : 44|1@1+ (1.0,0.0) [0.0|1.0] ""  EMS,IBOX,EMS,IBOX,SMK
 SG_ CF_Gway_PassiveAccessLock : 45|2@1+ (1.0,0.0) [0.0|7.0] ""  CLU,ECS,EMS,IBOX,ECS,EMS,IBOX,SMK
 SG_ CF_Gway_WiperMistSw : 47|1@1+ (1.0,0.0) [0.0|1.0] ""  CLU,EMS,IBOX,LDWS_LKAS
 SG_ CF_Gway_PassiveAccessUnlock : 48|2@1+ (1.0,0.0) [0.0|7.0] ""  CLU,ECS,EMS,IBOX,ECS,EMS,IBOX,SMK
 SG_ CF_Gway_RrSunRoofOpenState : 50|1@1+ (1.0,0.0) [0.0|1.0] ""  CLU,DATC,IBOX
 SG_ CF_Gway_PassingSW : 51|1@1+ (1.0,0.0) [0.0|1.0] ""  AFLS,IBOX,LDWS_LKAS,AFLS,IBOX,LDWS_LKAS
 SG_ CF_Gway_HBAControlMode : 52|1@1+ (1.0,0.0) [0.0|1.0] ""  IBOX,LDWS_LKAS,IBOX,LDWS_LKAS
 SG_ CF_Gway_HLpHighSw : 53|1@1+ (1.0,0.0) [0.0|1.0] ""  IBOX,LDWS_LKAS,IBOX,LDWS_LKAS
 SG_ CF_Gway_InhibitRMT : 54|2@1+ (1.0,0.0) [0.0|3.0] ""  EMS,EPB,ESC,IBOX,LCA,LDWS_LKAS,MDPS,PGS,SCC,SPAS,TPMS,EPB,ESC,IBOX,LCA,LDWS_LKAS,PGS,SCC,SPAS,TPMS
 SG_ CF_Gway_RainSnsOption : 56|1@1+ (1.0,0.0) [0.0|1.0] ""  CLU
 SG_ C_SunRoofOpenState : 57|1@1+ (1.0,0.0) [0.0|1.0] ""  CLU,DATC,IBOX,DATC,IBOX
 SG_ CF_Gway_Ign1 : 58|1@1+ (1.0,0.0) [0.0|1.0] ""  CLU
 SG_ CF_Gway_Ign2 : 59|1@1+ (1.0,0.0) [0.0|1.0] ""  CLU
 SG_ CF_Gway_ParkBrakeSw : 60|2@1+ (1.0,0.0) [0.0|3.0] ""  CLU,ESC,IBOX,SCC,ESC,IBOX,SCC
 SG_ CF_Gway_TurnSigRh : 62|2@1+ (1.0,0.0) [0.0|3.0] ""  CLU,EMS,IBOX,LCA,LDWS_LKAS,SCC,EMS,IBOX,LCA,LDWS_LKAS,SCC

BO_ 832 LKAS11: 8 LDWS_LKAS
 SG_ CF_Lkas_LdwsActivemode : 0|2@1+ (1,0) [0|3] "" CLU,IBOX,PSB
 SG_ CF_Lkas_LdwsSysState : 2|4@1+ (1.0,0.0) [0.0|15.0] ""  CLU,IBOX,PSB
 SG_ CF_Lkas_SysWarning : 6|4@1+ (1.0,0.0) [0.0|15.0] ""  BCM,CLU
 SG_ CF_Lkas_LdwsLHWarning : 10|2@1+ (1.0,0.0) [0.0|3.0] ""  BCM,CLU,PSB
 SG_ CF_Lkas_LdwsRHWarning : 12|2@1+ (1.0,0.0) [0.0|3.0] ""  BCM,CLU,PSB
 SG_ CF_Lkas_HbaLamp : 14|1@1+ (1.0,0.0) [0.0|1.0] ""  CLU
 SG_ CF_Lkas_FcwBasReq : 15|1@1+ (1.0,0.0) [0.0|1.0] ""  ABS,ESC
 SG_ CR_Lkas_StrToqReq : 16|11@1+ (1.0,-1024.0) [-1024.0|1024.0] ""  MDPS
 SG_ CF_Lkas_ActToi : 27|1@1+ (1.0,0.0) [0.0|1.0] ""  MDPS
 SG_ CF_Lkas_ToiFlt : 28|1@1+ (1.0,0.0) [0.0|1.0] ""  MDPS
 SG_ CF_Lkas_HbaSysState : 29|3@1+ (1.0,0.0) [0.0|7.0] ""  BCM,CLU
 SG_ CF_Lkas_FcwOpt : 32|2@1+ (1.0,0.0) [0.0|3.0] ""  CLU
 SG_ CF_Lkas_HbaOpt : 34|2@1+ (1.0,0.0) [0.0|1.0] ""  BCM,CGW
 SG_ CF_Lkas_MsgCount : 36|4@1+ (1.0,0.0) [0.0|15.0] ""  CLU,MDPS
 SG_ CF_Lkas_FcwSysState : 40|3@1+ (1.0,0.0) [0.0|7.0] ""  CLU
 SG_ CF_Lkas_FcwCollisionWarning : 43|2@1+ (1.0,0.0) [0.0|3.0] ""  CLU
 SG_ CF_Lkas_FusionState : 45|2@1+ (1.0,0.0) [0.0|3.0] ""  SCC
 SG_ CF_Lkas_Unknown1 : 47|1@1+ (1.0,0.0) [0.0|1.0] "" XXX
 SG_ CF_Lkas_Chksum : 48|8@1+ (1.0,0.0) [0.0|255.0] ""  MDPS
 SG_ CF_Lkas_FcwOpt_USM : 56|3@1+ (1.0,0.0) [0.0|7.0] ""  CLU
 SG_ CF_Lkas_LdwsOpt_USM : 59|3@1+ (1.0,0.0) [0.0|7.0] ""  CLU,MDPS
 SG_ CF_Lkas_Unknown2 : 62|2@1+ (1.0,0.0) [0.0|1.0] "" XXX

BO_ 1342 LKAS12: 6 LDWS_LKAS
 SG_ CF_Lkas_TsrSlifOpt : 10|2@1+ (1.0,0.0) [0.0|3.0] ""  CLU
 SG_ CF_LkasTsrStatus : 12|2@1+ (1.0,0.0) [0.0|3.0] ""  CLU
 SG_ CF_Lkas_TsrSpeed_Display_Clu : 16|8@1+ (1.0,0.0) [0.0|255.0] ""  CLU
 SG_ CF_LkasTsrSpeed_Display_Navi : 24|8@1+ (1.0,0.0) [0.0|255.0] ""  BCM,CLU
 SG_ CF_Lkas_TsrAddinfo_Display : 32|2@1+ (1.0,0.0) [0.0|3.0] ""  CLU
 SG_ CF_LkasDawStatus : 40|3@1+ (1,0) [0|7] "" CLU
 SG_ CF_Lkas_Daw_USM : 37|3@1+ (1,0) [0|7] "" CLU

BO_ 1338 TMU_GW_E_01: 8 CLU
 SG_ CF_Gway_TeleReqDrLock : 0|2@1+ (1.0,0.0) [0.0|3.0] ""  BCM
 SG_ CF_Gway_TeleReqDrUnlock : 2|2@1+ (1.0,0.0) [0.0|3.0] ""  BCM
 SG_ CF_Gway_TeleReqHazard : 4|2@1+ (1.0,0.0) [0.0|3.0] ""  BCM
 SG_ CF_Gway_TeleReqHorn : 6|2@1+ (1.0,0.0) [0.0|3.0] ""  BCM
 SG_ CF_Gway_TeleReqEngineOperate : 8|2@1+ (1.0,0.0) [0.0|3.0] ""  BCM

BO_ 1078 PAS11: 4 BCM
 SG_ CF_Gway_PASDisplayFLH : 0|3@1+ (1.0,0.0) [0.0|7.0] ""  AVM,CLU,AVM
 SG_ CF_Gway_PASDisplayFRH : 3|3@1+ (1.0,0.0) [0.0|7.0] ""  AVM,CLU,AVM
 SG_ CF_Gway_PASRsound : 6|2@1+ (1.0,0.0) [0.0|3.0] ""  CLU,Dummy
 SG_ CF_Gway_PASDisplayFCTR : 8|3@1+ (1.0,0.0) [0.0|7.0] ""  AVM,CLU,AVM
 SG_ CF_Gway_PASDisplayRCTR : 11|3@1+ (1.0,0.0) [0.0|7.0] ""  AVM,CLU,PGS,AVM
 SG_ CF_Gway_PASFsound : 14|2@1+ (1.0,0.0) [0.0|3.0] ""  CLU,Dummy
 SG_ CF_Gway_PASDisplayRLH : 16|3@1+ (1.0,0.0) [0.0|7.0] ""  AVM,CLU,PGS,AVM
 SG_ CF_Gway_PASDisplayRRH : 19|3@1+ (1.0,0.0) [0.0|7.0] ""  AVM,CLU,PGS,AVM
 SG_ CF_Gway_PASCheckSound : 22|2@1+ (1.0,0.0) [0.0|3.0] ""  CLU,Dummy
 SG_ CF_Gway_PASSystemOn : 24|2@1+ (1.0,0.0) [0.0|3.0] ""  CLU,Dummy
 SG_ CF_Gway_PASOption : 26|2@1+ (1.0,0.0) [0.0|3.0] ""  CLU
 SG_ CF_Gway_PASDistance : 28|1@1+ (1.0,0.0) [0.0|1.0] ""  CLU

BO_ 48 EMS18: 6 EMS
 SG_ CF_Ems_DC1NumPerMSV : 0|8@1+ (1.0,0.0) [0.0|255.0] ""  DI_BOX
 SG_ CF_Ems_DC2NumPerMSV : 8|16@1+ (1.0,0.0) [0.0|65535.0] ""  DI_BOX
 SG_ CR_Ems_DutyCyc1MSV : 24|8@1+ (0.1953,0.0) [0.0|49.8] "%"  DI_BOX
 SG_ CR_Ems_DutyCyc2MSV : 32|8@1+ (0.13725,0.0) [0.0|35.0] "%"  DI_BOX
 SG_ CR_Ems_DutyCyc3MSV : 40|8@1+ (0.392,0.0) [0.0|100.0] "%"  DI_BOX

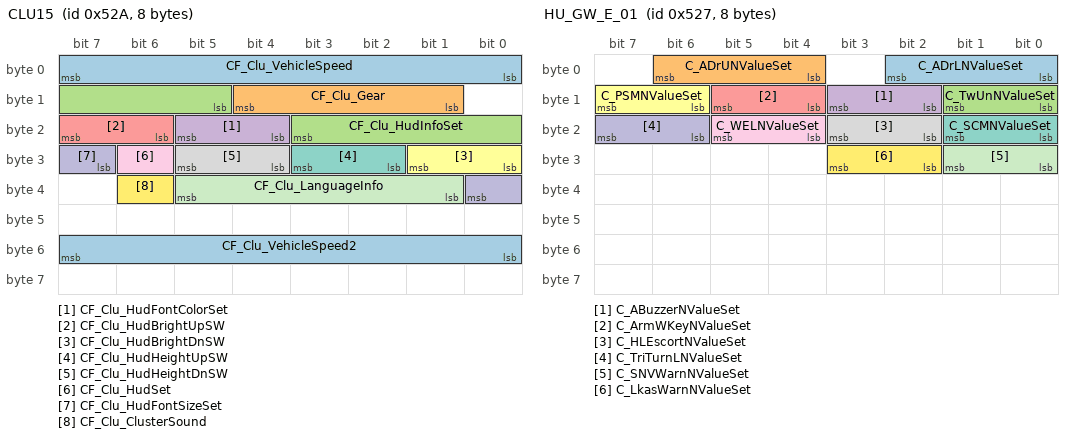
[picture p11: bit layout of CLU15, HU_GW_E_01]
BO_ 1322 CLU15: 8 CLU
 SG_ CF_Clu_VehicleSpeed : 0|8@1+ (1.0,0.0) [0.0|255.0] ""  BCM
 SG_ CF_Clu_Gear : 9|4@1+ (1,0) [0|15] "" BCM
 SG_ CF_Clu_HudInfoSet : 13|7@1+ (1.0,0.0) [0.0|127.0] ""  HUD
 SG_ CF_Clu_HudFontColorSet : 20|2@1+ (1.0,0.0) [0.0|3.0] ""  HUD
 SG_ CF_Clu_HudBrightUpSW : 22|2@1+ (1.0,0.0) [0.0|3.0] ""  HUD
 SG_ CF_Clu_HudBrightDnSW : 24|2@1+ (1.0,0.0) [0.0|3.0] ""  HUD
 SG_ CF_Clu_HudHeightUpSW : 26|2@1+ (1.0,0.0) [0.0|3.0] ""  HUD
 SG_ CF_Clu_HudHeightDnSW : 28|2@1+ (1.0,0.0) [0.0|3.0] ""  HUD
 SG_ CF_Clu_HudSet : 30|1@1+ (1.0,0.0) [0.0|1.0] ""  HUD
 SG_ CF_Clu_HudFontSizeSet : 31|2@1+ (1.0,0.0) [0.0|3.0] ""  HUD
 SG_ CF_Clu_LanguageInfo : 33|5@1+ (1.0,0.0) [0.0|31.0] ""  BCM,PGS
 SG_ CF_Clu_ClusterSound : 38|1@1- (1.0,0.0) [0.0|0.0] ""  BCM,CGW,FATC
 SG_ CF_Clu_VehicleSpeed2 : 48|8@1+ (1,0) [0|255] "" XXX

BO_ 1066 _4WD13: 6 _4WD
 SG_ _4WD_CURRENT : 0|8@1+ (0.390625,0.0) [-50.0|50.0] "A"  TCU
 SG_ _4WD_POSITION : 8|16@1+ (0.015625,0.0) [-180.0|180.0] "Deg"  TCU
 SG_ _4WD_CLU_THERM_STR : 24|8@1+ (1.0,0.0) [0.0|100.0] "%"  TCU
 SG_ _4WD_STATUS : 32|8@1+ (1.0,0.0) [0.0|15.0] ""  ESC,TCU

BO_ 1065 _4WD12: 8 _4WD
 SG_ Ster_Pos : 0|16@1+ (1.0,-600.0) [-600.0|600.0] "Deg"  ESC
 SG_ FRSS : 16|8@1+ (1.0,0.0) [0.0|254.0] "km/h"  ESC
 SG_ FLSS : 24|8@1+ (1.0,0.0) [0.0|254.0] "km/h"  ESC
 SG_ RRSS : 32|8@1+ (1.0,0.0) [0.0|254.0] "km/h"  ESC
 SG_ RLSS : 40|8@1+ (1.0,0.0) [0.0|254.0] "km/h"  ESC
 SG_ CLU_PRES : 48|16@1+ (0.0625,-50.0) [-50.0|50.0] "Bar"  ESC

BO_ 809 EMS12: 8 EMS
 SG_ CONF_TCU m1 : 0|6@1+ (1.0,0.0) [0.0|63.0] ""  _4WD,ACU,BCM,CLU,DATC,EPB,ESC,IBOX,LCA,SMK
 SG_ CAN_VERS m0 : 0|6@1+ (1.0,0.0) [0.0|7.7] ""  _4WD,ABS,ESC,IBOX
 SG_ TQ_STND m3 : 0|6@1+ (10.0,0.0) [0.0|630.0] "Nm"  _4WD,DATC,ECS,EPB,ESC,FATC,IBOX
 SG_ OBD_FRF_ACK m2 : 0|6@1+ (1.0,0.0) [0.0|63.0] ""  _4WD,ESC,IBOX
 SG_ MUL_CODE M : 6|2@1+ (1.0,0.0) [0.0|3.0] ""  _4WD,ABS,ACU,BCM,CLU,DATC,ECS,EPB,ESC,IBOX,LCA,SMK,TCU
 SG_ TEMP_ENG : 8|8@1+ (0.75,-48.0) [-48.0|143.25] "deg"  _4WD,BCM,CLU,DATC,EPB,ESC,IBOX,SMK,TCU
 SG_ MAF_FAC_ALTI_MMV : 16|8@1+ (0.00781,0.0) [0.0|1.99155] ""  IBOX,TCU
 SG_ VB_OFF_ACT : 24|1@1+ (1.0,0.0) [0.0|1.0] ""  IBOX,TCU
 SG_ ACK_ES : 25|1@1+ (1.0,0.0) [0.0|1.0] ""  _4WD,ACU,IBOX
 SG_ CONF_MIL_FMY : 26|3@1+ (1.0,0.0) [0.0|7.0] ""  ESC,IBOX,TCU
 SG_ OD_OFF_REQ : 29|1@1+ (1.0,0.0) [0.0|1.0] ""  IBOX,TCU
 SG_ ACC_ACT : 30|1@1+ (1.0,0.0) [0.0|1.0] ""  _4WD,ABS,CLU,ESC,IAP,IBOX,SCC,TCU
 SG_ CLU_ACK : 31|1@1+ (1.0,0.0) [0.0|1.0] ""  _4WD,EPB,ESC,IBOX
 SG_ BRAKE_ACT : 32|2@1+ (1.0,0.0) [0.0|3.0] ""  _4WD,ABS,ACU,AFLS,CLU,DATC,ECS,EPB,ESC,IBOX,LDWS_LKAS,TCU
 SG_ ENG_CHR : 34|4@1+ (1.0,0.0) [0.0|15.0] ""  _4WD,ABS,ACU,CLU,DATC,EPB,ESC,FATC,IBOX,SCC,SMK,TCU
 SG_ GP_CTL : 38|2@1+ (1.0,0.0) [0.0|3.0] ""  IBOX
 SG_ TPS : 40|8@1+ (0.4694836,-15.0234742) [-15.0234742|104.6948357] "%"  _4WD,ABS,ACU,CLU,DATC,ECS,EPB,ESC,IBOX,TCU
 SG_ PV_AV_CAN : 48|8@1+ (0.3906,0.0) [0.0|99.603] "%"  _4WD,AAF,ABS,ACU,AFLS,CLU,DATC,EPB,ESC,IAP,IBOX,LDWS_LKAS,SCC,TCU
 SG_ ENG_VOL : 56|8@1+ (0.1,0.0) [0.0|25.5] "liter"  _4WD,ABS,ACU,BCM,CLU,DATC,EPB,ESC,IBOX,LDWS_LKAS,SCC,SMK

BO_ 1064 _4WD11: 8 _4WD
 SG_ _4WD_TYPE : 0|2@1+ (1.0,0.0) [0.0|3.0] ""  ACU,ESC,TPMS
 SG_ _4WD_SUPPORT : 2|2@1+ (1.0,0.0) [0.0|3.0] ""  ABS,ESC,TPMS
 SG_ _4WD_ERR : 8|8@1+ (1.0,0.0) [0.0|255.0] ""  CLU,ESC
 SG_ CLU_DUTY : 16|8@1+ (1.0,0.0) [0.0|64.0] "%"  ABS,ESC
 SG_ R_TIRE : 24|8@1+ (1.0,200.0) [200.0|455.0] "mm"  ABS,ESC,TPMS
 SG_ _4WD_SW : 32|8@1+ (1.0,0.0) [0.0|9.9] ""  ESC
 SG_ _2H_ACT : 40|1@1+ (1.0,0.0) [0.0|1.0] ""  ABS,ESC
 SG_ _4H_ACT : 41|1@1+ (1.0,0.0) [0.0|1.0] ""  ABS,CLU,ESC,TPMS
 SG_ LOW_ACT : 42|1@1+ (1.0,0.0) [0.0|1.0] ""  ABS,ESC,TCU,TPMS
 SG_ AUTO_ACT : 43|1@1+ (1.0,0.0) [0.0|1.0] ""  ABS,ESC,TPMS
 SG_ LOCK_ACT : 44|1@1+ (1.0,0.0) [0.0|1.0] ""  ABS,CLU,ESC,TPMS
 SG_ _4WD_TQC_CUR : 48|16@1+ (1.0,0.0) [0.0|65535.0] "Nm"  ABS,ESC

BO_ 1319 HU_GW_E_01: 8 CLU
 SG_ C_ADrLNValueSet : 0|3@1+ (1.0,0.0) [0.0|7.0] ""  BCM
 SG_ C_ADrUNValueSet : 4|3@1+ (1.0,0.0) [0.0|7.0] ""  BCM
 SG_ C_TwUnNValueSet : 8|2@1+ (1.0,0.0) [0.0|3.0] ""  BCM
 SG_ C_ABuzzerNValueSet : 10|2@1+ (1.0,0.0) [0.0|3.0] ""  BCM
 SG_ C_ArmWKeyNValueSet : 12|2@1+ (1.0,0.0) [0.0|3.0] ""  BCM
 SG_ C_PSMNValueSet : 14|2@1+ (1.0,0.0) [0.0|3.0] ""  BCM
 SG_ C_SCMNValueSet : 16|2@1+ (1.0,0.0) [0.0|3.0] ""  BCM
 SG_ C_HLEscortNValueSet : 18|2@1+ (1.0,0.0) [0.0|3.0] ""  BCM
 SG_ C_WELNValueSet : 20|2@1+ (1.0,0.0) [0.0|3.0] ""  BCM
 SG_ C_TriTurnLNValueSet : 22|2@1+ (1.0,0.0) [0.0|3.0] ""  BCM
 SG_ C_SNVWarnNValueSet : 24|2@1+ (1.0,0.0) [0.0|3.0] ""  BCM
 SG_ C_LkasWarnNValueSet : 26|2@1+ (1.0,0.0) [0.0|3.0] ""  BCM

BS_:

BU_: XXX CAMERA FRONT_RADAR ADRV APRK

BS_:

BU_: IAP ODS _4WD BCM HUD DATC MDPS AAF_Tester AEMC SMK _4WD EPB CUBIS MTS TMU EVP CGW TPMS LPI DI_BOX SPAS EMS LCA TCU IBOX FATC AFLS FPCM SCC AHLS AVM ABS SNV OPI PGS SAS AAF Dummy LDWS_LKAS LVR ESC PSB CLU ECS ACU REA

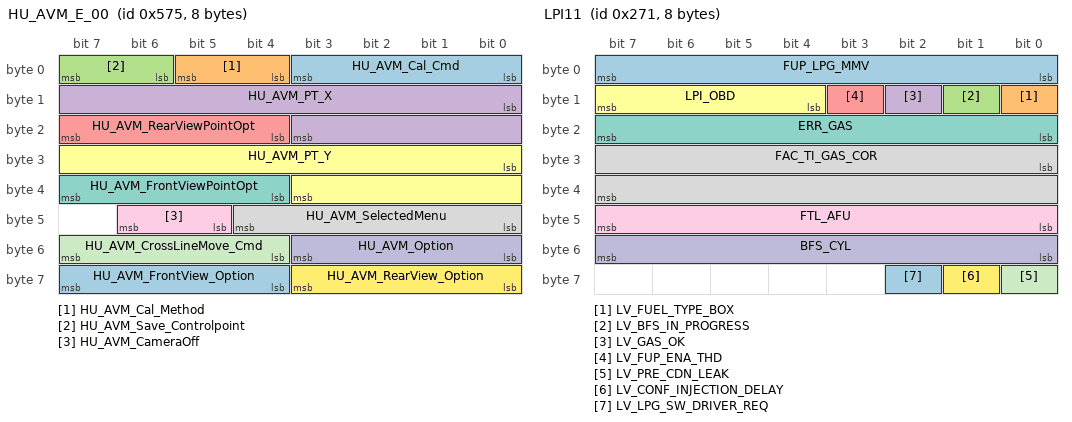
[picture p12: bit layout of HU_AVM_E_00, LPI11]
BO_ 1397 HU_AVM_E_00: 8 CLU
 SG_ HU_AVM_Cal_Cmd : 0|4@1+ (1.0,0.0) [0.0|15.0] ""  AVM,PGS
 SG_ HU_AVM_Cal_Method : 4|2@1+ (1.0,0.0) [0.0|3.0] ""  AVM,PGS
 SG_ HU_AVM_Save_Controlpoint : 6|2@1+ (1.0,0.0) [0.0|3.0] ""  AVM,PGS
 SG_ HU_AVM_PT_X : 8|12@1+ (1.0,0.0) [0.0|15.0] ""  AVM,PGS
 SG_ HU_AVM_RearViewPointOpt : 20|4@1+ (1.0,0.0) [0.0|15.0] ""  AVM,PGS
 SG_ HU_AVM_PT_Y : 24|12@1+ (1.0,0.0) [0.0|4095.0] ""  AVM,PGS
 SG_ HU_AVM_FrontViewPointOpt : 36|4@1+ (1.0,0.0) [0.0|15.0] ""  AVM,PGS
 SG_ HU_AVM_SelectedMenu : 40|5@1+ (1.0,0.0) [0.0|31.0] ""  AVM,PGS
 SG_ HU_AVM_CameraOff : 45|2@1+ (1.0,0.0) [0.0|3.0] ""  AVM,PGS
 SG_ HU_AVM_Option : 48|4@1+ (1.0,0.0) [0.0|15.0] ""  AVM,PGS
 SG_ HU_AVM_CrossLineMove_Cmd : 52|4@1+ (1.0,0.0) [0.0|15.0] ""  AVM,PGS
 SG_ HU_AVM_RearView_Option : 56|4@1+ (1.0,0.0) [0.0|15.0] ""  AVM,PGS
 SG_ HU_AVM_FrontView_Option : 60|4@1+ (1.0,0.0) [0.0|15.0] ""  AVM,PGS

BO_ 1395 HU_AVM_E_01: 8 CLU
 SG_ HU_PGSSelectedMenu : 0|4@1+ (1.0,0.0) [0.0|15.0] ""  AVM,PGS
 SG_ HU_PGSOption : 8|5@1+ (1.0,0.0) [0.0|31.0] ""  AVM,PGS
 SG_ HU_AVM_ParkingAssistMenu : 56|4@1+ (1.0,0.0) [0.0|15.0] ""  AVM,PGS
 SG_ HU_AVM_ParkingAssistSB : 60|4@1+ (1.0,0.0) [0.0|15.0] ""  AVM,PGS

BO_ 1393 OPI11: 5 OPI
 SG_ CR_Opi_Spd_Rpm : 0|8@1+ (20.0,0.0) [0.0|3500.0] "rpm"  TCU
 SG_ CF_Opi_Over_Temp : 8|1@1+ (1.0,0.0) [0.0|1.0] ""  TCU
 SG_ CF_Opi_Over_Cur : 9|1@1+ (1.0,0.0) [0.0|1.0] ""  EMS,TCU
 SG_ CF_Opi_Over_Vol : 10|1@1+ (1.0,0.0) [0.0|1.0] ""  TCU
 SG_ CF_Opi_Hall_Fail : 11|1@1+ (1.0,0.0) [0.0|1.0] ""  EMS,TCU
 SG_ CF_Opi_Flt : 12|1@1+ (1.0,0.0) [0.0|1.0] ""  EMS,TCU
 SG_ CF_Opi_Motor_Dir : 15|1@1+ (1.0,0.0) [0.0|1.0] ""  TCU
 SG_ CF_Opi_Romver : 16|8@1+ (1.0,0.0) [0.0|255.0] ""  TCU
 SG_ CF_Opi_PWM_Rate : 24|12@1+ (1.0,0.0) [0.0|100.0] "%"  TCU

BO_ 625 LPI11: 8 LPI
 SG_ FUP_LPG_MMV : 0|8@1+ (128.0,0.0) [0.0|32640.0] "hPa"  EMS
 SG_ LV_FUEL_TYPE_BOX : 8|1@1+ (1.0,0.0) [0.0|1.0] ""  EMS
 SG_ LV_BFS_IN_PROGRESS : 9|1@1+ (1.0,0.0) [0.0|1.0] ""  EMS
 SG_ LV_GAS_OK : 10|1@1+ (1.0,0.0) [0.0|1.0] ""  EMS
 SG_ LV_FUP_ENA_THD : 11|1@1+ (1.0,0.0) [0.0|1.0] ""  BCM,CLU,EMS,SMK
 SG_ LPI_OBD : 12|4@1+ (1.0,0.0) [0.0|15.0] ""  EMS
 SG_ ERR_GAS : 16|8@1+ (1.0,0.0) [0.0|255.0] ""  EMS
 SG_ FAC_TI_GAS_COR : 24|16@1+ (3.05E-5,0.0) [0.0|1.9988175] ""  EMS
 SG_ FTL_AFU : 40|8@1+ (0.392,0.0) [0.0|99.96] "%"  EMS
 SG_ BFS_CYL : 48|8@1+ (1.0,0.0) [0.0|6.0] "Cyl Nr."  EMS
 SG_ LV_PRE_CDN_LEAK : 56|1@1+ (1.0,0.0) [0.0|1.0] ""  EMS
 SG_ LV_CONF_INJECTION_DELAY : 57|1@1+ (1.0,0.0) [0.0|1.0] ""  EMS
 SG_ LV_LPG_SW_DRIVER_REQ : 58|1@1+ (1.0,0.0) [0.0|1.0] ""  EMS

BO_ 356 VSM11: 4 ESC
 SG_ CR_Esc_StrTqReq : 0|12@1+ (0.01,-20.48) [-20.48|20.47] "Nm"  MDPS
 SG_ CF_Esc_Act : 12|1@1+ (1.0,0.0) [0.0|1.0] ""  LDWS_LKAS,MDPS
 SG_ CF_Esc_CtrMode : 13|3@1+ (1.0,0.0) [0.0|7.0] ""  MDPS
 SG_ CF_Esc_Def : 16|1@1+ (1.0,0.0) [0.0|1.0] ""  MDPS
 SG_ CF_Esc_AliveCnt : 17|4@1+ (1.0,0.0) [0.0|15.0] ""  LDWS_LKAS,MDPS
 SG_ CF_Esc_Chksum : 24|8@1+ (1.0,0.0) [0.0|255.0] ""  LDWS_LKAS,MDPS

BO_ 1379 PGS_HU_PE_01: 8 PGS
 SG_ PGS_State : 0|4@1+ (1.0,0.0) [0.0|15.0] ""  CLU
 SG_ PGS_ParkGuideState : 8|5@1+ (1.0,0.0) [0.0|31.0] ""  CLU
 SG_ PGS_Option : 16|5@1+ (1.0,0.0) [0.0|31.0] ""  CLU
 SG_ PGS_Version : 32|16@1+ (1.0,0.0) [0.0|65535.0] ""  CLU

BO_ 1378 HUD11: 4 HUD
 SG_ CF_Hud_HeightStaus : 0|5@1+ (1.0,0.0) [0.0|31.0] ""  CLU
 SG_ CF_Hud_PBackStatus : 6|2@1+ (1.0,0.0) [0.0|0.0] ""  BCM,CLU
 SG_ CF_Hud_Brightness : 8|5@1+ (1.0,0.0) [0.0|31.0] ""  CLU

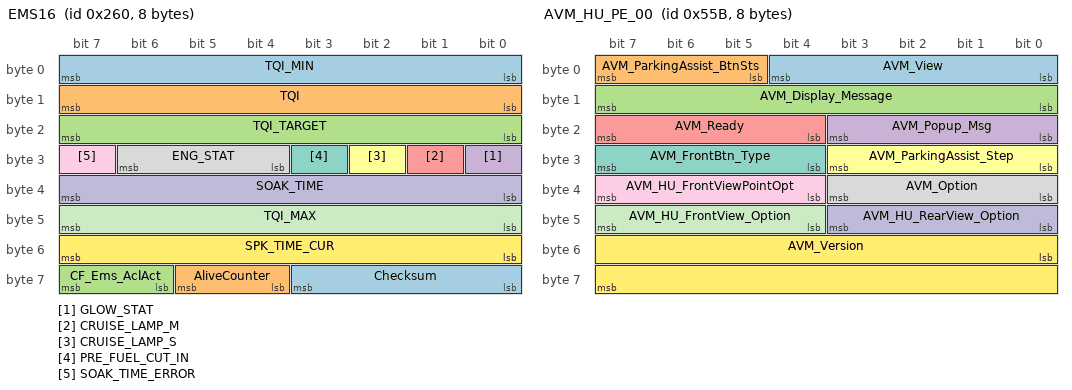
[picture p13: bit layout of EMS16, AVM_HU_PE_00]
BO_ 608 EMS16: 8 EMS
 SG_ TQI_MIN : 0|8@1+ (0.390625,0.0) [0.0|99.609375] "%"  ESC,IBOX,TCU
 SG_ TQI : 8|8@1+ (0.390625,0.0) [0.0|99.609375] "%"  ESC,IBOX,TCU
 SG_ TQI_TARGET : 16|8@1+ (0.390625,0.0) [0.0|99.609375] "%"  EPB,ESC,IBOX,TCU
 SG_ GLOW_STAT : 24|1@1+ (1.0,0.0) [0.0|1.0] ""  BCM,CLU,IBOX,SMK
 SG_ CRUISE_LAMP_M : 25|1@1+ (1.0,0.0) [0.0|1.0] ""  CLU,IBOX,TCU
 SG_ CRUISE_LAMP_S : 26|1@1+ (1.0,0.0) [0.0|1.0] ""  CLU,IBOX,TCU
 SG_ PRE_FUEL_CUT_IN : 27|1@1+ (1.0,0.0) [0.0|1.0] ""  IBOX,TCU
 SG_ ENG_STAT : 28|3@1+ (1.0,0.0) [0.0|7.0] ""  ABS,AHLS,AVM,BCM,CLU,EPB,ESC,EVP,FPCM,IBOX,LCA,LDWS_LKAS,MDPS,SCC,SMK,TCU
 SG_ SOAK_TIME_ERROR : 31|1@1+ (1.0,0.0) [0.0|1.0] ""  DATC,EPB,IBOX,TCU
 SG_ SOAK_TIME : 32|8@1+ (1.0,0.0) [0.0|255.0] "Min"  _4WD,DATC,EPB,IBOX,TCU
 SG_ TQI_MAX : 40|8@1+ (0.390625,0.0) [0.0|99.609375] "%"  ESC,IBOX,TCU
 SG_ SPK_TIME_CUR : 48|8@1+ (0.375,-35.625) [-35.625|60.0] ""  IBOX,TCU
 SG_ Checksum : 56|4@1+ (1.0,0.0) [0.0|15.0] ""  ECS,IBOX,LDWS_LKAS,MDPS,SCC
 SG_ AliveCounter : 60|2@1+ (1.0,0.0) [0.0|3.0] ""  IBOX,LDWS_LKAS,MDPS,SCC
 SG_ CF_Ems_AclAct : 62|2@1+ (1.0,0.0) [0.0|3.0] ""  IBOX,SCC

BO_ 1371 AVM_HU_PE_00: 8 AVM
 SG_ AVM_View : 0|5@1+ (1.0,0.0) [0.0|31.0] ""  CLU
 SG_ AVM_ParkingAssist_BtnSts : 5|3@1+ (1.0,0.0) [0.0|7.0] ""  CLU
 SG_ AVM_Display_Message : 8|8@1+ (1.0,0.0) [0.0|255.0] ""  CLU
 SG_ AVM_Popup_Msg : 16|4@1+ (1.0,0.0) [0.0|15.0] ""  CLU
 SG_ AVM_Ready : 20|4@1+ (1.0,0.0) [0.0|15.0] ""  CLU
 SG_ AVM_ParkingAssist_Step : 24|4@1+ (1.0,0.0) [0.0|15.0] ""  CLU
 SG_ AVM_FrontBtn_Type : 28|4@1+ (1.0,0.0) [0.0|15.0] ""  CLU
 SG_ AVM_Option : 32|4@1+ (1.0,0.0) [0.0|15.0] ""  CLU
 SG_ AVM_HU_FrontViewPointOpt : 36|4@1+ (1.0,0.0) [0.0|15.0] ""  CLU
 SG_ AVM_HU_RearView_Option : 40|4@1+ (1.0,0.0) [0.0|15.0] ""  CLU
 SG_ AVM_HU_FrontView_Option : 44|4@1+ (1.0,0.0) [0.0|15.0] ""  CLU
 SG_ AVM_Version : 48|16@1+ (1.0,0.0) [0.0|65535.0] ""  CLU

BO_ 1370 HU_AVM_PE_00: 8 CLU
 SG_ HU_AVM_Status : 0|2@1+ (1.0,0.0) [0.0|3.0] ""  AVM,PGS

BO_ 1369 CGW4: 8 BCM
 SG_ CF_Gway_MemoryP1Cmd : 0|1@1+ (1.0,0.0) [0.0|1.0] ""  CLU
 SG_ CF_Gway_MemoryP2Cmd : 1|1@1+ (1.0,0.0) [0.0|1.0] ""  CLU
 SG_ CF_Gway_PBackP1Cmd : 2|1@1+ (1.0,0.0) [0.0|1.0] ""  CLU
 SG_ CF_Gway_PBackP2Cmd : 3|1@1+ (1.0,0.0) [0.0|1.0] ""  CLU
 SG_ CF_Gway_StrgWhlHeatedState : 4|1@1+ (1.0,0.0) [0.0|1.0] ""  CLU
 SG_ CF_Gway_PBackStopCmd : 5|1@1+ (1.0,0.0) [0.0|1.0] ""  CLU,HUD
 SG_ CF_Gway_StaticBendLhAct : 6|1@1+ (1.0,0.0) [0.0|1.0] ""  CLU
 SG_ CF_Gway_StaticBendRhAct : 7|1@1+ (1.0,0.0) [0.0|1.0] ""  CLU
 SG_ CF_Gway_DrvWdwStat : 8|1@1+ (1.0,0.0) [0.0|1.0] ""  CLU
 SG_ CF_Gway_RLWdwState : 9|1@1+ (1.0,0.0) [0.0|1.0] ""  CLU
 SG_ CF_Gway_RRWdwState : 10|1@1+ (1.0,0.0) [0.0|1.0] ""  CLU
 SG_ CF_Gway_AstWdwStat : 11|1@1+ (1.0,0.0) [0.0|1.0] ""  CLU
 SG_ CF_Gway_MemoryEnable : 12|1@1+ (1.0,0.0) [0.0|1.0] ""  CLU
 SG_ CF_Gway_PBACKStopCmd : 13|1@1+ (1.0,0.0) [0.0|1.0] ""  CLU
 SG_ CF_Gway_PBACKStop : 14|1@1+ (1.0,0.0) [0.0|1.0] ""  CLU,HUD
 SG_ CF_Gway_IMSBuzzer : 15|1@1+ (1.0,0.0) [0.0|1.0] ""  CLU
 SG_ CF_Gway_DrvSeatBeltInd : 36|2@1+ (1.0,0.0) [0.0|3.0] ""  CLU,Dummy
 SG_ CF_Gway_AstSeatBeltInd : 38|2@1+ (1.0,0.0) [0.0|3.0] ""  CLU
 SG_ CF_Gway_RCSeatBeltInd : 40|2@1+ (1.0,0.0) [0.0|3.0] ""  CLU
 SG_ CF_Gway_RLSeatBeltInd : 42|2@1+ (1.0,0.0) [0.0|3.0] ""  CLU
 SG_ CF_Gway_RRSeatBeltInd : 44|2@1+ (1.0,0.0) [0.0|3.0] ""  CLU
 SG_ CF_Gway_RrWiperHighSw : 46|1@1+ (1.0,0.0) [0.0|1.0] ""  CLU
 SG_ CF_Gway_RrWiperLowSw : 47|1@1+ (1.0,0.0) [0.0|1.0] ""  CLU

BO_ 1367 EngFrzFrm12: 8 EMS
 SG_ PID_06h : 0|8@1+ (0.78125,-100.0) [-100.0|99.22] "%"  AAF,IBOX,TCU
 SG_ PID_07h : 8|8@1+ (0.78125,-100.0) [-100.0|99.22] "%"  AAF,IBOX,TCU
 SG_ PID_08h : 16|8@1+ (0.78125,-100.0) [-100.0|99.22] "%"  AAF,IBOX,TCU
 SG_ PID_09h : 24|8@1+ (0.78125,-100.0) [-100.0|99.22] "%"  AAF,IBOX,TCU
 SG_ PID_0Bh : 32|8@1+ (1.0,0.0) [0.0|255.0] "kPa"  AAF,IBOX,TCU
 SG_ PID_23h : 40|16@1+ (10.0,0.0) [0.0|655350.0] "kPa"  AAF,IBOX,TCU

BO_ 1366 EngFrzFrm11: 8 EMS
 SG_ PID_04h : 0|8@1+ (0.3921568627,0.0) [0.0|100.0] "%"  AAF,TCU
 SG_ PID_05h : 8|8@1+ (1.0,-40.0) [-40.0|215.0] "deg"  AAF,TCU
 SG_ PID_0Ch : 16|16@1+ (0.25,0.0) [0.0|16383.75] "rpm"  AAF,TCU
 SG_ PID_0Dh : 32|8@1+ (1.0,0.0) [0.0|255.0] "km/h"  AAF,TCU
 SG_ PID_11h : 40|8@1+ (0.3921568627,0.0) [0.0|100.0] "%"  AAF,TCU
 SG_ PID_03h : 48|16@1+ (1.0,0.0) [0.0|65535.0] ""  AAF,TCU

BO_ 1365 FPCM11: 8 FPCM
 SG_ CR_Fpcm_LPActPre : 0|8@1+ (3.137254902,0.0) [0.0|800.0] "kPa"  EMS
 SG_ CF_Fpcm_LPPumpOverCur : 8|1@1+ (1.0,0.0) [0.0|1.0] ""  EMS
 SG_ CF_Fpcm_PreSnrHi : 9|1@1+ (1.0,0.0) [0.0|1.0] ""  EMS
 SG_ CF_Fpcm_PreSnrDisc : 10|1@1+ (1.0,0.0) [0.0|1.0] ""  EMS
 SG_ CF_Fpcm_PreSnrShort : 11|1@1+ (1.0,0.0) [0.0|1.0] ""  EMS
 SG_ CF_Fpcm_LPPumpDiscShort : 12|1@1+ (1.0,0.0) [0.0|1.0] ""  EMS
 SG_ CF_Fpcm_LP_System_Error : 13|1@1+ (1.0,0.0) [0.0|1.0] ""  EMS
 SG_ CF_Fpcm_PreSnrSigErr : 14|1@1+ (1.0,0.0) [0.0|1.0] ""  EMS
 SG_ CF_Fpcm_LPCtrCirFlt : 15|1@1+ (1.0,0.0) [0.0|1.0] ""  EMS

BO_ 871 LVR12: 8 LVR
 SG_ CF_Lvr_CruiseSet : 0|8@1+ (1.0,0.0) [0.0|255.0] "" CLU,TCU
 SG_ CF_Lvr_IsgState : 8|2@1+ (1.0,0.0) [0.0|3.0] "" CLU,TCU
 SG_ CF_Lvr_Gear : 32|4@1+ (1.0,0.0) [0.0|15.0] ""  CLU,TCU

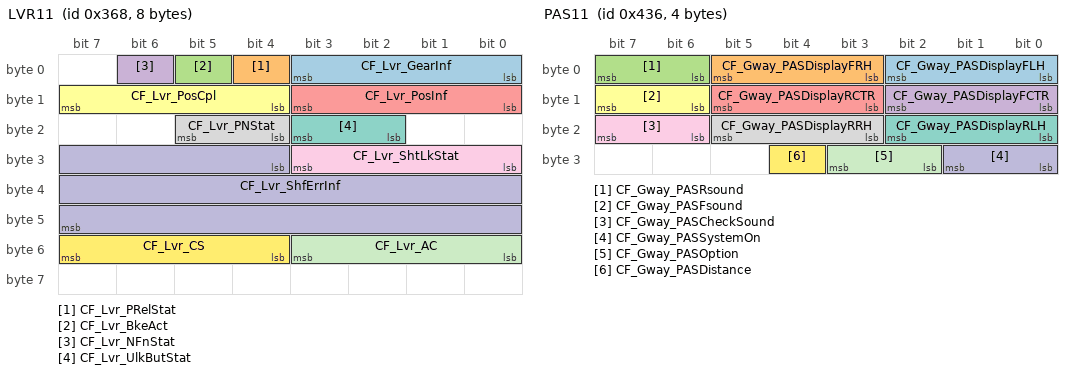
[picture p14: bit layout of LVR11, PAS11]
BO_ 872 LVR11: 8 LVR
 SG_ CF_Lvr_GearInf : 0|4@1+ (1.0,0.0) [0.0|15.0] ""  CLU,TCU
 SG_ CF_Lvr_PRelStat : 4|1@1+ (1.0,0.0) [0.0|1.0] ""  BCM,CLU,SMK,TCU
 SG_ CF_Lvr_BkeAct : 5|1@1+ (1.0,0.0) [0.0|1.0] ""  TCU
 SG_ CF_Lvr_NFnStat : 6|1@1+ (1.0,0.0) [0.0|1.0] ""  CLU
 SG_ CF_Lvr_PosInf : 8|4@1+ (1.0,0.0) [0.0|15.0] ""  TCU
 SG_ CF_Lvr_PosCpl : 12|4@1+ (1.0,0.0) [0.0|15.0] ""  TCU
 SG_ CF_Lvr_UlkButStat : 18|2@1+ (1.0,0.0) [0.0|3.0] ""  TCU
 SG_ CF_Lvr_PNStat : 20|2@1+ (1.0,0.0) [0.0|3.0] ""  CLU
 SG_ CF_Lvr_ShtLkStat : 24|4@1+ (1.0,0.0) [0.0|15.0] ""  TCU
 SG_ CF_Lvr_ShfErrInf : 28|20@1+ (1.0,0.0) [0.0|8191.0] ""  CLU,TCU
 SG_ CF_Lvr_AC : 48|4@1+ (1.0,0.0) [0.0|15.0] ""  TCU
 SG_ CF_Lvr_CS : 52|4@1+ (1.0,0.0) [0.0|15.0] ""  TCU

BO_ 1363 CGW2: 8 BCM
 SG_ CF_Gway_GwayDiagState : 0|1@1+ (1.0,0.0) [0.0|3.0] ""  CLU,Dummy
 SG_ CF_Gway_DDMDiagState : 1|1@1+ (1.0,0.0) [0.0|1.0] ""  CLU,Dummy
 SG_ CF_Gway_SCMDiagState : 2|1@1+ (1.0,0.0) [0.0|1.0] ""  CLU,Dummy
 SG_ CF_Gway_PSMDiagState : 3|1@1+ (1.0,0.0) [0.0|1.0] ""  CLU,Dummy
 SG_ CF_Gway_SJBDiagState : 4|1@1+ (1.0,0.0) [0.0|1.0] ""  CLU,Dummy
 SG_ CF_Gway_IPMDiagState : 5|1@1+ (1.0,0.0) [0.0|1.0] ""  CLU,Dummy
 SG_ CF_Gway_LDMFail : 6|2@1+ (1.0,0.0) [0.0|3.0] ""  CLU,LDWS_LKAS,LDWS_LKAS
 SG_ CF_Gway_CLUSwGuiCtrl : 10|3@1+ (1.0,0.0) [0.0|63.0] ""  CLU,Dummy
 SG_ CF_Gway_CLUSwGroup : 13|1@1+ (1.0,0.0) [0.0|1.0] ""  CLU,Dummy
 SG_ CF_Gway_CLUSwMode : 14|1@1+ (1.0,0.0) [0.0|1.0] ""  CLU,Dummy
 SG_ CF_Gway_CLUSwEnter : 15|1@1+ (1.0,0.0) [0.0|1.0] ""  CLU,Dummy
 SG_ CF_Gway_AutoLightValue : 16|1@1+ (1.0,0.0) [0.0|1.0] ""  LCA,LCA
 SG_ CF_Gway_BrakeFluidSw : 17|1@1+ (1.0,0.0) [0.0|1.0] ""  CLU,Dummy
 SG_ CF_Gway_DrvSeatBeltInd : 18|2@1+ (1.0,0.0) [0.0|3.0] ""  CLU
 SG_ CF_Gway_AvTail : 20|1@1+ (1.0,0.0) [0.0|3.0] ""  CLU,SNV,SNV
 SG_ CF_Gway_RearFogAct : 21|1@1+ (1.0,0.0) [0.0|1.0] ""  CLU,Dummy
 SG_ CF_Gway_ExtTailAct : 22|1@1+ (1.0,0.0) [0.0|1.0] ""  AVM,CLU,LCA,PGS,SPAS,AVM,LCA,PGS,SPAS
 SG_ CF_Gway_RRDrSw : 23|1@1+ (1.0,0.0) [0.0|1.0] ""  CLU,Dummy
 SG_ CF_Gway_RLDrSw : 24|1@1+ (1.0,0.0) [0.0|1.0] ""  CLU,Dummy
 SG_ CF_Gway_IntTailAct : 25|1@1+ (1.0,0.0) [0.0|1.0] ""  CLU,Dummy
 SG_ CF_Gway_CountryCfg : 26|3@1+ (1.0,0.0) [0.0|7.0] ""  AVM,CLU,PGS,Dummy
 SG_ CF_Gway_WiperParkPosition : 32|1@1+ (1.0,0.0) [0.0|1.0] ""  AFLS,EMS,LDWS_LKAS,AFLS,EMS,LDWS_LKAS
 SG_ CF_Gway_HLLowLHFail : 33|1@1+ (1.0,0.0) [0.0|1.0] ""  LDWS_LKAS,SNV,LDWS_LKAS,SNV
 SG_ CF_Gway_HLLowRHFail : 34|1@1+ (1.0,0.0) [0.0|1.0] ""  LDWS_LKAS,SNV,LDWS_LKAS,SNV
 SG_ CF_Gway_ESCLFailWarn : 35|1@1+ (1.0,0.0) [0.0|1.0] ""  CLU,Dummy
 SG_ CF_Gway_ESCLNotLockedWarn : 36|1@1+ (1.0,0.0) [0.0|1.0] ""  CLU,Dummy
 SG_ CF_Gway_ESCLNotUnlockWarn : 37|1@1+ (1.0,0.0) [0.0|1.0] ""  CLU,Dummy
 SG_ CF_Gway_IDoutWarn : 38|1@1+ (1.0,0.0) [0.0|1.0] ""  CLU,Dummy
 SG_ CF_Gway_ImmoLp : 40|1@1+ (1.0,0.0) [0.0|3.0] ""  CLU,Dummy
 SG_ CF_Gway_BCMRKEID : 41|3@1+ (1.0,0.0) [0.0|7.0] ""  CLU,Dummy
 SG_ CF_Gway_VehicleNotPWarn : 44|1@1+ (1.0,0.0) [0.0|1.0] ""  CLU,Dummy
 SG_ CF_Gway_DeactivationWarn : 45|1@1+ (1.0,0.0) [0.0|1.0] ""  CLU,Dummy
 SG_ CF_Gway_KeyBATDischargeWarn : 46|1@1+ (1.0,0.0) [0.0|1.0] ""  CLU,Dummy
 SG_ CF_Gway_SSBWarn : 47|1@1+ (1.0,0.0) [0.0|1.0] ""  CLU,Dummy
 SG_ CF_Gway_SMKFobID : 48|3@1+ (1.0,0.0) [0.0|7.0] ""  CLU,Dummy
 SG_ CF_Gway_SMKRKECmd : 51|3@1+ (1.0,0.0) [0.0|7.0] ""  CLU,Dummy
 SG_ CF_Gway_AutoLightOption : 54|1@1+ (1.0,0.0) [0.0|1.0] ""  CLU
 SG_ CF_Gway_SJBDeliveryMode : 55|1@1+ (1.0,0.0) [0.0|1.0] ""  CLU,Dummy
 SG_ CF_Gway_KeyoutLp : 56|1@1+ (1.0,0.0) [0.0|1.0] ""  CLU,Dummy
 SG_ CF_Gway_SMKDispWarn : 57|4@1+ (1.0,0.0) [0.0|15.0] ""  CLU,Dummy
 SG_ CF_Gway_WngBuz : 61|3@1+ (1.0,0.0) [0.0|7.0] ""  CLU,Dummy

BO_ 339 TCS11: 8 ESC
 SG_ TCS_REQ : 0|1@1+ (1.0,0.0) [0.0|1.0] ""  _4WD,EMS,EPB,TCU
 SG_ MSR_C_REQ : 1|1@1+ (1.0,0.0) [0.0|1.0] ""  EMS,EPB,SCC,TCU
 SG_ TCS_PAS : 2|1@1+ (1.0,0.0) [0.0|1.0] ""  _4WD,CLU,EMS,SCC,SPAS,TCU
 SG_ TCS_GSC : 3|1@1+ (1.0,0.0) [0.0|1.0] ""  _4WD,EMS,TCU
 SG_ CF_Esc_LimoInfo : 4|2@1+ (1.0,0.0) [0.0|3.0] ""  _4WD,SCC
 SG_ ABS_DIAG : 6|1@1+ (1.0,0.0) [0.0|1.0] ""  _4WD,CLU,EMS,EPB
 SG_ ABS_DEF : 7|1@1+ (1.0,0.0) [0.0|1.0] ""  _4WD,ACU,ECS,EMS,EPB,SCC,SPAS,TCU
 SG_ TCS_DEF : 8|1@1+ (1.0,0.0) [0.0|1.0] ""  _4WD,EMS,EPB,SCC,SPAS,TCU
 SG_ TCS_CTL : 9|1@1+ (1.0,0.0) [0.0|1.0] ""  _4WD,EMS,EPB,SCC,SPAS,TCU
 SG_ ABS_ACT : 10|1@1+ (1.0,0.0) [0.0|1.0] ""  _4WD,ACU,ECS,EMS,EPB,LDWS_LKAS,SCC,SPAS,TCU
 SG_ EBD_DEF : 11|1@1+ (1.0,0.0) [0.0|1.0] ""  _4WD,EMS,EPB,SPAS,TCU
 SG_ ESP_PAS : 12|1@1+ (1.0,0.0) [0.0|1.0] ""  _4WD,ACU,CLU,EMS,EPB,LDWS_LKAS,SCC,TCU
 SG_ ESP_DEF : 13|1@1+ (1.0,0.0) [0.0|1.0] ""  _4WD,ACU,ECS,EMS,EPB,LDWS_LKAS,SCC,TCU
 SG_ ESP_CTL : 14|1@1+ (1.0,0.0) [0.0|1.0] ""  _4WD,ACU,ECS,EMS,EPB,LDWS_LKAS,SCC,SPAS,TCU
 SG_ TCS_MFRN : 15|1@1+ (1.0,0.0) [0.0|1.0] ""  EMS,EPB,TCU
 SG_ DBC_CTL : 16|1@1+ (1.0,0.0) [0.0|1.0] ""  _4WD,EMS,EPB
 SG_ DBC_PAS : 17|1@1+ (1.0,0.0) [0.0|1.0] ""  _4WD,EMS,EPB
 SG_ DBC_DEF : 18|1@1+ (1.0,0.0) [0.0|1.0] ""  _4WD,EMS,EPB
 SG_ HAC_CTL : 19|1@1+ (1.0,0.0) [0.0|1.0] ""  _4WD,CLU,EMS,EPB,TCU
 SG_ HAC_PAS : 20|1@1+ (1.0,0.0) [0.0|1.0] ""  _4WD,CLU,EMS,EPB,TCU
 SG_ HAC_DEF : 21|1@1+ (1.0,0.0) [0.0|1.0] ""  _4WD,CLU,EMS,EPB,TCU
 SG_ ESS_STAT : 22|2@1+ (1.0,0.0) [0.0|3.0] ""  _4WD,BCM,CLU,EMS,EPB
 SG_ TQI_TCS : 24|8@1+ (0.390625,0.0) [0.0|99.609375] "%"  EMS,EPB,TCU
 SG_ TQI_MSR : 32|8@1+ (0.390625,0.0) [0.0|99.609375] "%"  EMS,EPB,TCU
 SG_ TQI_SLW_TCS : 40|8@1+ (0.390625,0.0) [0.0|99.609375] "%"  EMS,EPB,TCU
 SG_ CF_Esc_BrkCtl : 48|1@1+ (1.0,0.0) [0.0|1.0] ""  EMS
 SG_ BLA_CTL : 49|2@1+ (1.0,0.0) [0.0|3.0] ""  BCM,CGW,CLU
 SG_ AliveCounter_TCS1 : 52|4@1+ (1.0,0.0) [0.0|14.0] ""  EMS,EPB,LDWS_LKAS
 SG_ CheckSum_TCS1 : 56|8@1+ (1.0,0.0) [0.0|255.0] ""  EMS,EPB,LDWS_LKAS

BO_ 1362 SNV11: 4 SNV
 SG_ CF_SNV_DisplayControl : 0|2@1+ (1.0,0.0) [0.0|3.0] ""  CLU,HUD
 SG_ CF_Snv_BeepWarning : 2|2@1+ (1.0,0.0) [0.0|3.0] ""  CLU,HUD
 SG_ CF_Snv_WarningMessage : 4|3@1+ (1.0,0.0) [0.0|7.0] ""  CLU,HUD
 SG_ CF_Snv_DetectionEnable : 7|1@1+ (1.0,0.0) [0.0|1.0] ""  BCM,CLU,HUD
 SG_ CF_Snv_PedestrianDetect : 8|2@1+ (1.0,0.0) [0.0|3.0] ""  BCM,CLU,HUD
 SG_ CF_Snv_IRLampControl : 10|2@1+ (1.0,0.0) [0.0|3.0] ""  BCM,CLU,HUD

BO_ 1360 IAP11: 3 IAP
 SG_ CF_Iap_EcoPmodSwi : 0|1@1+ (1.0,0.0) [0.0|1.0] ""  CLU
 SG_ CF_Iap_EcoPmodAct : 1|1@1+ (1.0,0.0) [0.0|1.0] ""  CLU
 SG_ CF_Iap_ReqWarn : 2|2@1+ (1.0,0.0) [0.0|3.0] ""  CLU

BO_ 1356 TCU_DCT14: 8 TCU
 SG_ Vehicle_Stop_Time : 0|5@1+ (1.0,0.0) [0.0|0.0] ""  CLU
 SG_ HILL_HOLD_WARNING : 5|1@1+ (1.0,0.0) [0.0|0.0] ""  CLU

BO_ 1353 BAT11: 8 EMS
 SG_ BAT_SNSR_I : 0|16@1+ (0.01,-327.0) [-327.0|328.0] "A"  CGW,CUBIS,IBOX,TMU
 SG_ BAT_SOC : 16|8@1+ (1.0,0.0) [0.0|100.0] "%"  CGW,CUBIS,IBOX,TMU
 SG_ BAT_SNSR_V : 24|14@1+ (0.0010,6.0) [6.0|18.0] "V"  CGW,CUBIS,IBOX,TMU
 SG_ BAT_SNSR_Temp : 38|9@1- (0.5,-40.0) [-40.0|125.0] "deg"  CGW,CUBIS,IBOX,TMU
 SG_ BAT_SNSR_State : 47|1@1+ (1.0,0.0) [0.0|1.0] ""  CGW,CUBIS,IBOX,TMU
 SG_ BAT_SOH : 48|7@1+ (1.0,0.0) [0.0|100.0] "%"  CGW,CUBIS,IBOX,TMU
 SG_ BAT_SNSR_Invalid : 55|1@1+ (1.0,0.0) [0.0|1.0] ""  CGW,CUBIS,IBOX,TMU
 SG_ BAT_SOF : 56|7@1+ (0.1,0.0) [0.0|12.0] "V"  CGW,CUBIS,IBOX,TMU
 SG_ BAT_SNSR_Error : 63|1@1+ (1.0,0.0) [0.0|1.0] ""  CGW,CUBIS,IBOX,TMU

BO_ 1351 EMS15: 8 EMS
 SG_ ECGPOvrd : 0|1@1+ (1.0,0.0) [0.0|1.0] ""  ESC,IBOX,SCC
 SG_ QECACC : 1|1@1+ (1.0,0.0) [0.0|1.0] ""  ESC,IBOX
 SG_ ECFail : 2|1@1+ (1.0,0.0) [0.0|1.0] ""  ESC,IBOX
 SG_ SwitchOffCondExt : 3|1@1+ (1.0,0.0) [0.0|1.0] ""  ESC,IBOX
 SG_ BLECFail : 4|1@1+ (1.0,0.0) [0.0|1.0] ""  ESC,IBOX
 SG_ CF_Ems_IsaAct : 5|1@1+ (1.0,0.0) [0.0|1.0] ""  CLU
 SG_ FA_PV_CAN : 8|8@1+ (0.3906,0.0) [0.0|99.2] "%"  IBOX,LDWS_LKAS,TCU
 SG_ IntAirTemp : 16|8@1+ (0.75,-48.0) [-48.0|143.25] "deg"  _4WD,ECS,EPB,IBOX,TCU
 SG_ STATE_DC_OBD : 24|7@1+ (1.0,0.0) [0.0|127.0] ""  IBOX,TCU
 SG_ INH_DC_OBD : 31|1@1+ (1.0,0.0) [0.0|1.0] ""  IBOX,TCU
 SG_ CTR_IG_CYC_OBD : 32|16@1+ (1.0,0.0) [0.0|65535.0] ""  ACU,IBOX,TCU
 SG_ CTR_CDN_OBD : 48|16@1+ (1.0,0.0) [0.0|65535.0] ""  IBOX,TCU

BO_ 1350 DI_BOX12: 8 DI_BOX
 SG_ CF_DiBox_FrtInjVDiagReg0 : 0|8@1+ (1.0,0.0) [0.0|255.0] ""  EMS
 SG_ CF_DiBox_FrtInjVDiagReg1 : 8|8@1+ (1.0,0.0) [0.0|255.0] ""  EMS
 SG_ CF_DiBox_FrtInjVDiagReg2 : 16|8@1+ (1.0,0.0) [0.0|255.0] ""  EMS
 SG_ CF_DiBox_SedInjVDiagReg0 : 24|8@1+ (1.0,0.0) [0.0|255.0] ""  EMS
 SG_ CF_DiBox_SedInjVDiagReg1 : 32|8@1+ (1.0,0.0) [0.0|255.0] ""  EMS
 SG_ CF_DiBox_SedInjVDiagReg2 : 40|8@1+ (1.0,0.0) [0.0|255.0] ""  EMS
 SG_ CR_DiBox_BatVol : 48|8@1+ (0.1,0.0) [0.0|25.5] "V"  EMS
 SG_ CF_DiBox_SedInjVChg : 56|1@1+ (1.0,0.0) [0.0|1.0] ""  EMS
 SG_ CF_DiBox_FrtInjVChg : 57|1@1+ (1.0,0.0) [0.0|1.0] ""  EMS
 SG_ CF_DiBox_SedInjVErrSPI : 58|1@1+ (1.0,0.0) [0.0|1.0] ""  EMS
 SG_ CF_DiBox_FrtInjVErrSPI : 59|1@1+ (1.0,0.0) [0.0|1.0] ""  EMS

BO_ 1349 EMS14: 8 EMS
 SG_ IMMO_LAMP_STAT : 0|1@1+ (1.0,0.0) [0.0|1.0] ""  CLU,IBOX
 SG_ L_MIL : 1|1@1+ (1.0,0.0) [0.0|1.0] ""  CLU,CUBIS,IBOX
 SG_ IM_STAT : 2|1@1+ (1.0,0.0) [0.0|1.0] ""  CLU,IBOX
 SG_ AMP_CAN : 3|5@1+ (10.731613,458.98) [458.98|791.660003] "mmHg"  CLU,IBOX,TCU,TPMS
 SG_ BAT_Alt_FR_Duty : 8|8@1+ (0.4,0.0) [0.0|100.0] "%"  CGW,CUBIS,IBOX,TMU
 SG_ VB : 24|8@1+ (0.1015625,0.0) [0.0|25.8984375] "V"  CLU,CUBIS,DATC,EPB,FPCM,IBOX
 SG_ EMS_VS : 32|12@1+ (0.0625,0.0) [0.0|255.875] "km/h"  CLU
 SG_ TEMP_FUEL : 56|8@1+ (0.75,-48.0) [-48.0|143.25] "deg"  FPCM

BO_ 68 DATC11: 8 DATC
 SG_ CF_Datc_Type : 0|8@1+ (1.0,0.0) [0.0|255.0] ""  CLU
 SG_ CF_Datc_VerMaj : 8|8@1+ (1.0,0.0) [0.0|255.0] ""  CLU
 SG_ CF_Datc_VerMin : 16|8@1+ (1.0,0.0) [0.0|255.0] ""  CLU
 SG_ CR_Datc_OutTempC : 24|8@1+ (0.5,-41.0) [-41.0|86.5] "deg"  CLU,FPCM
 SG_ CR_Datc_OutTempF : 32|8@1+ (1.0,-42.0) [-42.0|213.0] "deg"  CLU
 SG_ CF_Datc_IncarTemp : 40|8@1+ (0.5,-40.0) [-40.0|60.0] "deg"  BCM,CLU

BO_ 67 DATC13: 8 DATC
 SG_ CF_Datc_TempDispUnit : 0|2@1+ (1.0,0.0) [0.0|3.0] ""  CLU,IBOX
 SG_ CF_Datc_ModDisp : 2|4@1+ (1.0,0.0) [0.0|15.0] ""  CLU
 SG_ CF_Datc_IonClean : 6|2@1+ (1.0,0.0) [0.0|3.0] ""  CLU
 SG_ CF_Datc_ChgReqDisp : 8|2@1+ (1.0,0.0) [0.0|3.0] ""  CLU
 SG_ CF_Datc_IntakeDisp : 10|2@1+ (1.0,0.0) [0.0|3.0] ""  CLU
 SG_ CF_Datc_AutoDisp : 12|2@1+ (1.0,0.0) [0.0|3.0] ""  CLU
 SG_ CF_Datc_FrDefLed : 14|2@1+ (1.0,0.0) [0.0|3.0] ""  CLU,IBOX
 SG_ CF_Datc_AutoDefogBlink : 16|2@1+ (1.0,0.0) [0.0|3.0] ""  CLU
 SG_ CF_Datc_ClmScanDisp : 18|2@1+ (1.0,0.0) [0.0|3.0] ""  CLU
 SG_ CF_Datc_AqsDisp : 20|2@1+ (1.0,0.0) [0.0|3.0] ""  CLU
 SG_ CF_Datc_AcDisp : 22|2@1+ (1.0,0.0) [0.0|3.0] ""  CLU
 SG_ CF_Datc_OpSts : 25|3@1+ (1.0,0.0) [0.0|7.0] ""  CLU
 SG_ CF_Mtc_MaxAcDisp : 28|2@1+ (1.0,0.0) [0.0|3.0] ""  CLU
 SG_ CF_Datc_DualDisp : 30|2@1+ (1.0,0.0) [0.0|3.0] ""  CLU
 SG_ CF_Datc_PwrInf : 32|4@1+ (1.0,0.0) [0.0|15.0] ""  CLU
 SG_ CF_Datc_RearManual : 38|2@1+ (1.0,0.0) [0.0|3.0] ""  CLU
 SG_ CF_Datc_RearAutoDisp : 40|2@1+ (1.0,0.0) [0.0|1.0] ""  CLU
 SG_ CF_Datc_RearOffDisp : 42|2@1+ (1.0,0.0) [0.0|3.0] ""  CLU
 SG_ CF_Datc_RearClimateScnDisp : 44|2@1+ (1.0,0.0) [0.0|3.0] ""  CLU
 SG_ CF_Datc_RearChgReqDisp : 46|2@1+ (1.0,0.0) [0.0|3.0] ""  CLU
 SG_ CF_Datc_RearModDisp : 48|4@1+ (1.0,0.0) [0.0|15.0] ""  CLU
 SG_ CF_Datc_RearBlwDisp : 52|4@1+ (1.0,0.0) [0.0|15.0] ""  CLU
 SG_ CF_Datc_PSModDisp : 56|4@1+ (1.0,0.0) [0.0|15.0] ""  CLU
 SG_ CF_Datc_FrontBlwDisp : 60|4@1+ (1.0,0.0) [0.0|15.0] ""  CLU,IBOX

BO_ 66 DATC12: 8 DATC
 SG_ CR_Datc_DrTempDispC : 0|8@1+ (0.5,14.0) [15.0|32.0] "deg"  CLU,IBOX
 SG_ CR_Datc_DrTempDispF : 8|8@1+ (1.0,56.0) [58.0|90.0] "deg"  CLU,IBOX
 SG_ CR_Datc_PsTempDispC : 16|8@1+ (0.5,14.0) [15.0|32.0] "deg"  CLU,IBOX
 SG_ CR_Datc_PsTempDispF : 24|8@1+ (1.0,56.0) [58.0|90.0] "deg"  CLU,IBOX
 SG_ CR_Datc_RearDrTempDispC : 40|8@1+ (0.5,14.0) [15.0|32.0] "deg"  CLU
 SG_ CR_Datc_RearDrTempDispF : 48|8@1+ (1.0,58.0) [58.0|90.0] "deg"  CLU
 SG_ CF_Datc_CO2_Warning : 56|8@1+ (1.0,0.0) [0.0|3.0] ""  CLU

BO_ 1345 CGW1: 8 BCM
 SG_ CF_Gway_IGNSw : 0|3@1+ (1.0,0.0) [0.0|7.0] ""  AVM,CLU,ECS,EMS,EPB,ESC,IBOX,LVR,MDPS,SAS,SCC,ECS,EMS,EPB,ESC,IBOX,LVR,MDPS,SAS,SCC
 SG_ CF_Gway_RKECmd : 3|3@1+ (1.0,0.0) [0.0|7.0] ""  CLU,ECS,EMS,IBOX,ECS,EMS,IBOX
 SG_ CF_Gway_DrvKeyLockSw : 6|1@1+ (1.0,0.0) [0.0|1.0] ""  ECS,EMS,IBOX,ECS,EMS,IBOX
 SG_ CF_Gway_DrvKeyUnlockSw : 7|1@1+ (1.0,0.0) [0.0|1.0] ""  ECS,EMS,IBOX,ECS,EMS,IBOX
 SG_ CF_Gway_DrvDrSw : 8|2@1+ (1.0,0.0) [0.0|3.0] ""  CLU,ECS,EMS,EPB,ESC,IBOX,SCC,TCU,ECS,EMS,EPB,ESC,IBOX,SCC,TCU
 SG_ CF_Gway_DrvSeatBeltSw : 10|2@1+ (1.0,0.0) [0.0|3.0] ""  EMS,EPB,ESC,IBOX,PSB,TCU,EMS,EPB,ESC,IBOX,PSB,TCU
 SG_ CF_Gway_TrunkTgSw : 12|2@1+ (1.0,0.0) [0.0|3.0] ""  CLU,ECS,EMS,EPB,ESC,IBOX,ECS,EMS,EPB,ESC,IBOX
 SG_ CF_Gway_AstSeatBeltSw : 14|2@1+ (1.0,0.0) [0.0|3.0] ""  IBOX,PSB,IBOX,PSB
 SG_ CF_Gway_SMKOption : 16|1@1+ (1.0,0.0) [0.0|1.0] ""  CLU,EMS,IBOX,EMS,IBOX,SMK
 SG_ CF_Gway_HoodSw : 17|2@1+ (1.0,0.0) [0.0|3.0] ""  CLU,EMS,EPB,ESC,IBOX,EMS,EPB,ESC,IBOX
 SG_ CF_Gway_TurnSigLh : 19|2@1+ (1.0,0.0) [0.0|3.0] ""  CLU,EMS,IBOX,LCA,LDWS_LKAS,SCC,EMS,IBOX,LCA,LDWS_LKAS,SCC
 SG_ CF_Gway_WiperIntT : 21|3@1+ (1.0,0.0) [0.0|7.0] ""  CLU,EMS,IBOX,LDWS_LKAS,EMS,ESC,IBOX,LDWS_LKAS
 SG_ CF_Gway_WiperIntSw : 24|1@1+ (1.0,0.0) [0.0|1.0] ""  CLU,EMS,IBOX,LDWS_LKAS,EMS,ESC,IBOX,LDWS_LKAS
 SG_ CF_Gway_WiperLowSw : 25|1@1+ (1.0,0.0) [0.0|1.0] ""  CLU,EMS,IBOX,LDWS_LKAS,EMS,ESC,IBOX,LDWS_LKAS
 SG_ CF_Gway_WiperHighSw : 26|1@1+ (1.0,0.0) [0.0|1.0] ""  CLU,EMS,IBOX,LDWS_LKAS,EMS,ESC,IBOX,LDWS_LKAS
 SG_ CF_Gway_WiperAutoSw : 27|1@1+ (1.0,0.0) [0.0|1.0] ""  CLU,EMS,IBOX,LDWS_LKAS,EMS,ESC,IBOX,LDWS_LKAS
 SG_ CF_Gway_RainSnsState : 28|3@1+ (1.0,0.0) [0.0|7.0] ""  AFLS,EMS,IBOX,LDWS_LKAS,AFLS,EMS,ESC,IBOX,LDWS_LKAS
 SG_ CF_Gway_HeadLampLow : 31|1@1+ (1.0,0.0) [0.0|1.0] ""  AFLS,CLU,EMS,IBOX,LDWS_LKAS,SNV,AFLS,EMS,IBOX,LDWS_LKAS,SNV
 SG_ CF_Gway_HeadLampHigh : 32|1@1+ (1.0,0.0) [0.0|1.0] ""  AFLS,CLU,EMS,IBOX,LDWS_LKAS,AFLS,EMS,IBOX,LDWS_LKAS
 SG_ CF_Gway_HazardSw : 33|2@1+ (1.0,0.0) [0.0|3.0] ""  ABS,EMS,ESC,IBOX,LCA,LDWS_LKAS,ABS,EMS,ESC,IBOX,LCA,LDWS_LKAS
 SG_ CF_Gway_AstDrSw : 35|1@1+ (1.0,0.0) [0.0|1.0] ""  CLU,IBOX,IBOX
 SG_ CF_Gway_DefoggerRly : 36|1@1+ (1.0,0.0) [0.0|1.0] ""  EMS,IBOX,EMS,IBOX
 SG_ CF_Gway_ALightStat : 37|1@1+ (1.0,0.0) [0.0|1.0] ""  AFLS,IBOX,LDWS_LKAS,AFLS,IBOX,LDWS_LKAS
 SG_ CF_Gway_LightSwState : 38|2@1+ (1.0,0.0) [0.0|3.0] ""  AFLS,IBOX,LDWS_LKAS,AFLS,IBOX,LDWS_LKAS
 SG_ CF_Gway_Frt_Fog_Act : 40|1@1+ (1.0,0.0) [0.0|1.0] ""  AFLS,CLU,IBOX,LDWS_LKAS,AFLS,IBOX,LDWS_LKAS
 SG_ CF_Gway_TSigRHSw : 41|1@1+ (1.0,0.0) [0.0|1.0] ""  IBOX,LDWS_LKAS,IBOX,LDWS_LKAS
 SG_ CF_Gway_TSigLHSw : 42|1@1+ (1.0,0.0) [0.0|1.0] ""  IBOX,LDWS_LKAS,IBOX,LDWS_LKAS
 SG_ CF_Gway_DriveTypeOption : 43|1@1+ (1.0,0.0) [0.0|1.0] ""  CLU,IBOX,LDWS_LKAS,IBOX,LDWS_LKAS
 SG_ CF_Gway_StarterRlyState : 44|1@1+ (1.0,0.0) [0.0|1.0] ""  EMS,IBOX,EMS,IBOX,SMK
 SG_ CF_Gway_PassiveAccessLock : 45|2@1+ (1.0,0.0) [0.0|7.0] ""  CLU,ECS,EMS,IBOX,ECS,EMS,IBOX,SMK
 SG_ CF_Gway_WiperMistSw : 47|1@1+ (1.0,0.0) [0.0|1.0] ""  CLU,EMS,IBOX,LDWS_LKAS
 SG_ CF_Gway_PassiveAccessUnlock : 48|2@1+ (1.0,0.0) [0.0|7.0] ""  CLU,ECS,EMS,IBOX,ECS,EMS,IBOX,SMK
 SG_ CF_Gway_RrSunRoofOpenState : 50|1@1+ (1.0,0.0) [0.0|1.0] ""  CLU,DATC,IBOX
 SG_ CF_Gway_PassingSW : 51|1@1+ (1.0,0.0) [0.0|1.0] ""  AFLS,IBOX,LDWS_LKAS,AFLS,IBOX,LDWS_LKAS
 SG_ CF_Gway_HBAControlMode : 52|1@1+ (1.0,0.0) [0.0|1.0] ""  IBOX,LDWS_LKAS,IBOX,LDWS_LKAS
 SG_ CF_Gway_HLpHighSw : 53|1@1+ (1.0,0.0) [0.0|1.0] ""  IBOX,LDWS_LKAS,IBOX,LDWS_LKAS
 SG_ CF_Gway_InhibitRMT : 54|2@1+ (1.0,0.0) [0.0|3.0] ""  EMS,EPB,ESC,IBOX,LCA,LDWS_LKAS,MDPS,PGS,SCC,SPAS,TPMS,EPB,ESC,IBOX,LCA,LDWS_LKAS,PGS,SCC,SPAS,TPMS
 SG_ CF_Gway_RainSnsOption : 56|1@1+ (1.0,0.0) [0.0|1.0] ""  CLU
 SG_ C_SunRoofOpenState : 57|1@1+ (1.0,0.0) [0.0|1.0] ""  CLU,DATC,IBOX,DATC,IBOX
 SG_ CF_Gway_Ign1 : 58|1@1+ (1.0,0.0) [0.0|1.0] ""  CLU
 SG_ CF_Gway_Ign2 : 59|1@1+ (1.0,0.0) [0.0|1.0] ""  CLU
 SG_ CF_Gway_ParkBrakeSw : 60|2@1+ (1.0,0.0) [0.0|3.0] ""  CLU,ESC,IBOX,SCC,ESC,IBOX,SCC
 SG_ CF_Gway_TurnSigRh : 62|2@1+ (1.0,0.0) [0.0|3.0] ""  CLU,EMS,IBOX,LCA,LDWS_LKAS,SCC,EMS,IBOX,LCA,LDWS_LKAS,SCC

BO_ 832 LKAS11: 8 LDWS_LKAS
 SG_ CF_Lkas_LdwsActivemode : 0|2@1+ (1,0) [0|3] "" CLU,IBOX,PSB
 SG_ CF_Lkas_LdwsSysState : 2|4@1+ (1.0,0.0) [0.0|15.0] ""  CLU,IBOX,PSB
 SG_ CF_Lkas_SysWarning : 6|4@1+ (1.0,0.0) [0.0|15.0] ""  BCM,CLU
 SG_ CF_Lkas_LdwsLHWarning : 10|2@1+ (1.0,0.0) [0.0|3.0] ""  BCM,CLU,PSB
 SG_ CF_Lkas_LdwsRHWarning : 12|2@1+ (1.0,0.0) [0.0|3.0] ""  BCM,CLU,PSB
 SG_ CF_Lkas_HbaLamp : 14|1@1+ (1.0,0.0) [0.0|1.0] ""  CLU
 SG_ CF_Lkas_FcwBasReq : 15|1@1+ (1.0,0.0) [0.0|1.0] ""  ABS,ESC
 SG_ CR_Lkas_StrToqReq : 16|11@1+ (1.0,-1024.0) [-1024.0|1024.0] ""  MDPS
 SG_ CF_Lkas_ActToi : 27|1@1+ (1.0,0.0) [0.0|1.0] ""  MDPS
 SG_ CF_Lkas_ToiFlt : 28|1@1+ (1.0,0.0) [0.0|1.0] ""  MDPS
 SG_ CF_Lkas_HbaSysState : 29|3@1+ (1.0,0.0) [0.0|7.0] ""  BCM,CLU
 SG_ CF_Lkas_FcwOpt : 32|2@1+ (1.0,0.0) [0.0|3.0] ""  CLU
 SG_ CF_Lkas_HbaOpt : 34|2@1+ (1.0,0.0) [0.0|1.0] ""  BCM,CGW
 SG_ CF_Lkas_MsgCount : 36|4@1+ (1.0,0.0) [0.0|15.0] ""  CLU,MDPS
 SG_ CF_Lkas_FcwSysState : 40|3@1+ (1.0,0.0) [0.0|7.0] ""  CLU
 SG_ CF_Lkas_FcwCollisionWarning : 43|2@1+ (1.0,0.0) [0.0|3.0] ""  CLU
 SG_ CF_Lkas_FusionState : 45|2@1+ (1.0,0.0) [0.0|3.0] ""  SCC
 SG_ CF_Lkas_Unknown1 : 47|1@1+ (1.0,0.0) [0.0|1.0] "" XXX
 SG_ CF_Lkas_Chksum : 48|8@1+ (1.0,0.0) [0.0|255.0] ""  MDPS
 SG_ CF_Lkas_FcwOpt_USM : 56|3@1+ (1.0,0.0) [0.0|7.0] ""  CLU
 SG_ CF_Lkas_LdwsOpt_USM : 59|3@1+ (1.0,0.0) [0.0|7.0] ""  CLU,MDPS
 SG_ CF_Lkas_Unknown2 : 62|2@1+ (1.0,0.0) [0.0|1.0] "" XXX

BO_ 1342 LKAS12: 6 LDWS_LKAS
 SG_ CF_Lkas_TsrSlifOpt : 10|2@1+ (1.0,0.0) [0.0|3.0] ""  CLU
 SG_ CF_LkasTsrStatus : 12|2@1+ (1.0,0.0) [0.0|3.0] ""  CLU
 SG_ CF_Lkas_TsrSpeed_Display_Clu : 16|8@1+ (1.0,0.0) [0.0|255.0] ""  CLU
 SG_ CF_LkasTsrSpeed_Display_Navi : 24|8@1+ (1.0,0.0) [0.0|255.0] ""  BCM,CLU
 SG_ CF_Lkas_TsrAddinfo_Display : 32|2@1+ (1.0,0.0) [0.0|3.0] ""  CLU
 SG_ CF_LkasDawStatus : 40|3@1+ (1,0) [0|7] "" CLU
 SG_ CF_Lkas_Daw_USM : 37|3@1+ (1,0) [0|7] "" CLU

BO_ 1338 TMU_GW_E_01: 8 CLU
 SG_ CF_Gway_TeleReqDrLock : 0|2@1+ (1.0,0.0) [0.0|3.0] ""  BCM
 SG_ CF_Gway_TeleReqDrUnlock : 2|2@1+ (1.0,0.0) [0.0|3.0] ""  BCM
 SG_ CF_Gway_TeleReqHazard : 4|2@1+ (1.0,0.0) [0.0|3.0] ""  BCM
 SG_ CF_Gway_TeleReqHorn : 6|2@1+ (1.0,0.0) [0.0|3.0] ""  BCM
 SG_ CF_Gway_TeleReqEngineOperate : 8|2@1+ (1.0,0.0) [0.0|3.0] ""  BCM

BO_ 1078 PAS11: 4 BCM
 SG_ CF_Gway_PASDisplayFLH : 0|3@1+ (1.0,0.0) [0.0|7.0] ""  AVM,CLU,AVM
 SG_ CF_Gway_PASDisplayFRH : 3|3@1+ (1.0,0.0) [0.0|7.0] ""  AVM,CLU,AVM
 SG_ CF_Gway_PASRsound : 6|2@1+ (1.0,0.0) [0.0|3.0] ""  CLU,Dummy
 SG_ CF_Gway_PASDisplayFCTR : 8|3@1+ (1.0,0.0) [0.0|7.0] ""  AVM,CLU,AVM
 SG_ CF_Gway_PASDisplayRCTR : 11|3@1+ (1.0,0.0) [0.0|7.0] ""  AVM,CLU,PGS,AVM
 SG_ CF_Gway_PASFsound : 14|2@1+ (1.0,0.0) [0.0|3.0] ""  CLU,Dummy
 SG_ CF_Gway_PASDisplayRLH : 16|3@1+ (1.0,0.0) [0.0|7.0] ""  AVM,CLU,PGS,AVM
 SG_ CF_Gway_PASDisplayRRH : 19|3@1+ (1.0,0.0) [0.0|7.0] ""  AVM,CLU,PGS,AVM
 SG_ CF_Gway_PASCheckSound : 22|2@1+ (1.0,0.0) [0.0|3.0] ""  CLU,Dummy
 SG_ CF_Gway_PASSystemOn : 24|2@1+ (1.0,0.0) [0.0|3.0] ""  CLU,Dummy
 SG_ CF_Gway_PASOption : 26|2@1+ (1.0,0.0) [0.0|3.0] ""  CLU
 SG_ CF_Gway_PASDistance : 28|1@1+ (1.0,0.0) [0.0|1.0] ""  CLU

BO_ 48 EMS18: 6 EMS
 SG_ CF_Ems_DC1NumPerMSV : 0|8@1+ (1.0,0.0) [0.0|255.0] ""  DI_BOX
 SG_ CF_Ems_DC2NumPerMSV : 8|16@1+ (1.0,0.0) [0.0|65535.0] ""  DI_BOX
 SG_ CR_Ems_DutyCyc1MSV : 24|8@1+ (0.1953,0.0) [0.0|49.8] "%"  DI_BOX
 SG_ CR_Ems_DutyCyc2MSV : 32|8@1+ (0.13725,0.0) [0.0|35.0] "%"  DI_BOX
 SG_ CR_Ems_DutyCyc3MSV : 40|8@1+ (0.392,0.0) [0.0|100.0] "%"  DI_BOX

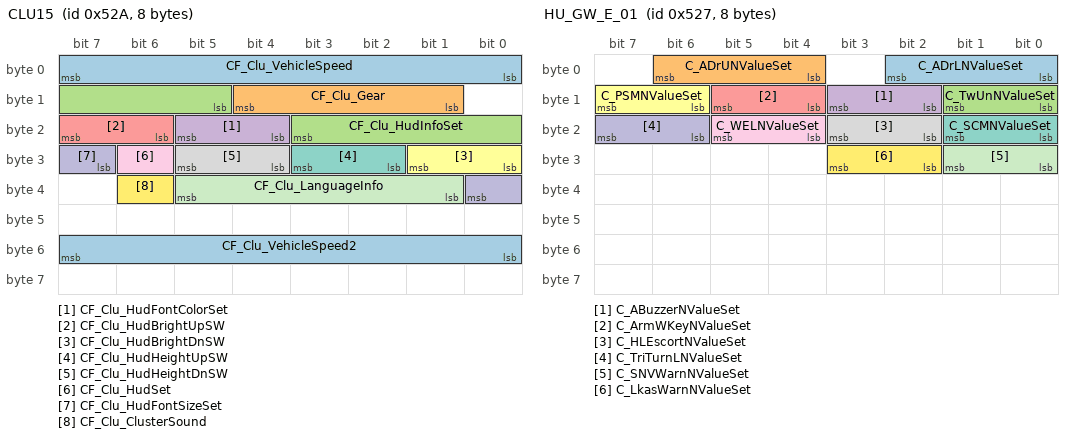
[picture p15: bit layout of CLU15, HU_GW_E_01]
BO_ 1322 CLU15: 8 CLU
 SG_ CF_Clu_VehicleSpeed : 0|8@1+ (1.0,0.0) [0.0|255.0] ""  BCM
 SG_ CF_Clu_Gear : 9|4@1+ (1,0) [0|15] "" BCM
 SG_ CF_Clu_HudInfoSet : 13|7@1+ (1.0,0.0) [0.0|127.0] ""  HUD
 SG_ CF_Clu_HudFontColorSet : 20|2@1+ (1.0,0.0) [0.0|3.0] ""  HUD
 SG_ CF_Clu_HudBrightUpSW : 22|2@1+ (1.0,0.0) [0.0|3.0] ""  HUD
 SG_ CF_Clu_HudBrightDnSW : 24|2@1+ (1.0,0.0) [0.0|3.0] ""  HUD
 SG_ CF_Clu_HudHeightUpSW : 26|2@1+ (1.0,0.0) [0.0|3.0] ""  HUD
 SG_ CF_Clu_HudHeightDnSW : 28|2@1+ (1.0,0.0) [0.0|3.0] ""  HUD
 SG_ CF_Clu_HudSet : 30|1@1+ (1.0,0.0) [0.0|1.0] ""  HUD
 SG_ CF_Clu_HudFontSizeSet : 31|2@1+ (1.0,0.0) [0.0|3.0] ""  HUD
 SG_ CF_Clu_LanguageInfo : 33|5@1+ (1.0,0.0) [0.0|31.0] ""  BCM,PGS
 SG_ CF_Clu_ClusterSound : 38|1@1- (1.0,0.0) [0.0|0.0] ""  BCM,CGW,FATC
 SG_ CF_Clu_VehicleSpeed2 : 48|8@1+ (1,0) [0|255] "" XXX

BO_ 1066 _4WD13: 6 _4WD
 SG_ _4WD_CURRENT : 0|8@1+ (0.390625,0.0) [-50.0|50.0] "A"  TCU
 SG_ _4WD_POSITION : 8|16@1+ (0.015625,0.0) [-180.0|180.0] "Deg"  TCU
 SG_ _4WD_CLU_THERM_STR : 24|8@1+ (1.0,0.0) [0.0|100.0] "%"  TCU
 SG_ _4WD_STATUS : 32|8@1+ (1.0,0.0) [0.0|15.0] ""  ESC,TCU

BO_ 1065 _4WD12: 8 _4WD
 SG_ Ster_Pos : 0|16@1+ (1.0,-600.0) [-600.0|600.0] "Deg"  ESC
 SG_ FRSS : 16|8@1+ (1.0,0.0) [0.0|254.0] "km/h"  ESC
 SG_ FLSS : 24|8@1+ (1.0,0.0) [0.0|254.0] "km/h"  ESC
 SG_ RRSS : 32|8@1+ (1.0,0.0) [0.0|254.0] "km/h"  ESC
 SG_ RLSS : 40|8@1+ (1.0,0.0) [0.0|254.0] "km/h"  ESC
 SG_ CLU_PRES : 48|16@1+ (0.0625,-50.0) [-50.0|50.0] "Bar"  ESC

BO_ 809 EMS12: 8 EMS
 SG_ CONF_TCU m1 : 0|6@1+ (1.0,0.0) [0.0|63.0] ""  _4WD,ACU,BCM,CLU,DATC,EPB,ESC,IBOX,LCA,SMK
 SG_ CAN_VERS m0 : 0|6@1+ (1.0,0.0) [0.0|7.7] ""  _4WD,ABS,ESC,IBOX
 SG_ TQ_STND m3 : 0|6@1+ (10.0,0.0) [0.0|630.0] "Nm"  _4WD,DATC,ECS,EPB,ESC,FATC,IBOX
 SG_ OBD_FRF_ACK m2 : 0|6@1+ (1.0,0.0) [0.0|63.0] ""  _4WD,ESC,IBOX
 SG_ MUL_CODE M : 6|2@1+ (1.0,0.0) [0.0|3.0] ""  _4WD,ABS,ACU,BCM,CLU,DATC,ECS,EPB,ESC,IBOX,LCA,SMK,TCU
 SG_ TEMP_ENG : 8|8@1+ (0.75,-48.0) [-48.0|143.25] "deg"  _4WD,BCM,CLU,DATC,EPB,ESC,IBOX,SMK,TCU
 SG_ MAF_FAC_ALTI_MMV : 16|8@1+ (0.00781,0.0) [0.0|1.99155] ""  IBOX,TCU
 SG_ VB_OFF_ACT : 24|1@1+ (1.0,0.0) [0.0|1.0] ""  IBOX,TCU
 SG_ ACK_ES : 25|1@1+ (1.0,0.0) [0.0|1.0] ""  _4WD,ACU,IBOX
 SG_ CONF_MIL_FMY : 26|3@1+ (1.0,0.0) [0.0|7.0] ""  ESC,IBOX,TCU
 SG_ OD_OFF_REQ : 29|1@1+ (1.0,0.0) [0.0|1.0] ""  IBOX,TCU
 SG_ ACC_ACT : 30|1@1+ (1.0,0.0) [0.0|1.0] ""  _4WD,ABS,CLU,ESC,IAP,IBOX,SCC,TCU
 SG_ CLU_ACK : 31|1@1+ (1.0,0.0) [0.0|1.0] ""  _4WD,EPB,ESC,IBOX
 SG_ BRAKE_ACT : 32|2@1+ (1.0,0.0) [0.0|3.0] ""  _4WD,ABS,ACU,AFLS,CLU,DATC,ECS,EPB,ESC,IBOX,LDWS_LKAS,TCU
 SG_ ENG_CHR : 34|4@1+ (1.0,0.0) [0.0|15.0] ""  _4WD,ABS,ACU,CLU,DATC,EPB,ESC,FATC,IBOX,SCC,SMK,TCU
 SG_ GP_CTL : 38|2@1+ (1.0,0.0) [0.0|3.0] ""  IBOX
 SG_ TPS : 40|8@1+ (0.4694836,-15.0234742) [-15.0234742|104.6948357] "%"  _4WD,ABS,ACU,CLU,DATC,ECS,EPB,ESC,IBOX,TCU
 SG_ PV_AV_CAN : 48|8@1+ (0.3906,0.0) [0.0|99.603] "%"  _4WD,AAF,ABS,ACU,AFLS,CLU,DATC,EPB,ESC,IAP,IBOX,LDWS_LKAS,SCC,TCU
 SG_ ENG_VOL : 56|8@1+ (0.1,0.0) [0.0|25.5] "liter"  _4WD,ABS,ACU,BCM,CLU,DATC,EPB,ESC,IBOX,LDWS_LKAS,SCC,SMK

BO_ 1064 _4WD11: 8 _4WD
 SG_ _4WD_TYPE : 0|2@1+ (1.0,0.0) [0.0|3.0] ""  ACU,ESC,TPMS
 SG_ _4WD_SUPPORT : 2|2@1+ (1.0,0.0) [0.0|3.0] ""  ABS,ESC,TPMS
 SG_ _4WD_ERR : 8|8@1+ (1.0,0.0) [0.0|255.0] ""  CLU,ESC
 SG_ CLU_DUTY : 16|8@1+ (1.0,0.0) [0.0|64.0] "%"  ABS,ESC
 SG_ R_TIRE : 24|8@1+ (1.0,200.0) [200.0|455.0] "mm"  ABS,ESC,TPMS
 SG_ _4WD_SW : 32|8@1+ (1.0,0.0) [0.0|9.9] ""  ESC
 SG_ _2H_ACT : 40|1@1+ (1.0,0.0) [0.0|1.0] ""  ABS,ESC
 SG_ _4H_ACT : 41|1@1+ (1.0,0.0) [0.0|1.0] ""  ABS,CLU,ESC,TPMS
 SG_ LOW_ACT : 42|1@1+ (1.0,0.0) [0.0|1.0] ""  ABS,ESC,TCU,TPMS
 SG_ AUTO_ACT : 43|1@1+ (1.0,0.0) [0.0|1.0] ""  ABS,ESC,TPMS
 SG_ LOCK_ACT : 44|1@1+ (1.0,0.0) [0.0|1.0] ""  ABS,CLU,ESC,TPMS
 SG_ _4WD_TQC_CUR : 48|16@1+ (1.0,0.0) [0.0|65535.0] "Nm"  ABS,ESC

BO_ 1319 HU_GW_E_01: 8 CLU
 SG_ C_ADrLNValueSet : 0|3@1+ (1.0,0.0) [0.0|7.0] ""  BCM
 SG_ C_ADrUNValueSet : 4|3@1+ (1.0,0.0) [0.0|7.0] ""  BCM
 SG_ C_TwUnNValueSet : 8|2@1+ (1.0,0.0) [0.0|3.0] ""  BCM
 SG_ C_ABuzzerNValueSet : 10|2@1+ (1.0,0.0) [0.0|3.0] ""  BCM
 SG_ C_ArmWKeyNValueSet : 12|2@1+ (1.0,0.0) [0.0|3.0] ""  BCM
 SG_ C_PSMNValueSet : 14|2@1+ (1.0,0.0) [0.0|3.0] ""  BCM
 SG_ C_SCMNValueSet : 16|2@1+ (1.0,0.0) [0.0|3.0] ""  BCM
 SG_ C_HLEscortNValueSet : 18|2@1+ (1.0,0.0) [0.0|3.0] ""  BCM
 SG_ C_WELNValueSet : 20|2@1+ (1.0,0.0) [0.0|3.0] ""  BCM
 SG_ C_TriTurnLNValueSet : 22|2@1+ (1.0,0.0) [0.0|3.0] ""  BCM
 SG_ C_SNVWarnNValueSet : 24|2@1+ (1.0,0.0) [0.0|3.0] ""  BCM
 SG_ C_LkasWarnNValueSet : 26|2@1+ (1.0,0.0) [0.0|3.0] ""  BCM

BS_:

BU_: XXX CAMERA FRONT_RADAR ADRV APRK

BS_:

BU_: IAP ODS _4WD BCM HUD DATC MDPS AAF_Tester AEMC SMK _4WD EPB CUBIS MTS TMU EVP CGW TPMS LPI DI_BOX SPAS EMS LCA TCU IBOX FATC AFLS FPCM SCC AHLS AVM ABS SNV OPI PGS SAS AAF Dummy LDWS_LKAS LVR ESC PSB CLU ECS ACU REA

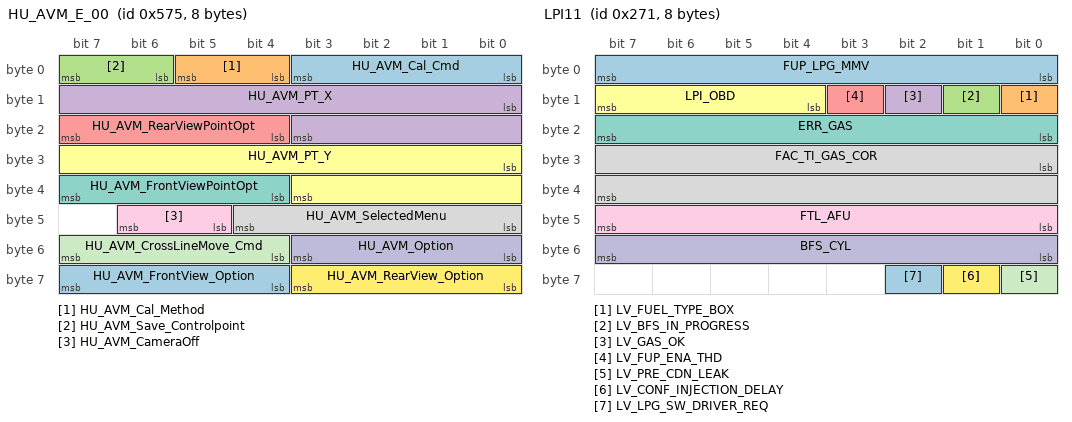
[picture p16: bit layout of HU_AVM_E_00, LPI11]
BO_ 1397 HU_AVM_E_00: 8 CLU
 SG_ HU_AVM_Cal_Cmd : 0|4@1+ (1.0,0.0) [0.0|15.0] ""  AVM,PGS
 SG_ HU_AVM_Cal_Method : 4|2@1+ (1.0,0.0) [0.0|3.0] ""  AVM,PGS
 SG_ HU_AVM_Save_Controlpoint : 6|2@1+ (1.0,0.0) [0.0|3.0] ""  AVM,PGS
 SG_ HU_AVM_PT_X : 8|12@1+ (1.0,0.0) [0.0|15.0] ""  AVM,PGS
 SG_ HU_AVM_RearViewPointOpt : 20|4@1+ (1.0,0.0) [0.0|15.0] ""  AVM,PGS
 SG_ HU_AVM_PT_Y : 24|12@1+ (1.0,0.0) [0.0|4095.0] ""  AVM,PGS
 SG_ HU_AVM_FrontViewPointOpt : 36|4@1+ (1.0,0.0) [0.0|15.0] ""  AVM,PGS
 SG_ HU_AVM_SelectedMenu : 40|5@1+ (1.0,0.0) [0.0|31.0] ""  AVM,PGS
 SG_ HU_AVM_CameraOff : 45|2@1+ (1.0,0.0) [0.0|3.0] ""  AVM,PGS
 SG_ HU_AVM_Option : 48|4@1+ (1.0,0.0) [0.0|15.0] ""  AVM,PGS
 SG_ HU_AVM_CrossLineMove_Cmd : 52|4@1+ (1.0,0.0) [0.0|15.0] ""  AVM,PGS
 SG_ HU_AVM_RearView_Option : 56|4@1+ (1.0,0.0) [0.0|15.0] ""  AVM,PGS
 SG_ HU_AVM_FrontView_Option : 60|4@1+ (1.0,0.0) [0.0|15.0] ""  AVM,PGS

BO_ 1395 HU_AVM_E_01: 8 CLU
 SG_ HU_PGSSelectedMenu : 0|4@1+ (1.0,0.0) [0.0|15.0] ""  AVM,PGS
 SG_ HU_PGSOption : 8|5@1+ (1.0,0.0) [0.0|31.0] ""  AVM,PGS
 SG_ HU_AVM_ParkingAssistMenu : 56|4@1+ (1.0,0.0) [0.0|15.0] ""  AVM,PGS
 SG_ HU_AVM_ParkingAssistSB : 60|4@1+ (1.0,0.0) [0.0|15.0] ""  AVM,PGS

BO_ 1393 OPI11: 5 OPI
 SG_ CR_Opi_Spd_Rpm : 0|8@1+ (20.0,0.0) [0.0|3500.0] "rpm"  TCU
 SG_ CF_Opi_Over_Temp : 8|1@1+ (1.0,0.0) [0.0|1.0] ""  TCU
 SG_ CF_Opi_Over_Cur : 9|1@1+ (1.0,0.0) [0.0|1.0] ""  EMS,TCU
 SG_ CF_Opi_Over_Vol : 10|1@1+ (1.0,0.0) [0.0|1.0] ""  TCU
 SG_ CF_Opi_Hall_Fail : 11|1@1+ (1.0,0.0) [0.0|1.0] ""  EMS,TCU
 SG_ CF_Opi_Flt : 12|1@1+ (1.0,0.0) [0.0|1.0] ""  EMS,TCU
 SG_ CF_Opi_Motor_Dir : 15|1@1+ (1.0,0.0) [0.0|1.0] ""  TCU
 SG_ CF_Opi_Romver : 16|8@1+ (1.0,0.0) [0.0|255.0] ""  TCU
 SG_ CF_Opi_PWM_Rate : 24|12@1+ (1.0,0.0) [0.0|100.0] "%"  TCU

BO_ 625 LPI11: 8 LPI
 SG_ FUP_LPG_MMV : 0|8@1+ (128.0,0.0) [0.0|32640.0] "hPa"  EMS
 SG_ LV_FUEL_TYPE_BOX : 8|1@1+ (1.0,0.0) [0.0|1.0] ""  EMS
 SG_ LV_BFS_IN_PROGRESS : 9|1@1+ (1.0,0.0) [0.0|1.0] ""  EMS
 SG_ LV_GAS_OK : 10|1@1+ (1.0,0.0) [0.0|1.0] ""  EMS
 SG_ LV_FUP_ENA_THD : 11|1@1+ (1.0,0.0) [0.0|1.0] ""  BCM,CLU,EMS,SMK
 SG_ LPI_OBD : 12|4@1+ (1.0,0.0) [0.0|15.0] ""  EMS
 SG_ ERR_GAS : 16|8@1+ (1.0,0.0) [0.0|255.0] ""  EMS
 SG_ FAC_TI_GAS_COR : 24|16@1+ (3.05E-5,0.0) [0.0|1.9988175] ""  EMS
 SG_ FTL_AFU : 40|8@1+ (0.392,0.0) [0.0|99.96] "%"  EMS
 SG_ BFS_CYL : 48|8@1+ (1.0,0.0) [0.0|6.0] "Cyl Nr."  EMS
 SG_ LV_PRE_CDN_LEAK : 56|1@1+ (1.0,0.0) [0.0|1.0] ""  EMS
 SG_ LV_CONF_INJECTION_DELAY : 57|1@1+ (1.0,0.0) [0.0|1.0] ""  EMS
 SG_ LV_LPG_SW_DRIVER_REQ : 58|1@1+ (1.0,0.0) [0.0|1.0] ""  EMS

BO_ 356 VSM11: 4 ESC
 SG_ CR_Esc_StrTqReq : 0|12@1+ (0.01,-20.48) [-20.48|20.47] "Nm"  MDPS
 SG_ CF_Esc_Act : 12|1@1+ (1.0,0.0) [0.0|1.0] ""  LDWS_LKAS,MDPS
 SG_ CF_Esc_CtrMode : 13|3@1+ (1.0,0.0) [0.0|7.0] ""  MDPS
 SG_ CF_Esc_Def : 16|1@1+ (1.0,0.0) [0.0|1.0] ""  MDPS
 SG_ CF_Esc_AliveCnt : 17|4@1+ (1.0,0.0) [0.0|15.0] ""  LDWS_LKAS,MDPS
 SG_ CF_Esc_Chksum : 24|8@1+ (1.0,0.0) [0.0|255.0] ""  LDWS_LKAS,MDPS

BO_ 1379 PGS_HU_PE_01: 8 PGS
 SG_ PGS_State : 0|4@1+ (1.0,0.0) [0.0|15.0] ""  CLU
 SG_ PGS_ParkGuideState : 8|5@1+ (1.0,0.0) [0.0|31.0] ""  CLU
 SG_ PGS_Option : 16|5@1+ (1.0,0.0) [0.0|31.0] ""  CLU
 SG_ PGS_Version : 32|16@1+ (1.0,0.0) [0.0|65535.0] ""  CLU

BO_ 1378 HUD11: 4 HUD
 SG_ CF_Hud_HeightStaus : 0|5@1+ (1.0,0.0) [0.0|31.0] ""  CLU
 SG_ CF_Hud_PBackStatus : 6|2@1+ (1.0,0.0) [0.0|0.0] ""  BCM,CLU
 SG_ CF_Hud_Brightness : 8|5@1+ (1.0,0.0) [0.0|31.0] ""  CLU

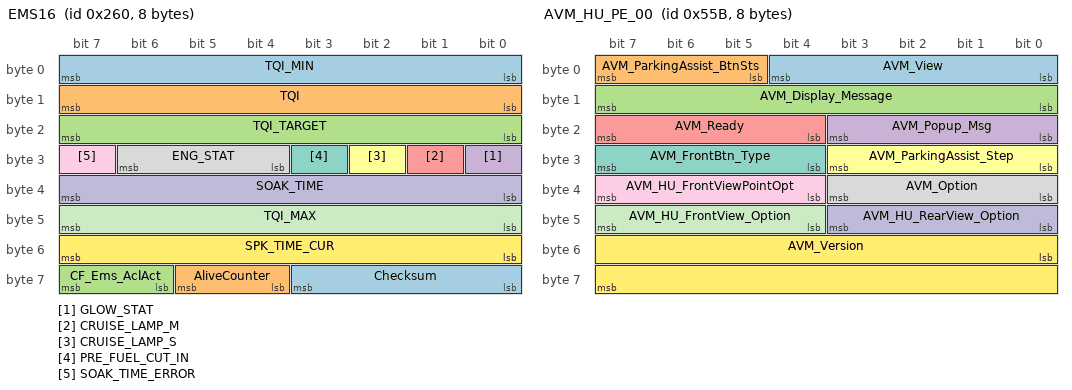
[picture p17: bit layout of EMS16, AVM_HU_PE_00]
BO_ 608 EMS16: 8 EMS
 SG_ TQI_MIN : 0|8@1+ (0.390625,0.0) [0.0|99.609375] "%"  ESC,IBOX,TCU
 SG_ TQI : 8|8@1+ (0.390625,0.0) [0.0|99.609375] "%"  ESC,IBOX,TCU
 SG_ TQI_TARGET : 16|8@1+ (0.390625,0.0) [0.0|99.609375] "%"  EPB,ESC,IBOX,TCU
 SG_ GLOW_STAT : 24|1@1+ (1.0,0.0) [0.0|1.0] ""  BCM,CLU,IBOX,SMK
 SG_ CRUISE_LAMP_M : 25|1@1+ (1.0,0.0) [0.0|1.0] ""  CLU,IBOX,TCU
 SG_ CRUISE_LAMP_S : 26|1@1+ (1.0,0.0) [0.0|1.0] ""  CLU,IBOX,TCU
 SG_ PRE_FUEL_CUT_IN : 27|1@1+ (1.0,0.0) [0.0|1.0] ""  IBOX,TCU
 SG_ ENG_STAT : 28|3@1+ (1.0,0.0) [0.0|7.0] ""  ABS,AHLS,AVM,BCM,CLU,EPB,ESC,EVP,FPCM,IBOX,LCA,LDWS_LKAS,MDPS,SCC,SMK,TCU
 SG_ SOAK_TIME_ERROR : 31|1@1+ (1.0,0.0) [0.0|1.0] ""  DATC,EPB,IBOX,TCU
 SG_ SOAK_TIME : 32|8@1+ (1.0,0.0) [0.0|255.0] "Min"  _4WD,DATC,EPB,IBOX,TCU
 SG_ TQI_MAX : 40|8@1+ (0.390625,0.0) [0.0|99.609375] "%"  ESC,IBOX,TCU
 SG_ SPK_TIME_CUR : 48|8@1+ (0.375,-35.625) [-35.625|60.0] ""  IBOX,TCU
 SG_ Checksum : 56|4@1+ (1.0,0.0) [0.0|15.0] ""  ECS,IBOX,LDWS_LKAS,MDPS,SCC
 SG_ AliveCounter : 60|2@1+ (1.0,0.0) [0.0|3.0] ""  IBOX,LDWS_LKAS,MDPS,SCC
 SG_ CF_Ems_AclAct : 62|2@1+ (1.0,0.0) [0.0|3.0] ""  IBOX,SCC

BO_ 1371 AVM_HU_PE_00: 8 AVM
 SG_ AVM_View : 0|5@1+ (1.0,0.0) [0.0|31.0] ""  CLU
 SG_ AVM_ParkingAssist_BtnSts : 5|3@1+ (1.0,0.0) [0.0|7.0] ""  CLU
 SG_ AVM_Display_Message : 8|8@1+ (1.0,0.0) [0.0|255.0] ""  CLU
 SG_ AVM_Popup_Msg : 16|4@1+ (1.0,0.0) [0.0|15.0] ""  CLU
 SG_ AVM_Ready : 20|4@1+ (1.0,0.0) [0.0|15.0] ""  CLU
 SG_ AVM_ParkingAssist_Step : 24|4@1+ (1.0,0.0) [0.0|15.0] ""  CLU
 SG_ AVM_FrontBtn_Type : 28|4@1+ (1.0,0.0) [0.0|15.0] ""  CLU
 SG_ AVM_Option : 32|4@1+ (1.0,0.0) [0.0|15.0] ""  CLU
 SG_ AVM_HU_FrontViewPointOpt : 36|4@1+ (1.0,0.0) [0.0|15.0] ""  CLU
 SG_ AVM_HU_RearView_Option : 40|4@1+ (1.0,0.0) [0.0|15.0] ""  CLU
 SG_ AVM_HU_FrontView_Option : 44|4@1+ (1.0,0.0) [0.0|15.0] ""  CLU
 SG_ AVM_Version : 48|16@1+ (1.0,0.0) [0.0|65535.0] ""  CLU

BO_ 1370 HU_AVM_PE_00: 8 CLU
 SG_ HU_AVM_Status : 0|2@1+ (1.0,0.0) [0.0|3.0] ""  AVM,PGS

BO_ 1369 CGW4: 8 BCM
 SG_ CF_Gway_MemoryP1Cmd : 0|1@1+ (1.0,0.0) [0.0|1.0] ""  CLU
 SG_ CF_Gway_MemoryP2Cmd : 1|1@1+ (1.0,0.0) [0.0|1.0] ""  CLU
 SG_ CF_Gway_PBackP1Cmd : 2|1@1+ (1.0,0.0) [0.0|1.0] ""  CLU
 SG_ CF_Gway_PBackP2Cmd : 3|1@1+ (1.0,0.0) [0.0|1.0] ""  CLU
 SG_ CF_Gway_StrgWhlHeatedState : 4|1@1+ (1.0,0.0) [0.0|1.0] ""  CLU
 SG_ CF_Gway_PBackStopCmd : 5|1@1+ (1.0,0.0) [0.0|1.0] ""  CLU,HUD
 SG_ CF_Gway_StaticBendLhAct : 6|1@1+ (1.0,0.0) [0.0|1.0] ""  CLU
 SG_ CF_Gway_StaticBendRhAct : 7|1@1+ (1.0,0.0) [0.0|1.0] ""  CLU
 SG_ CF_Gway_DrvWdwStat : 8|1@1+ (1.0,0.0) [0.0|1.0] ""  CLU
 SG_ CF_Gway_RLWdwState : 9|1@1+ (1.0,0.0) [0.0|1.0] ""  CLU
 SG_ CF_Gway_RRWdwState : 10|1@1+ (1.0,0.0) [0.0|1.0] ""  CLU
 SG_ CF_Gway_AstWdwStat : 11|1@1+ (1.0,0.0) [0.0|1.0] ""  CLU
 SG_ CF_Gway_MemoryEnable : 12|1@1+ (1.0,0.0) [0.0|1.0] ""  CLU
 SG_ CF_Gway_PBACKStopCmd : 13|1@1+ (1.0,0.0) [0.0|1.0] ""  CLU
 SG_ CF_Gway_PBACKStop : 14|1@1+ (1.0,0.0) [0.0|1.0] ""  CLU,HUD
 SG_ CF_Gway_IMSBuzzer : 15|1@1+ (1.0,0.0) [0.0|1.0] ""  CLU
 SG_ CF_Gway_DrvSeatBeltInd : 36|2@1+ (1.0,0.0) [0.0|3.0] ""  CLU,Dummy
 SG_ CF_Gway_AstSeatBeltInd : 38|2@1+ (1.0,0.0) [0.0|3.0] ""  CLU
 SG_ CF_Gway_RCSeatBeltInd : 40|2@1+ (1.0,0.0) [0.0|3.0] ""  CLU
 SG_ CF_Gway_RLSeatBeltInd : 42|2@1+ (1.0,0.0) [0.0|3.0] ""  CLU
 SG_ CF_Gway_RRSeatBeltInd : 44|2@1+ (1.0,0.0) [0.0|3.0] ""  CLU
 SG_ CF_Gway_RrWiperHighSw : 46|1@1+ (1.0,0.0) [0.0|1.0] ""  CLU
 SG_ CF_Gway_RrWiperLowSw : 47|1@1+ (1.0,0.0) [0.0|1.0] ""  CLU

BO_ 1367 EngFrzFrm12: 8 EMS
 SG_ PID_06h : 0|8@1+ (0.78125,-100.0) [-100.0|99.22] "%"  AAF,IBOX,TCU
 SG_ PID_07h : 8|8@1+ (0.78125,-100.0) [-100.0|99.22] "%"  AAF,IBOX,TCU
 SG_ PID_08h : 16|8@1+ (0.78125,-100.0) [-100.0|99.22] "%"  AAF,IBOX,TCU
 SG_ PID_09h : 24|8@1+ (0.78125,-100.0) [-100.0|99.22] "%"  AAF,IBOX,TCU
 SG_ PID_0Bh : 32|8@1+ (1.0,0.0) [0.0|255.0] "kPa"  AAF,IBOX,TCU
 SG_ PID_23h : 40|16@1+ (10.0,0.0) [0.0|655350.0] "kPa"  AAF,IBOX,TCU

BO_ 1366 EngFrzFrm11: 8 EMS
 SG_ PID_04h : 0|8@1+ (0.3921568627,0.0) [0.0|100.0] "%"  AAF,TCU
 SG_ PID_05h : 8|8@1+ (1.0,-40.0) [-40.0|215.0] "deg"  AAF,TCU
 SG_ PID_0Ch : 16|16@1+ (0.25,0.0) [0.0|16383.75] "rpm"  AAF,TCU
 SG_ PID_0Dh : 32|8@1+ (1.0,0.0) [0.0|255.0] "km/h"  AAF,TCU
 SG_ PID_11h : 40|8@1+ (0.3921568627,0.0) [0.0|100.0] "%"  AAF,TCU
 SG_ PID_03h : 48|16@1+ (1.0,0.0) [0.0|65535.0] ""  AAF,TCU

BO_ 1365 FPCM11: 8 FPCM
 SG_ CR_Fpcm_LPActPre : 0|8@1+ (3.137254902,0.0) [0.0|800.0] "kPa"  EMS
 SG_ CF_Fpcm_LPPumpOverCur : 8|1@1+ (1.0,0.0) [0.0|1.0] ""  EMS
 SG_ CF_Fpcm_PreSnrHi : 9|1@1+ (1.0,0.0) [0.0|1.0] ""  EMS
 SG_ CF_Fpcm_PreSnrDisc : 10|1@1+ (1.0,0.0) [0.0|1.0] ""  EMS
 SG_ CF_Fpcm_PreSnrShort : 11|1@1+ (1.0,0.0) [0.0|1.0] ""  EMS
 SG_ CF_Fpcm_LPPumpDiscShort : 12|1@1+ (1.0,0.0) [0.0|1.0] ""  EMS
 SG_ CF_Fpcm_LP_System_Error : 13|1@1+ (1.0,0.0) [0.0|1.0] ""  EMS
 SG_ CF_Fpcm_PreSnrSigErr : 14|1@1+ (1.0,0.0) [0.0|1.0] ""  EMS
 SG_ CF_Fpcm_LPCtrCirFlt : 15|1@1+ (1.0,0.0) [0.0|1.0] ""  EMS

BO_ 871 LVR12: 8 LVR
 SG_ CF_Lvr_CruiseSet : 0|8@1+ (1.0,0.0) [0.0|255.0] "" CLU,TCU
 SG_ CF_Lvr_IsgState : 8|2@1+ (1.0,0.0) [0.0|3.0] "" CLU,TCU
 SG_ CF_Lvr_Gear : 32|4@1+ (1.0,0.0) [0.0|15.0] ""  CLU,TCU

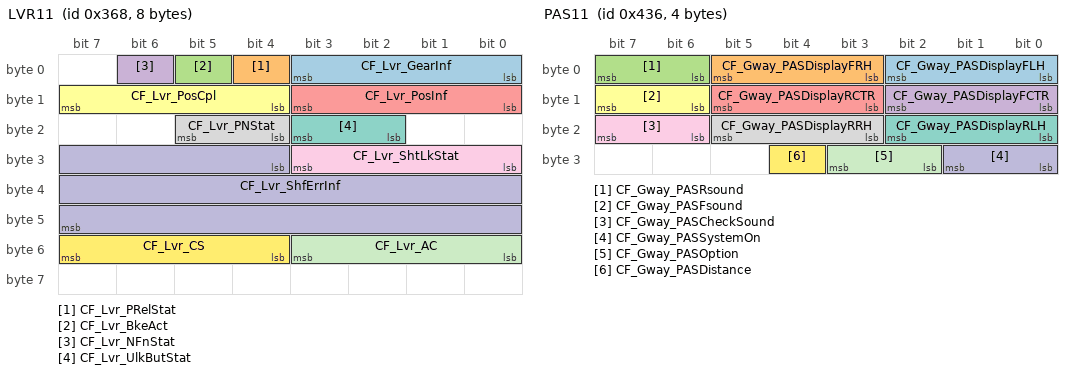
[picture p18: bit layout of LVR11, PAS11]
BO_ 872 LVR11: 8 LVR
 SG_ CF_Lvr_GearInf : 0|4@1+ (1.0,0.0) [0.0|15.0] ""  CLU,TCU
 SG_ CF_Lvr_PRelStat : 4|1@1+ (1.0,0.0) [0.0|1.0] ""  BCM,CLU,SMK,TCU
 SG_ CF_Lvr_BkeAct : 5|1@1+ (1.0,0.0) [0.0|1.0] ""  TCU
 SG_ CF_Lvr_NFnStat : 6|1@1+ (1.0,0.0) [0.0|1.0] ""  CLU
 SG_ CF_Lvr_PosInf : 8|4@1+ (1.0,0.0) [0.0|15.0] ""  TCU
 SG_ CF_Lvr_PosCpl : 12|4@1+ (1.0,0.0) [0.0|15.0] ""  TCU
 SG_ CF_Lvr_UlkButStat : 18|2@1+ (1.0,0.0) [0.0|3.0] ""  TCU
 SG_ CF_Lvr_PNStat : 20|2@1+ (1.0,0.0) [0.0|3.0] ""  CLU
 SG_ CF_Lvr_ShtLkStat : 24|4@1+ (1.0,0.0) [0.0|15.0] ""  TCU
 SG_ CF_Lvr_ShfErrInf : 28|20@1+ (1.0,0.0) [0.0|8191.0] ""  CLU,TCU
 SG_ CF_Lvr_AC : 48|4@1+ (1.0,0.0) [0.0|15.0] ""  TCU
 SG_ CF_Lvr_CS : 52|4@1+ (1.0,0.0) [0.0|15.0] ""  TCU

BO_ 1363 CGW2: 8 BCM
 SG_ CF_Gway_GwayDiagState : 0|1@1+ (1.0,0.0) [0.0|3.0] ""  CLU,Dummy
 SG_ CF_Gway_DDMDiagState : 1|1@1+ (1.0,0.0) [0.0|1.0] ""  CLU,Dummy
 SG_ CF_Gway_SCMDiagState : 2|1@1+ (1.0,0.0) [0.0|1.0] ""  CLU,Dummy
 SG_ CF_Gway_PSMDiagState : 3|1@1+ (1.0,0.0) [0.0|1.0] ""  CLU,Dummy
 SG_ CF_Gway_SJBDiagState : 4|1@1+ (1.0,0.0) [0.0|1.0] ""  CLU,Dummy
 SG_ CF_Gway_IPMDiagState : 5|1@1+ (1.0,0.0) [0.0|1.0] ""  CLU,Dummy
 SG_ CF_Gway_LDMFail : 6|2@1+ (1.0,0.0) [0.0|3.0] ""  CLU,LDWS_LKAS,LDWS_LKAS
 SG_ CF_Gway_CLUSwGuiCtrl : 10|3@1+ (1.0,0.0) [0.0|63.0] ""  CLU,Dummy
 SG_ CF_Gway_CLUSwGroup : 13|1@1+ (1.0,0.0) [0.0|1.0] ""  CLU,Dummy
 SG_ CF_Gway_CLUSwMode : 14|1@1+ (1.0,0.0) [0.0|1.0] ""  CLU,Dummy
 SG_ CF_Gway_CLUSwEnter : 15|1@1+ (1.0,0.0) [0.0|1.0] ""  CLU,Dummy
 SG_ CF_Gway_AutoLightValue : 16|1@1+ (1.0,0.0) [0.0|1.0] ""  LCA,LCA
 SG_ CF_Gway_BrakeFluidSw : 17|1@1+ (1.0,0.0) [0.0|1.0] ""  CLU,Dummy
 SG_ CF_Gway_DrvSeatBeltInd : 18|2@1+ (1.0,0.0) [0.0|3.0] ""  CLU
 SG_ CF_Gway_AvTail : 20|1@1+ (1.0,0.0) [0.0|3.0] ""  CLU,SNV,SNV
 SG_ CF_Gway_RearFogAct : 21|1@1+ (1.0,0.0) [0.0|1.0] ""  CLU,Dummy
 SG_ CF_Gway_ExtTailAct : 22|1@1+ (1.0,0.0) [0.0|1.0] ""  AVM,CLU,LCA,PGS,SPAS,AVM,LCA,PGS,SPAS
 SG_ CF_Gway_RRDrSw : 23|1@1+ (1.0,0.0) [0.0|1.0] ""  CLU,Dummy
 SG_ CF_Gway_RLDrSw : 24|1@1+ (1.0,0.0) [0.0|1.0] ""  CLU,Dummy
 SG_ CF_Gway_IntTailAct : 25|1@1+ (1.0,0.0) [0.0|1.0] ""  CLU,Dummy
 SG_ CF_Gway_CountryCfg : 26|3@1+ (1.0,0.0) [0.0|7.0] ""  AVM,CLU,PGS,Dummy
 SG_ CF_Gway_WiperParkPosition : 32|1@1+ (1.0,0.0) [0.0|1.0] ""  AFLS,EMS,LDWS_LKAS,AFLS,EMS,LDWS_LKAS
 SG_ CF_Gway_HLLowLHFail : 33|1@1+ (1.0,0.0) [0.0|1.0] ""  LDWS_LKAS,SNV,LDWS_LKAS,SNV
 SG_ CF_Gway_HLLowRHFail : 34|1@1+ (1.0,0.0) [0.0|1.0] ""  LDWS_LKAS,SNV,LDWS_LKAS,SNV
 SG_ CF_Gway_ESCLFailWarn : 35|1@1+ (1.0,0.0) [0.0|1.0] ""  CLU,Dummy
 SG_ CF_Gway_ESCLNotLockedWarn : 36|1@1+ (1.0,0.0) [0.0|1.0] ""  CLU,Dummy
 SG_ CF_Gway_ESCLNotUnlockWarn : 37|1@1+ (1.0,0.0) [0.0|1.0] ""  CLU,Dummy
 SG_ CF_Gway_IDoutWarn : 38|1@1+ (1.0,0.0) [0.0|1.0] ""  CLU,Dummy
 SG_ CF_Gway_ImmoLp : 40|1@1+ (1.0,0.0) [0.0|3.0] ""  CLU,Dummy
 SG_ CF_Gway_BCMRKEID : 41|3@1+ (1.0,0.0) [0.0|7.0] ""  CLU,Dummy
 SG_ CF_Gway_VehicleNotPWarn : 44|1@1+ (1.0,0.0) [0.0|1.0] ""  CLU,Dummy
 SG_ CF_Gway_DeactivationWarn : 45|1@1+ (1.0,0.0) [0.0|1.0] ""  CLU,Dummy
 SG_ CF_Gway_KeyBATDischargeWarn : 46|1@1+ (1.0,0.0) [0.0|1.0] ""  CLU,Dummy
 SG_ CF_Gway_SSBWarn : 47|1@1+ (1.0,0.0) [0.0|1.0] ""  CLU,Dummy
 SG_ CF_Gway_SMKFobID : 48|3@1+ (1.0,0.0) [0.0|7.0] ""  CLU,Dummy
 SG_ CF_Gway_SMKRKECmd : 51|3@1+ (1.0,0.0) [0.0|7.0] ""  CLU,Dummy
 SG_ CF_Gway_AutoLightOption : 54|1@1+ (1.0,0.0) [0.0|1.0] ""  CLU
 SG_ CF_Gway_SJBDeliveryMode : 55|1@1+ (1.0,0.0) [0.0|1.0] ""  CLU,Dummy
 SG_ CF_Gway_KeyoutLp : 56|1@1+ (1.0,0.0) [0.0|1.0] ""  CLU,Dummy
 SG_ CF_Gway_SMKDispWarn : 57|4@1+ (1.0,0.0) [0.0|15.0] ""  CLU,Dummy
 SG_ CF_Gway_WngBuz : 61|3@1+ (1.0,0.0) [0.0|7.0] ""  CLU,Dummy

BO_ 339 TCS11: 8 ESC
 SG_ TCS_REQ : 0|1@1+ (1.0,0.0) [0.0|1.0] ""  _4WD,EMS,EPB,TCU
 SG_ MSR_C_REQ : 1|1@1+ (1.0,0.0) [0.0|1.0] ""  EMS,EPB,SCC,TCU
 SG_ TCS_PAS : 2|1@1+ (1.0,0.0) [0.0|1.0] ""  _4WD,CLU,EMS,SCC,SPAS,TCU
 SG_ TCS_GSC : 3|1@1+ (1.0,0.0) [0.0|1.0] ""  _4WD,EMS,TCU
 SG_ CF_Esc_LimoInfo : 4|2@1+ (1.0,0.0) [0.0|3.0] ""  _4WD,SCC
 SG_ ABS_DIAG : 6|1@1+ (1.0,0.0) [0.0|1.0] ""  _4WD,CLU,EMS,EPB
 SG_ ABS_DEF : 7|1@1+ (1.0,0.0) [0.0|1.0] ""  _4WD,ACU,ECS,EMS,EPB,SCC,SPAS,TCU
 SG_ TCS_DEF : 8|1@1+ (1.0,0.0) [0.0|1.0] ""  _4WD,EMS,EPB,SCC,SPAS,TCU
 SG_ TCS_CTL : 9|1@1+ (1.0,0.0) [0.0|1.0] ""  _4WD,EMS,EPB,SCC,SPAS,TCU
 SG_ ABS_ACT : 10|1@1+ (1.0,0.0) [0.0|1.0] ""  _4WD,ACU,ECS,EMS,EPB,LDWS_LKAS,SCC,SPAS,TCU
 SG_ EBD_DEF : 11|1@1+ (1.0,0.0) [0.0|1.0] ""  _4WD,EMS,EPB,SPAS,TCU
 SG_ ESP_PAS : 12|1@1+ (1.0,0.0) [0.0|1.0] ""  _4WD,ACU,CLU,EMS,EPB,LDWS_LKAS,SCC,TCU
 SG_ ESP_DEF : 13|1@1+ (1.0,0.0) [0.0|1.0] ""  _4WD,ACU,ECS,EMS,EPB,LDWS_LKAS,SCC,TCU
 SG_ ESP_CTL : 14|1@1+ (1.0,0.0) [0.0|1.0] ""  _4WD,ACU,ECS,EMS,EPB,LDWS_LKAS,SCC,SPAS,TCU
 SG_ TCS_MFRN : 15|1@1+ (1.0,0.0) [0.0|1.0] ""  EMS,EPB,TCU
 SG_ DBC_CTL : 16|1@1+ (1.0,0.0) [0.0|1.0] ""  _4WD,EMS,EPB
 SG_ DBC_PAS : 17|1@1+ (1.0,0.0) [0.0|1.0] ""  _4WD,EMS,EPB
 SG_ DBC_DEF : 18|1@1+ (1.0,0.0) [0.0|1.0] ""  _4WD,EMS,EPB
 SG_ HAC_CTL : 19|1@1+ (1.0,0.0) [0.0|1.0] ""  _4WD,CLU,EMS,EPB,TCU
 SG_ HAC_PAS : 20|1@1+ (1.0,0.0) [0.0|1.0] ""  _4WD,CLU,EMS,EPB,TCU
 SG_ HAC_DEF : 21|1@1+ (1.0,0.0) [0.0|1.0] ""  _4WD,CLU,EMS,EPB,TCU
 SG_ ESS_STAT : 22|2@1+ (1.0,0.0) [0.0|3.0] ""  _4WD,BCM,CLU,EMS,EPB
 SG_ TQI_TCS : 24|8@1+ (0.390625,0.0) [0.0|99.609375] "%"  EMS,EPB,TCU
 SG_ TQI_MSR : 32|8@1+ (0.390625,0.0) [0.0|99.609375] "%"  EMS,EPB,TCU
 SG_ TQI_SLW_TCS : 40|8@1+ (0.390625,0.0) [0.0|99.609375] "%"  EMS,EPB,TCU
 SG_ CF_Esc_BrkCtl : 48|1@1+ (1.0,0.0) [0.0|1.0] ""  EMS
 SG_ BLA_CTL : 49|2@1+ (1.0,0.0) [0.0|3.0] ""  BCM,CGW,CLU
 SG_ AliveCounter_TCS1 : 52|4@1+ (1.0,0.0) [0.0|14.0] ""  EMS,EPB,LDWS_LKAS
 SG_ CheckSum_TCS1 : 56|8@1+ (1.0,0.0) [0.0|255.0] ""  EMS,EPB,LDWS_LKAS

BO_ 1362 SNV11: 4 SNV
 SG_ CF_SNV_DisplayControl : 0|2@1+ (1.0,0.0) [0.0|3.0] ""  CLU,HUD
 SG_ CF_Snv_BeepWarning : 2|2@1+ (1.0,0.0) [0.0|3.0] ""  CLU,HUD
 SG_ CF_Snv_WarningMessage : 4|3@1+ (1.0,0.0) [0.0|7.0] ""  CLU,HUD
 SG_ CF_Snv_DetectionEnable : 7|1@1+ (1.0,0.0) [0.0|1.0] ""  BCM,CLU,HUD
 SG_ CF_Snv_PedestrianDetect : 8|2@1+ (1.0,0.0) [0.0|3.0] ""  BCM,CLU,HUD
 SG_ CF_Snv_IRLampControl : 10|2@1+ (1.0,0.0) [0.0|3.0] ""  BCM,CLU,HUD

BO_ 1360 IAP11: 3 IAP
 SG_ CF_Iap_EcoPmodSwi : 0|1@1+ (1.0,0.0) [0.0|1.0] ""  CLU
 SG_ CF_Iap_EcoPmodAct : 1|1@1+ (1.0,0.0) [0.0|1.0] ""  CLU
 SG_ CF_Iap_ReqWarn : 2|2@1+ (1.0,0.0) [0.0|3.0] ""  CLU

BO_ 1356 TCU_DCT14: 8 TCU
 SG_ Vehicle_Stop_Time : 0|5@1+ (1.0,0.0) [0.0|0.0] ""  CLU
 SG_ HILL_HOLD_WARNING : 5|1@1+ (1.0,0.0) [0.0|0.0] ""  CLU

BO_ 1353 BAT11: 8 EMS
 SG_ BAT_SNSR_I : 0|16@1+ (0.01,-327.0) [-327.0|328.0] "A"  CGW,CUBIS,IBOX,TMU
 SG_ BAT_SOC : 16|8@1+ (1.0,0.0) [0.0|100.0] "%"  CGW,CUBIS,IBOX,TMU
 SG_ BAT_SNSR_V : 24|14@1+ (0.0010,6.0) [6.0|18.0] "V"  CGW,CUBIS,IBOX,TMU
 SG_ BAT_SNSR_Temp : 38|9@1- (0.5,-40.0) [-40.0|125.0] "deg"  CGW,CUBIS,IBOX,TMU
 SG_ BAT_SNSR_State : 47|1@1+ (1.0,0.0) [0.0|1.0] ""  CGW,CUBIS,IBOX,TMU
 SG_ BAT_SOH : 48|7@1+ (1.0,0.0) [0.0|100.0] "%"  CGW,CUBIS,IBOX,TMU
 SG_ BAT_SNSR_Invalid : 55|1@1+ (1.0,0.0) [0.0|1.0] ""  CGW,CUBIS,IBOX,TMU
 SG_ BAT_SOF : 56|7@1+ (0.1,0.0) [0.0|12.0] "V"  CGW,CUBIS,IBOX,TMU
 SG_ BAT_SNSR_Error : 63|1@1+ (1.0,0.0) [0.0|1.0] ""  CGW,CUBIS,IBOX,TMU

BO_ 1351 EMS15: 8 EMS
 SG_ ECGPOvrd : 0|1@1+ (1.0,0.0) [0.0|1.0] ""  ESC,IBOX,SCC
 SG_ QECACC : 1|1@1+ (1.0,0.0) [0.0|1.0] ""  ESC,IBOX
 SG_ ECFail : 2|1@1+ (1.0,0.0) [0.0|1.0] ""  ESC,IBOX
 SG_ SwitchOffCondExt : 3|1@1+ (1.0,0.0) [0.0|1.0] ""  ESC,IBOX
 SG_ BLECFail : 4|1@1+ (1.0,0.0) [0.0|1.0] ""  ESC,IBOX
 SG_ CF_Ems_IsaAct : 5|1@1+ (1.0,0.0) [0.0|1.0] ""  CLU
 SG_ FA_PV_CAN : 8|8@1+ (0.3906,0.0) [0.0|99.2] "%"  IBOX,LDWS_LKAS,TCU
 SG_ IntAirTemp : 16|8@1+ (0.75,-48.0) [-48.0|143.25] "deg"  _4WD,ECS,EPB,IBOX,TCU
 SG_ STATE_DC_OBD : 24|7@1+ (1.0,0.0) [0.0|127.0] ""  IBOX,TCU
 SG_ INH_DC_OBD : 31|1@1+ (1.0,0.0) [0.0|1.0] ""  IBOX,TCU
 SG_ CTR_IG_CYC_OBD : 32|16@1+ (1.0,0.0) [0.0|65535.0] ""  ACU,IBOX,TCU
 SG_ CTR_CDN_OBD : 48|16@1+ (1.0,0.0) [0.0|65535.0] ""  IBOX,TCU

BO_ 1350 DI_BOX12: 8 DI_BOX
 SG_ CF_DiBox_FrtInjVDiagReg0 : 0|8@1+ (1.0,0.0) [0.0|255.0] ""  EMS
 SG_ CF_DiBox_FrtInjVDiagReg1 : 8|8@1+ (1.0,0.0) [0.0|255.0] ""  EMS
 SG_ CF_DiBox_FrtInjVDiagReg2 : 16|8@1+ (1.0,0.0) [0.0|255.0] ""  EMS
 SG_ CF_DiBox_SedInjVDiagReg0 : 24|8@1+ (1.0,0.0) [0.0|255.0] ""  EMS
 SG_ CF_DiBox_SedInjVDiagReg1 : 32|8@1+ (1.0,0.0) [0.0|255.0] ""  EMS
 SG_ CF_DiBox_SedInjVDiagReg2 : 40|8@1+ (1.0,0.0) [0.0|255.0] ""  EMS
 SG_ CR_DiBox_BatVol : 48|8@1+ (0.1,0.0) [0.0|25.5] "V"  EMS
 SG_ CF_DiBox_SedInjVChg : 56|1@1+ (1.0,0.0) [0.0|1.0] ""  EMS
 SG_ CF_DiBox_FrtInjVChg : 57|1@1+ (1.0,0.0) [0.0|1.0] ""  EMS
 SG_ CF_DiBox_SedInjVErrSPI : 58|1@1+ (1.0,0.0) [0.0|1.0] ""  EMS
 SG_ CF_DiBox_FrtInjVErrSPI : 59|1@1+ (1.0,0.0) [0.0|1.0] ""  EMS

BO_ 1349 EMS14: 8 EMS
 SG_ IMMO_LAMP_STAT : 0|1@1+ (1.0,0.0) [0.0|1.0] ""  CLU,IBOX
 SG_ L_MIL : 1|1@1+ (1.0,0.0) [0.0|1.0] ""  CLU,CUBIS,IBOX
 SG_ IM_STAT : 2|1@1+ (1.0,0.0) [0.0|1.0] ""  CLU,IBOX
 SG_ AMP_CAN : 3|5@1+ (10.731613,458.98) [458.98|791.660003] "mmHg"  CLU,IBOX,TCU,TPMS
 SG_ BAT_Alt_FR_Duty : 8|8@1+ (0.4,0.0) [0.0|100.0] "%"  CGW,CUBIS,IBOX,TMU
 SG_ VB : 24|8@1+ (0.1015625,0.0) [0.0|25.8984375] "V"  CLU,CUBIS,DATC,EPB,FPCM,IBOX
 SG_ EMS_VS : 32|12@1+ (0.0625,0.0) [0.0|255.875] "km/h"  CLU
 SG_ TEMP_FUEL : 56|8@1+ (0.75,-48.0) [-48.0|143.25] "deg"  FPCM

BO_ 68 DATC11: 8 DATC
 SG_ CF_Datc_Type : 0|8@1+ (1.0,0.0) [0.0|255.0] ""  CLU
 SG_ CF_Datc_VerMaj : 8|8@1+ (1.0,0.0) [0.0|255.0] ""  CLU
 SG_ CF_Datc_VerMin : 16|8@1+ (1.0,0.0) [0.0|255.0] ""  CLU
 SG_ CR_Datc_OutTempC : 24|8@1+ (0.5,-41.0) [-41.0|86.5] "deg"  CLU,FPCM
 SG_ CR_Datc_OutTempF : 32|8@1+ (1.0,-42.0) [-42.0|213.0] "deg"  CLU
 SG_ CF_Datc_IncarTemp : 40|8@1+ (0.5,-40.0) [-40.0|60.0] "deg"  BCM,CLU

BO_ 67 DATC13: 8 DATC
 SG_ CF_Datc_TempDispUnit : 0|2@1+ (1.0,0.0) [0.0|3.0] ""  CLU,IBOX
 SG_ CF_Datc_ModDisp : 2|4@1+ (1.0,0.0) [0.0|15.0] ""  CLU
 SG_ CF_Datc_IonClean : 6|2@1+ (1.0,0.0) [0.0|3.0] ""  CLU
 SG_ CF_Datc_ChgReqDisp : 8|2@1+ (1.0,0.0) [0.0|3.0] ""  CLU
 SG_ CF_Datc_IntakeDisp : 10|2@1+ (1.0,0.0) [0.0|3.0] ""  CLU
 SG_ CF_Datc_AutoDisp : 12|2@1+ (1.0,0.0) [0.0|3.0] ""  CLU
 SG_ CF_Datc_FrDefLed : 14|2@1+ (1.0,0.0) [0.0|3.0] ""  CLU,IBOX
 SG_ CF_Datc_AutoDefogBlink : 16|2@1+ (1.0,0.0) [0.0|3.0] ""  CLU
 SG_ CF_Datc_ClmScanDisp : 18|2@1+ (1.0,0.0) [0.0|3.0] ""  CLU
 SG_ CF_Datc_AqsDisp : 20|2@1+ (1.0,0.0) [0.0|3.0] ""  CLU
 SG_ CF_Datc_AcDisp : 22|2@1+ (1.0,0.0) [0.0|3.0] ""  CLU
 SG_ CF_Datc_OpSts : 25|3@1+ (1.0,0.0) [0.0|7.0] ""  CLU
 SG_ CF_Mtc_MaxAcDisp : 28|2@1+ (1.0,0.0) [0.0|3.0] ""  CLU
 SG_ CF_Datc_DualDisp : 30|2@1+ (1.0,0.0) [0.0|3.0] ""  CLU
 SG_ CF_Datc_PwrInf : 32|4@1+ (1.0,0.0) [0.0|15.0] ""  CLU
 SG_ CF_Datc_RearManual : 38|2@1+ (1.0,0.0) [0.0|3.0] ""  CLU
 SG_ CF_Datc_RearAutoDisp : 40|2@1+ (1.0,0.0) [0.0|1.0] ""  CLU
 SG_ CF_Datc_RearOffDisp : 42|2@1+ (1.0,0.0) [0.0|3.0] ""  CLU
 SG_ CF_Datc_RearClimateScnDisp : 44|2@1+ (1.0,0.0) [0.0|3.0] ""  CLU
 SG_ CF_Datc_RearChgReqDisp : 46|2@1+ (1.0,0.0) [0.0|3.0] ""  CLU
 SG_ CF_Datc_RearModDisp : 48|4@1+ (1.0,0.0) [0.0|15.0] ""  CLU
 SG_ CF_Datc_RearBlwDisp : 52|4@1+ (1.0,0.0) [0.0|15.0] ""  CLU
 SG_ CF_Datc_PSModDisp : 56|4@1+ (1.0,0.0) [0.0|15.0] ""  CLU
 SG_ CF_Datc_FrontBlwDisp : 60|4@1+ (1.0,0.0) [0.0|15.0] ""  CLU,IBOX

BO_ 66 DATC12: 8 DATC
 SG_ CR_Datc_DrTempDispC : 0|8@1+ (0.5,14.0) [15.0|32.0] "deg"  CLU,IBOX
 SG_ CR_Datc_DrTempDispF : 8|8@1+ (1.0,56.0) [58.0|90.0] "deg"  CLU,IBOX
 SG_ CR_Datc_PsTempDispC : 16|8@1+ (0.5,14.0) [15.0|32.0] "deg"  CLU,IBOX
 SG_ CR_Datc_PsTempDispF : 24|8@1+ (1.0,56.0) [58.0|90.0] "deg"  CLU,IBOX
 SG_ CR_Datc_RearDrTempDispC : 40|8@1+ (0.5,14.0) [15.0|32.0] "deg"  CLU
 SG_ CR_Datc_RearDrTempDispF : 48|8@1+ (1.0,58.0) [58.0|90.0] "deg"  CLU
 SG_ CF_Datc_CO2_Warning : 56|8@1+ (1.0,0.0) [0.0|3.0] ""  CLU

BO_ 1345 CGW1: 8 BCM
 SG_ CF_Gway_IGNSw : 0|3@1+ (1.0,0.0) [0.0|7.0] ""  AVM,CLU,ECS,EMS,EPB,ESC,IBOX,LVR,MDPS,SAS,SCC,ECS,EMS,EPB,ESC,IBOX,LVR,MDPS,SAS,SCC
 SG_ CF_Gway_RKECmd : 3|3@1+ (1.0,0.0) [0.0|7.0] ""  CLU,ECS,EMS,IBOX,ECS,EMS,IBOX
 SG_ CF_Gway_DrvKeyLockSw : 6|1@1+ (1.0,0.0) [0.0|1.0] ""  ECS,EMS,IBOX,ECS,EMS,IBOX
 SG_ CF_Gway_DrvKeyUnlockSw : 7|1@1+ (1.0,0.0) [0.0|1.0] ""  ECS,EMS,IBOX,ECS,EMS,IBOX
 SG_ CF_Gway_DrvDrSw : 8|2@1+ (1.0,0.0) [0.0|3.0] ""  CLU,ECS,EMS,EPB,ESC,IBOX,SCC,TCU,ECS,EMS,EPB,ESC,IBOX,SCC,TCU
 SG_ CF_Gway_DrvSeatBeltSw : 10|2@1+ (1.0,0.0) [0.0|3.0] ""  EMS,EPB,ESC,IBOX,PSB,TCU,EMS,EPB,ESC,IBOX,PSB,TCU
 SG_ CF_Gway_TrunkTgSw : 12|2@1+ (1.0,0.0) [0.0|3.0] ""  CLU,ECS,EMS,EPB,ESC,IBOX,ECS,EMS,EPB,ESC,IBOX
 SG_ CF_Gway_AstSeatBeltSw : 14|2@1+ (1.0,0.0) [0.0|3.0] ""  IBOX,PSB,IBOX,PSB
 SG_ CF_Gway_SMKOption : 16|1@1+ (1.0,0.0) [0.0|1.0] ""  CLU,EMS,IBOX,EMS,IBOX,SMK
 SG_ CF_Gway_HoodSw : 17|2@1+ (1.0,0.0) [0.0|3.0] ""  CLU,EMS,EPB,ESC,IBOX,EMS,EPB,ESC,IBOX
 SG_ CF_Gway_TurnSigLh : 19|2@1+ (1.0,0.0) [0.0|3.0] ""  CLU,EMS,IBOX,LCA,LDWS_LKAS,SCC,EMS,IBOX,LCA,LDWS_LKAS,SCC
 SG_ CF_Gway_WiperIntT : 21|3@1+ (1.0,0.0) [0.0|7.0] ""  CLU,EMS,IBOX,LDWS_LKAS,EMS,ESC,IBOX,LDWS_LKAS
 SG_ CF_Gway_WiperIntSw : 24|1@1+ (1.0,0.0) [0.0|1.0] ""  CLU,EMS,IBOX,LDWS_LKAS,EMS,ESC,IBOX,LDWS_LKAS
 SG_ CF_Gway_WiperLowSw : 25|1@1+ (1.0,0.0) [0.0|1.0] ""  CLU,EMS,IBOX,LDWS_LKAS,EMS,ESC,IBOX,LDWS_LKAS
 SG_ CF_Gway_WiperHighSw : 26|1@1+ (1.0,0.0) [0.0|1.0] ""  CLU,EMS,IBOX,LDWS_LKAS,EMS,ESC,IBOX,LDWS_LKAS
 SG_ CF_Gway_WiperAutoSw : 27|1@1+ (1.0,0.0) [0.0|1.0] ""  CLU,EMS,IBOX,LDWS_LKAS,EMS,ESC,IBOX,LDWS_LKAS
 SG_ CF_Gway_RainSnsState : 28|3@1+ (1.0,0.0) [0.0|7.0] ""  AFLS,EMS,IBOX,LDWS_LKAS,AFLS,EMS,ESC,IBOX,LDWS_LKAS
 SG_ CF_Gway_HeadLampLow : 31|1@1+ (1.0,0.0) [0.0|1.0] ""  AFLS,CLU,EMS,IBOX,LDWS_LKAS,SNV,AFLS,EMS,IBOX,LDWS_LKAS,SNV
 SG_ CF_Gway_HeadLampHigh : 32|1@1+ (1.0,0.0) [0.0|1.0] ""  AFLS,CLU,EMS,IBOX,LDWS_LKAS,AFLS,EMS,IBOX,LDWS_LKAS
 SG_ CF_Gway_HazardSw : 33|2@1+ (1.0,0.0) [0.0|3.0] ""  ABS,EMS,ESC,IBOX,LCA,LDWS_LKAS,ABS,EMS,ESC,IBOX,LCA,LDWS_LKAS
 SG_ CF_Gway_AstDrSw : 35|1@1+ (1.0,0.0) [0.0|1.0] ""  CLU,IBOX,IBOX
 SG_ CF_Gway_DefoggerRly : 36|1@1+ (1.0,0.0) [0.0|1.0] ""  EMS,IBOX,EMS,IBOX
 SG_ CF_Gway_ALightStat : 37|1@1+ (1.0,0.0) [0.0|1.0] ""  AFLS,IBOX,LDWS_LKAS,AFLS,IBOX,LDWS_LKAS
 SG_ CF_Gway_LightSwState : 38|2@1+ (1.0,0.0) [0.0|3.0] ""  AFLS,IBOX,LDWS_LKAS,AFLS,IBOX,LDWS_LKAS
 SG_ CF_Gway_Frt_Fog_Act : 40|1@1+ (1.0,0.0) [0.0|1.0] ""  AFLS,CLU,IBOX,LDWS_LKAS,AFLS,IBOX,LDWS_LKAS
 SG_ CF_Gway_TSigRHSw : 41|1@1+ (1.0,0.0) [0.0|1.0] ""  IBOX,LDWS_LKAS,IBOX,LDWS_LKAS
 SG_ CF_Gway_TSigLHSw : 42|1@1+ (1.0,0.0) [0.0|1.0] ""  IBOX,LDWS_LKAS,IBOX,LDWS_LKAS
 SG_ CF_Gway_DriveTypeOption : 43|1@1+ (1.0,0.0) [0.0|1.0] ""  CLU,IBOX,LDWS_LKAS,IBOX,LDWS_LKAS
 SG_ CF_Gway_StarterRlyState : 44|1@1+ (1.0,0.0) [0.0|1.0] ""  EMS,IBOX,EMS,IBOX,SMK
 SG_ CF_Gway_PassiveAccessLock : 45|2@1+ (1.0,0.0) [0.0|7.0] ""  CLU,ECS,EMS,IBOX,ECS,EMS,IBOX,SMK
 SG_ CF_Gway_WiperMistSw : 47|1@1+ (1.0,0.0) [0.0|1.0] ""  CLU,EMS,IBOX,LDWS_LKAS
 SG_ CF_Gway_PassiveAccessUnlock : 48|2@1+ (1.0,0.0) [0.0|7.0] ""  CLU,ECS,EMS,IBOX,ECS,EMS,IBOX,SMK
 SG_ CF_Gway_RrSunRoofOpenState : 50|1@1+ (1.0,0.0) [0.0|1.0] ""  CLU,DATC,IBOX
 SG_ CF_Gway_PassingSW : 51|1@1+ (1.0,0.0) [0.0|1.0] ""  AFLS,IBOX,LDWS_LKAS,AFLS,IBOX,LDWS_LKAS
 SG_ CF_Gway_HBAControlMode : 52|1@1+ (1.0,0.0) [0.0|1.0] ""  IBOX,LDWS_LKAS,IBOX,LDWS_LKAS
 SG_ CF_Gway_HLpHighSw : 53|1@1+ (1.0,0.0) [0.0|1.0] ""  IBOX,LDWS_LKAS,IBOX,LDWS_LKAS
 SG_ CF_Gway_InhibitRMT : 54|2@1+ (1.0,0.0) [0.0|3.0] ""  EMS,EPB,ESC,IBOX,LCA,LDWS_LKAS,MDPS,PGS,SCC,SPAS,TPMS,EPB,ESC,IBOX,LCA,LDWS_LKAS,PGS,SCC,SPAS,TPMS
 SG_ CF_Gway_RainSnsOption : 56|1@1+ (1.0,0.0) [0.0|1.0] ""  CLU
 SG_ C_SunRoofOpenState : 57|1@1+ (1.0,0.0) [0.0|1.0] ""  CLU,DATC,IBOX,DATC,IBOX
 SG_ CF_Gway_Ign1 : 58|1@1+ (1.0,0.0) [0.0|1.0] ""  CLU
 SG_ CF_Gway_Ign2 : 59|1@1+ (1.0,0.0) [0.0|1.0] ""  CLU
 SG_ CF_Gway_ParkBrakeSw : 60|2@1+ (1.0,0.0) [0.0|3.0] ""  CLU,ESC,IBOX,SCC,ESC,IBOX,SCC
 SG_ CF_Gway_TurnSigRh : 62|2@1+ (1.0,0.0) [0.0|3.0] ""  CLU,EMS,IBOX,LCA,LDWS_LKAS,SCC,EMS,IBOX,LCA,LDWS_LKAS,SCC

BO_ 832 LKAS11: 8 LDWS_LKAS
 SG_ CF_Lkas_LdwsActivemode : 0|2@1+ (1,0) [0|3] "" CLU,IBOX,PSB
 SG_ CF_Lkas_LdwsSysState : 2|4@1+ (1.0,0.0) [0.0|15.0] ""  CLU,IBOX,PSB
 SG_ CF_Lkas_SysWarning : 6|4@1+ (1.0,0.0) [0.0|15.0] ""  BCM,CLU
 SG_ CF_Lkas_LdwsLHWarning : 10|2@1+ (1.0,0.0) [0.0|3.0] ""  BCM,CLU,PSB
 SG_ CF_Lkas_LdwsRHWarning : 12|2@1+ (1.0,0.0) [0.0|3.0] ""  BCM,CLU,PSB
 SG_ CF_Lkas_HbaLamp : 14|1@1+ (1.0,0.0) [0.0|1.0] ""  CLU
 SG_ CF_Lkas_FcwBasReq : 15|1@1+ (1.0,0.0) [0.0|1.0] ""  ABS,ESC
 SG_ CR_Lkas_StrToqReq : 16|11@1+ (1.0,-1024.0) [-1024.0|1024.0] ""  MDPS
 SG_ CF_Lkas_ActToi : 27|1@1+ (1.0,0.0) [0.0|1.0] ""  MDPS
 SG_ CF_Lkas_ToiFlt : 28|1@1+ (1.0,0.0) [0.0|1.0] ""  MDPS
 SG_ CF_Lkas_HbaSysState : 29|3@1+ (1.0,0.0) [0.0|7.0] ""  BCM,CLU
 SG_ CF_Lkas_FcwOpt : 32|2@1+ (1.0,0.0) [0.0|3.0] ""  CLU
 SG_ CF_Lkas_HbaOpt : 34|2@1+ (1.0,0.0) [0.0|1.0] ""  BCM,CGW
 SG_ CF_Lkas_MsgCount : 36|4@1+ (1.0,0.0) [0.0|15.0] ""  CLU,MDPS
 SG_ CF_Lkas_FcwSysState : 40|3@1+ (1.0,0.0) [0.0|7.0] ""  CLU
 SG_ CF_Lkas_FcwCollisionWarning : 43|2@1+ (1.0,0.0) [0.0|3.0] ""  CLU
 SG_ CF_Lkas_FusionState : 45|2@1+ (1.0,0.0) [0.0|3.0] ""  SCC
 SG_ CF_Lkas_Unknown1 : 47|1@1+ (1.0,0.0) [0.0|1.0] "" XXX
 SG_ CF_Lkas_Chksum : 48|8@1+ (1.0,0.0) [0.0|255.0] ""  MDPS
 SG_ CF_Lkas_FcwOpt_USM : 56|3@1+ (1.0,0.0) [0.0|7.0] ""  CLU
 SG_ CF_Lkas_LdwsOpt_USM : 59|3@1+ (1.0,0.0) [0.0|7.0] ""  CLU,MDPS
 SG_ CF_Lkas_Unknown2 : 62|2@1+ (1.0,0.0) [0.0|1.0] "" XXX

BO_ 1342 LKAS12: 6 LDWS_LKAS
 SG_ CF_Lkas_TsrSlifOpt : 10|2@1+ (1.0,0.0) [0.0|3.0] ""  CLU
 SG_ CF_LkasTsrStatus : 12|2@1+ (1.0,0.0) [0.0|3.0] ""  CLU
 SG_ CF_Lkas_TsrSpeed_Display_Clu : 16|8@1+ (1.0,0.0) [0.0|255.0] ""  CLU
 SG_ CF_LkasTsrSpeed_Display_Navi : 24|8@1+ (1.0,0.0) [0.0|255.0] ""  BCM,CLU
 SG_ CF_Lkas_TsrAddinfo_Display : 32|2@1+ (1.0,0.0) [0.0|3.0] ""  CLU
 SG_ CF_LkasDawStatus : 40|3@1+ (1,0) [0|7] "" CLU
 SG_ CF_Lkas_Daw_USM : 37|3@1+ (1,0) [0|7] "" CLU

BO_ 1338 TMU_GW_E_01: 8 CLU
 SG_ CF_Gway_TeleReqDrLock : 0|2@1+ (1.0,0.0) [0.0|3.0] ""  BCM
 SG_ CF_Gway_TeleReqDrUnlock : 2|2@1+ (1.0,0.0) [0.0|3.0] ""  BCM
 SG_ CF_Gway_TeleReqHazard : 4|2@1+ (1.0,0.0) [0.0|3.0] ""  BCM
 SG_ CF_Gway_TeleReqHorn : 6|2@1+ (1.0,0.0) [0.0|3.0] ""  BCM
 SG_ CF_Gway_TeleReqEngineOperate : 8|2@1+ (1.0,0.0) [0.0|3.0] ""  BCM

BO_ 1078 PAS11: 4 BCM
 SG_ CF_Gway_PASDisplayFLH : 0|3@1+ (1.0,0.0) [0.0|7.0] ""  AVM,CLU,AVM
 SG_ CF_Gway_PASDisplayFRH : 3|3@1+ (1.0,0.0) [0.0|7.0] ""  AVM,CLU,AVM
 SG_ CF_Gway_PASRsound : 6|2@1+ (1.0,0.0) [0.0|3.0] ""  CLU,Dummy
 SG_ CF_Gway_PASDisplayFCTR : 8|3@1+ (1.0,0.0) [0.0|7.0] ""  AVM,CLU,AVM
 SG_ CF_Gway_PASDisplayRCTR : 11|3@1+ (1.0,0.0) [0.0|7.0] ""  AVM,CLU,PGS,AVM
 SG_ CF_Gway_PASFsound : 14|2@1+ (1.0,0.0) [0.0|3.0] ""  CLU,Dummy
 SG_ CF_Gway_PASDisplayRLH : 16|3@1+ (1.0,0.0) [0.0|7.0] ""  AVM,CLU,PGS,AVM
 SG_ CF_Gway_PASDisplayRRH : 19|3@1+ (1.0,0.0) [0.0|7.0] ""  AVM,CLU,PGS,AVM
 SG_ CF_Gway_PASCheckSound : 22|2@1+ (1.0,0.0) [0.0|3.0] ""  CLU,Dummy
 SG_ CF_Gway_PASSystemOn : 24|2@1+ (1.0,0.0) [0.0|3.0] ""  CLU,Dummy
 SG_ CF_Gway_PASOption : 26|2@1+ (1.0,0.0) [0.0|3.0] ""  CLU
 SG_ CF_Gway_PASDistance : 28|1@1+ (1.0,0.0) [0.0|1.0] ""  CLU

BO_ 48 EMS18: 6 EMS
 SG_ CF_Ems_DC1NumPerMSV : 0|8@1+ (1.0,0.0) [0.0|255.0] ""  DI_BOX
 SG_ CF_Ems_DC2NumPerMSV : 8|16@1+ (1.0,0.0) [0.0|65535.0] ""  DI_BOX
 SG_ CR_Ems_DutyCyc1MSV : 24|8@1+ (0.1953,0.0) [0.0|49.8] "%"  DI_BOX
 SG_ CR_Ems_DutyCyc2MSV : 32|8@1+ (0.13725,0.0) [0.0|35.0] "%"  DI_BOX
 SG_ CR_Ems_DutyCyc3MSV : 40|8@1+ (0.392,0.0) [0.0|100.0] "%"  DI_BOX

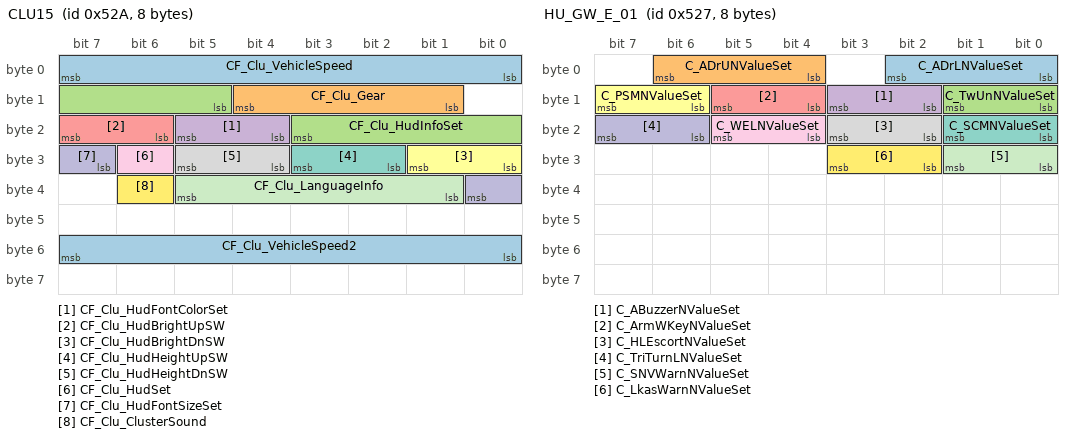
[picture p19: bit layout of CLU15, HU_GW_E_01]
BO_ 1322 CLU15: 8 CLU
 SG_ CF_Clu_VehicleSpeed : 0|8@1+ (1.0,0.0) [0.0|255.0] ""  BCM
 SG_ CF_Clu_Gear : 9|4@1+ (1,0) [0|15] "" BCM
 SG_ CF_Clu_HudInfoSet : 13|7@1+ (1.0,0.0) [0.0|127.0] ""  HUD
 SG_ CF_Clu_HudFontColorSet : 20|2@1+ (1.0,0.0) [0.0|3.0] ""  HUD
 SG_ CF_Clu_HudBrightUpSW : 22|2@1+ (1.0,0.0) [0.0|3.0] ""  HUD
 SG_ CF_Clu_HudBrightDnSW : 24|2@1+ (1.0,0.0) [0.0|3.0] ""  HUD
 SG_ CF_Clu_HudHeightUpSW : 26|2@1+ (1.0,0.0) [0.0|3.0] ""  HUD
 SG_ CF_Clu_HudHeightDnSW : 28|2@1+ (1.0,0.0) [0.0|3.0] ""  HUD
 SG_ CF_Clu_HudSet : 30|1@1+ (1.0,0.0) [0.0|1.0] ""  HUD
 SG_ CF_Clu_HudFontSizeSet : 31|2@1+ (1.0,0.0) [0.0|3.0] ""  HUD
 SG_ CF_Clu_LanguageInfo : 33|5@1+ (1.0,0.0) [0.0|31.0] ""  BCM,PGS
 SG_ CF_Clu_ClusterSound : 38|1@1- (1.0,0.0) [0.0|0.0] ""  BCM,CGW,FATC
 SG_ CF_Clu_VehicleSpeed2 : 48|8@1+ (1,0) [0|255] "" XXX

BO_ 1066 _4WD13: 6 _4WD
 SG_ _4WD_CURRENT : 0|8@1+ (0.390625,0.0) [-50.0|50.0] "A"  TCU
 SG_ _4WD_POSITION : 8|16@1+ (0.015625,0.0) [-180.0|180.0] "Deg"  TCU
 SG_ _4WD_CLU_THERM_STR : 24|8@1+ (1.0,0.0) [0.0|100.0] "%"  TCU
 SG_ _4WD_STATUS : 32|8@1+ (1.0,0.0) [0.0|15.0] ""  ESC,TCU

BO_ 1065 _4WD12: 8 _4WD
 SG_ Ster_Pos : 0|16@1+ (1.0,-600.0) [-600.0|600.0] "Deg"  ESC
 SG_ FRSS : 16|8@1+ (1.0,0.0) [0.0|254.0] "km/h"  ESC
 SG_ FLSS : 24|8@1+ (1.0,0.0) [0.0|254.0] "km/h"  ESC
 SG_ RRSS : 32|8@1+ (1.0,0.0) [0.0|254.0] "km/h"  ESC
 SG_ RLSS : 40|8@1+ (1.0,0.0) [0.0|254.0] "km/h"  ESC
 SG_ CLU_PRES : 48|16@1+ (0.0625,-50.0) [-50.0|50.0] "Bar"  ESC

BO_ 809 EMS12: 8 EMS
 SG_ CONF_TCU m1 : 0|6@1+ (1.0,0.0) [0.0|63.0] ""  _4WD,ACU,BCM,CLU,DATC,EPB,ESC,IBOX,LCA,SMK
 SG_ CAN_VERS m0 : 0|6@1+ (1.0,0.0) [0.0|7.7] ""  _4WD,ABS,ESC,IBOX
 SG_ TQ_STND m3 : 0|6@1+ (10.0,0.0) [0.0|630.0] "Nm"  _4WD,DATC,ECS,EPB,ESC,FATC,IBOX
 SG_ OBD_FRF_ACK m2 : 0|6@1+ (1.0,0.0) [0.0|63.0] ""  _4WD,ESC,IBOX
 SG_ MUL_CODE M : 6|2@1+ (1.0,0.0) [0.0|3.0] ""  _4WD,ABS,ACU,BCM,CLU,DATC,ECS,EPB,ESC,IBOX,LCA,SMK,TCU
 SG_ TEMP_ENG : 8|8@1+ (0.75,-48.0) [-48.0|143.25] "deg"  _4WD,BCM,CLU,DATC,EPB,ESC,IBOX,SMK,TCU
 SG_ MAF_FAC_ALTI_MMV : 16|8@1+ (0.00781,0.0) [0.0|1.99155] ""  IBOX,TCU
 SG_ VB_OFF_ACT : 24|1@1+ (1.0,0.0) [0.0|1.0] ""  IBOX,TCU
 SG_ ACK_ES : 25|1@1+ (1.0,0.0) [0.0|1.0] ""  _4WD,ACU,IBOX
 SG_ CONF_MIL_FMY : 26|3@1+ (1.0,0.0) [0.0|7.0] ""  ESC,IBOX,TCU
 SG_ OD_OFF_REQ : 29|1@1+ (1.0,0.0) [0.0|1.0] ""  IBOX,TCU
 SG_ ACC_ACT : 30|1@1+ (1.0,0.0) [0.0|1.0] ""  _4WD,ABS,CLU,ESC,IAP,IBOX,SCC,TCU
 SG_ CLU_ACK : 31|1@1+ (1.0,0.0) [0.0|1.0] ""  _4WD,EPB,ESC,IBOX
 SG_ BRAKE_ACT : 32|2@1+ (1.0,0.0) [0.0|3.0] ""  _4WD,ABS,ACU,AFLS,CLU,DATC,ECS,EPB,ESC,IBOX,LDWS_LKAS,TCU
 SG_ ENG_CHR : 34|4@1+ (1.0,0.0) [0.0|15.0] ""  _4WD,ABS,ACU,CLU,DATC,EPB,ESC,FATC,IBOX,SCC,SMK,TCU
 SG_ GP_CTL : 38|2@1+ (1.0,0.0) [0.0|3.0] ""  IBOX
 SG_ TPS : 40|8@1+ (0.4694836,-15.0234742) [-15.0234742|104.6948357] "%"  _4WD,ABS,ACU,CLU,DATC,ECS,EPB,ESC,IBOX,TCU
 SG_ PV_AV_CAN : 48|8@1+ (0.3906,0.0) [0.0|99.603] "%"  _4WD,AAF,ABS,ACU,AFLS,CLU,DATC,EPB,ESC,IAP,IBOX,LDWS_LKAS,SCC,TCU
 SG_ ENG_VOL : 56|8@1+ (0.1,0.0) [0.0|25.5] "liter"  _4WD,ABS,ACU,BCM,CLU,DATC,EPB,ESC,IBOX,LDWS_LKAS,SCC,SMK

BO_ 1064 _4WD11: 8 _4WD
 SG_ _4WD_TYPE : 0|2@1+ (1.0,0.0) [0.0|3.0] ""  ACU,ESC,TPMS
 SG_ _4WD_SUPPORT : 2|2@1+ (1.0,0.0) [0.0|3.0] ""  ABS,ESC,TPMS
 SG_ _4WD_ERR : 8|8@1+ (1.0,0.0) [0.0|255.0] ""  CLU,ESC
 SG_ CLU_DUTY : 16|8@1+ (1.0,0.0) [0.0|64.0] "%"  ABS,ESC
 SG_ R_TIRE : 24|8@1+ (1.0,200.0) [200.0|455.0] "mm"  ABS,ESC,TPMS
 SG_ _4WD_SW : 32|8@1+ (1.0,0.0) [0.0|9.9] ""  ESC
 SG_ _2H_ACT : 40|1@1+ (1.0,0.0) [0.0|1.0] ""  ABS,ESC
 SG_ _4H_ACT : 41|1@1+ (1.0,0.0) [0.0|1.0] ""  ABS,CLU,ESC,TPMS
 SG_ LOW_ACT : 42|1@1+ (1.0,0.0) [0.0|1.0] ""  ABS,ESC,TCU,TPMS
 SG_ AUTO_ACT : 43|1@1+ (1.0,0.0) [0.0|1.0] ""  ABS,ESC,TPMS
 SG_ LOCK_ACT : 44|1@1+ (1.0,0.0) [0.0|1.0] ""  ABS,CLU,ESC,TPMS
 SG_ _4WD_TQC_CUR : 48|16@1+ (1.0,0.0) [0.0|65535.0] "Nm"  ABS,ESC

BO_ 1319 HU_GW_E_01: 8 CLU
 SG_ C_ADrLNValueSet : 0|3@1+ (1.0,0.0) [0.0|7.0] ""  BCM
 SG_ C_ADrUNValueSet : 4|3@1+ (1.0,0.0) [0.0|7.0] ""  BCM
 SG_ C_TwUnNValueSet : 8|2@1+ (1.0,0.0) [0.0|3.0] ""  BCM
 SG_ C_ABuzzerNValueSet : 10|2@1+ (1.0,0.0) [0.0|3.0] ""  BCM
 SG_ C_ArmWKeyNValueSet : 12|2@1+ (1.0,0.0) [0.0|3.0] ""  BCM
 SG_ C_PSMNValueSet : 14|2@1+ (1.0,0.0) [0.0|3.0] ""  BCM
 SG_ C_SCMNValueSet : 16|2@1+ (1.0,0.0) [0.0|3.0] ""  BCM
 SG_ C_HLEscortNValueSet : 18|2@1+ (1.0,0.0) [0.0|3.0] ""  BCM
 SG_ C_WELNValueSet : 20|2@1+ (1.0,0.0) [0.0|3.0] ""  BCM
 SG_ C_TriTurnLNValueSet : 22|2@1+ (1.0,0.0) [0.0|3.0] ""  BCM
 SG_ C_SNVWarnNValueSet : 24|2@1+ (1.0,0.0) [0.0|3.0] ""  BCM
 SG_ C_LkasWarnNValueSet : 26|2@1+ (1.0,0.0) [0.0|3.0] ""  BCM

CM_ SG_ 871 CF_Lvr_IsgState "Idle Stop and Go";
